VERSION ""

NS_ :

BS_:

BU_: WCM4 WCM3 WCM2 WCM VPM VLM VKM VICM VECM VDM VCU_RTOS_ETH VCU_ENTRY_ETH VCU_AGVM_ETH VCU UVM UPM TIM TEST_TOOL_1 TCP_ETH TCP TCM TCCM SRR_SRR_ETH SRR_SRR SRR_SLR_ETH SRR_SLR SRR_RR SRR_RF_ETH SRR_RF SRR_LR_CR SRR_LF_ETH SRR_LF SIB SDM SCL SBZA_R SBZA_L SBM SAM_RR SAM_RF SAM_LR SAM_LF SAM_BH SADS RadioLow_ETH RadioLow RSI_RTOS_ETH RSI RDCM PTM PLCM PFCM PDR_ETH PDR PCM PA ODS2 ODS NVM MTCM_R MTCM_L MSM_RR MSM_P MSM_LR MSM_D MSB2 MSB1 MRCM_R MRCM_L MFC LRR_RR_ETH LRR_LR_ETH LRR_CF_ETH LRR LRL_CF_ETH LIB_48V LIB1 IPC_INT IPC_GP IPC ICS_Info ICCM HVAC_FP_R HVAC_FP_F HUD_CAN HDLM FPI_RTOS_ETH FPI FOPM FCM_LC FCM EPSb EPS_1 EPSRAb EPSRAa EPS EOCM_HC_Superset EOCM_HCP2 EOCM ELM ECP_X1 ECP_S2 ECP_S ECP_MC ECP_H3 ECP_H2 ECP_H1 ECP_E ECM EBCM DMS DEFC DCM CSM_ETH CSM_AV CSM CGM_OTA_ETH CGM BSM_MH BSM_HEV BSM BCM ARS ARB APA AOS AMP ALC AHS AHL_AFL ADIMb ADIMa ACP2_MCU

BO_ 21 SrlDat199_Prtctd_PDU: 32 SRR_SRR
 SG_ SD199P_MAC : 7|32@0+ (1,0) [0|4.29497e+009] "" SRR_SLR
 SG_ SD199P_FCnt : 39|5@0+ (1,0) [0|31] "" SRR_SLR
 SG_ SRRSRRODPTOVYawRate : 47|11@0+ (0.002,0) [0|4.094] "(rad/s)^2" SRR_SLR
 SG_ SRRSRRODPTrObjYawRate : 52|11@0- (0.002,0) [-2.048|2.046] "rad/s" SRR_SLR
 SG_ SRRSRRODPTrObjOrntn : 57|10@0- (0.01,0) [-5.12|5.11] "rad" SRR_SLR
 SG_ SRRSRRODPTODTrHtchTrFrt : 79|8@0- (0.1,0) [-12.8|12.7] "m" SRR_SLR
 SG_ SRRSRRODPTOVLgth : 87|8@0+ (0.1,0) [0|25.5] "m^2" SRR_SLR
 SG_ SRRSRRODPTOVOrntn : 95|8@0+ (0.01,0) [0|2.55] "rad^2" SRR_SLR
 SG_ SRRSRRODPTOVWdth : 103|8@0+ (0.1,0) [0|25.5] "m^2" SRR_SLR
 SG_ SRRSRRODPTrObjLgth : 111|8@0+ (0.1,0) [0|25.5] "m" SRR_SLR
 SG_ SRRSRRODPTODVhFrtAxVhHtch : 112|7@0+ (0.1,0) [0|12.7] "m" SRR_SLR
 SG_ SRRSRRODPTODTrHtchTrAx : 119|7@0+ (0.1,0) [0|12.7] "m" SRR_SLR
 SG_ SRRSRRODPTOEExistPrblty : 121|7@0+ (0.01,0) [0|1.27] "" SRR_SLR
 SG_ SRRSRRODPTOPDtnPrblty : 130|7@0+ (0.01,0) [0|1.27] "" SRR_SLR
 SG_ SRRSRRODPTrObjQlty : 139|7@0+ (1,0) [0|127] "%" SRR_SLR
 SG_ SRRSRRODPTOVDTrHtchTrAx : 148|6@0+ (0.1,0) [0|6.3] "m^2" SRR_SLR
 SG_ SRRSRRODPTOVDVhFrtAxVhHtch : 152|6@0+ (0.1,0) [0|6.3] "m^2" SRR_SLR
 SG_ SRRSRRODPTOVDTrHtchTrFrt : 158|6@0+ (0.1,0) [0|6.3] "m^2" SRR_SLR
 SG_ SRRSRRODPTrObjWdth : 162|6@0+ (0.1,0) [0|6.3] "m" SRR_SLR
 SG_ SRRSRRODPTrObjStatInfo : 169|3@0+ (1,0) [0|4] "" SRR_SLR
 SG_ SRRSRRODPTrObjExtrnInfo : 172|3@0+ (1,0) [0|7] "" SRR_SLR
 SG_ SRRSRRODPTOPDtnPrblty_Inv : 176|1@0+ (1,0) [0|1] "" SRR_SLR
 SG_ SRRSRRODPTOEExistPrblty_Inv : 177|1@0+ (1,0) [0|1] "" SRR_SLR
 SG_ SRRSRRODPTODVhFrtAxVhHtch_Inv : 178|1@0+ (1,0) [0|1] "" SRR_SLR
 SG_ SRRSRRODPTODTrHtchTrFrt_Inv : 179|1@0+ (1,0) [0|1] "" SRR_SLR
 SG_ SRRSRRODPTODTrHtchTrAx_Inv : 180|1@0+ (1,0) [0|1] "" SRR_SLR
 SG_ SRRSRRODPTrAtchdInfo : 182|2@0+ (1,0) [0|3] "" SRR_SLR
 SG_ SRRSRRODPTrObjExtrnInfo_Inv : 184|1@0+ (1,0) [0|1] "" SRR_SLR
 SG_ SRRSRRODPTOVYawRate_Inv : 185|1@0+ (1,0) [0|1] "" SRR_SLR
 SG_ SRRSRRODPTOVWdth_Inv : 186|1@0+ (1,0) [0|1] "" SRR_SLR
 SG_ SRRSRRODPTOVOrntn_Inv : 187|1@0+ (1,0) [0|1] "" SRR_SLR
 SG_ SRRSRRODPTOVLgth_Inv : 188|1@0+ (1,0) [0|1] "" SRR_SLR
 SG_ SRRSRRODPTOVDVhFrtAxVhHtch_Inv : 189|1@0+ (1,0) [0|1] "" SRR_SLR
 SG_ SRRSRRODPTOVDTrHtchTrFrt_Inv : 190|1@0+ (1,0) [0|1] "" SRR_SLR
 SG_ SRRSRRODPTOVDTrHtchTrAx_Inv : 191|1@0+ (1,0) [0|1] "" SRR_SLR
 SG_ SrlDat199_Filler : 194|32@0+ (1,0) [0|4.29497e+009] "" SRR_SLR
 SG_ SRRSRRODPTrObjYawRate_Inv : 195|1@0+ (1,0) [0|1] "" SRR_SLR
 SG_ SRRSRRODPTrObjWdth_Inv : 196|1@0+ (1,0) [0|1] "" SRR_SLR
 SG_ SRRSRRODPTrObjQlty_Inv : 197|1@0+ (1,0) [0|1] "" SRR_SLR
 SG_ SRRSRRODPTrObjOrntn_Inv : 198|1@0+ (1,0) [0|1] "" SRR_SLR
 SG_ SRRSRRODPTrObjLgth_Inv : 199|1@0+ (1,0) [0|1] "" SRR_SLR
 SG_ SrlDat199_FillerExtnd : 226|25@0+ (1,0) [0|3.35544e+007] "" SRR_SLR
 SG_ SD199P_ARC : 249|2@0+ (1,0) [0|3] "" SRR_SLR

BO_ 543 SrlDat200_PCSM_PDU: 8 SRR_RR
 SG_ SrlDat200_PCSM : 0|64@1+ (1,0) [0|1.84467e+019] "" SRR_LR_CR

BO_ 20 SrlDat200_Prtctd_PDU: 32 SRR_RR
 SG_ SD200P_MAC : 7|32@0+ (1,0) [0|4.29497e+009] "" SRR_LR_CR
 SG_ SD200P_FCnt : 39|5@0+ (1,0) [0|31] "" SRR_LR_CR
 SG_ SRRRRODPTOVYawRate : 47|11@0+ (0.002,0) [0|4.094] "(rad/s)^2" SRR_LR_CR
 SG_ SRRRRODPTrObjYawRate : 52|11@0- (0.002,0) [-2.048|2.046] "rad/s" SRR_LR_CR
 SG_ SRRRRODPTrObjOrntn : 57|10@0- (0.01,0) [-5.12|5.11] "rad" SRR_LR_CR
 SG_ SRRRRODPTODTrHtchTrFrt : 79|8@0- (0.1,0) [-12.8|12.7] "m" SRR_LR_CR
 SG_ SRRRRODPTOVLgth : 87|8@0+ (0.1,0) [0|25.5] "m^2" SRR_LR_CR
 SG_ SRRRRODPTOVOrntn : 95|8@0+ (0.01,0) [0|2.55] "rad^2" SRR_LR_CR
 SG_ SRRRRODPTOVWdth : 103|8@0+ (0.1,0) [0|25.5] "m^2" SRR_LR_CR
 SG_ SRRRRODPTrObjLgth : 111|8@0+ (0.1,0) [0|25.5] "m" SRR_LR_CR
 SG_ SRRRRODPTODVhFrtAxVhHtch : 112|7@0+ (0.1,0) [0|12.7] "m" SRR_LR_CR
 SG_ SRRRRODPTODTrHtchTrAx : 119|7@0+ (0.1,0) [0|12.7] "m" SRR_LR_CR
 SG_ SRRRRODPTOEExistPrblty : 121|7@0+ (0.01,0) [0|1.27] "" SRR_LR_CR
 SG_ SRRRRODPTOPDtnPrblty : 130|7@0+ (0.01,0) [0|1.27] "" SRR_LR_CR
 SG_ SRRRRODPTrObjQlty : 139|7@0+ (1,0) [0|127] "%" SRR_LR_CR
 SG_ SRRRRODPTOVDTrHtchTrAx : 148|6@0+ (0.1,0) [0|6.3] "m^2" SRR_LR_CR
 SG_ SRRRRODPTOVDVhFrtAxVhHtch : 152|6@0+ (0.1,0) [0|6.3] "m^2" SRR_LR_CR
 SG_ SRRRRODPTOVDTrHtchTrFrt : 158|6@0+ (0.1,0) [0|6.3] "m^2" SRR_LR_CR
 SG_ SRRRRODPTrObjWdth : 162|6@0+ (0.1,0) [0|6.3] "m" SRR_LR_CR
 SG_ SRRRRODPTrObjStatInfo : 169|3@0+ (1,0) [0|4] "" SRR_LR_CR
 SG_ SRRRRODPTrObjExtrnInfo : 172|3@0+ (1,0) [0|7] "" SRR_LR_CR
 SG_ SRRRRODPTOPDtnPrblty_Inv : 176|1@0+ (1,0) [0|1] "" SRR_LR_CR
 SG_ SRRRRODPTOEExistPrblty_Inv : 177|1@0+ (1,0) [0|1] "" SRR_LR_CR
 SG_ SRRRRODPTODVhFrtAxVhHtch_Inv : 178|1@0+ (1,0) [0|1] "" SRR_LR_CR
 SG_ SRRRRODPTODTrHtchTrFrt_Inv : 179|1@0+ (1,0) [0|1] "" SRR_LR_CR
 SG_ SRRRRODPTODTrHtchTrAx_Inv : 180|1@0+ (1,0) [0|1] "" SRR_LR_CR
 SG_ SRRRRODPTrAtchdInfo : 182|2@0+ (1,0) [0|3] "" SRR_LR_CR
 SG_ SRRRRODPTrObjExtrnInfo_Inv : 184|1@0+ (1,0) [0|1] "" SRR_LR_CR
 SG_ SRRRRODPTOVYawRate_Inv : 185|1@0+ (1,0) [0|1] "" SRR_LR_CR
 SG_ SRRRRODPTOVWdth_Inv : 186|1@0+ (1,0) [0|1] "" SRR_LR_CR
 SG_ SRRRRODPTOVOrntn_Inv : 187|1@0+ (1,0) [0|1] "" SRR_LR_CR
 SG_ SRRRRODPTOVLgth_Inv : 188|1@0+ (1,0) [0|1] "" SRR_LR_CR
 SG_ SRRRRODPTOVDVhFrtAxVhHtch_Inv : 189|1@0+ (1,0) [0|1] "" SRR_LR_CR
 SG_ SRRRRODPTOVDTrHtchTrFrt_Inv : 190|1@0+ (1,0) [0|1] "" SRR_LR_CR
 SG_ SRRRRODPTOVDTrHtchTrAx_Inv : 191|1@0+ (1,0) [0|1] "" SRR_LR_CR
 SG_ SrlDat200_Filler : 194|32@0+ (1,0) [0|4.29497e+009] "" SRR_LR_CR
 SG_ SRRRRODPTrObjYawRate_Inv : 195|1@0+ (1,0) [0|1] "" SRR_LR_CR
 SG_ SRRRRODPTrObjWdth_Inv : 196|1@0+ (1,0) [0|1] "" SRR_LR_CR
 SG_ SRRRRODPTrObjQlty_Inv : 197|1@0+ (1,0) [0|1] "" SRR_LR_CR
 SG_ SRRRRODPTrObjOrntn_Inv : 198|1@0+ (1,0) [0|1] "" SRR_LR_CR
 SG_ SRRRRODPTrObjLgth_Inv : 199|1@0+ (1,0) [0|1] "" SRR_LR_CR
 SG_ SrlDat200_FillerExtnd : 226|25@0+ (1,0) [0|3.35544e+007] "" SRR_LR_CR
 SG_ SD200P_ARC : 249|2@0+ (1,0) [0|3] "" SRR_LR_CR

BO_ 906 SrlDat20_PCSM_PDU: 8 CGM
 SG_ SrlDat20_PCSM : 0|64@1+ (1,0) [0|1.84467e+019] "" FCM_LC

BO_ 226 SrlDat20_Prtctd_PDU: 20 CGM
 SG_ SD20P_MAC : 7|32@0+ (1,0) [0|4.29497e+009] "" FCM_LC
 SG_ SD20P_FCnt : 39|5@0+ (1,0) [0|31] "" FCM_LC
 SG_ DIATMNP_DrvrIntdAxlTqMnAuth : 47|15@0+ (2,-22534) [-22534|43000] "Nm" FCM_LC
 SG_ DIATMNP_DrvrIntdAxlTqMnAuth_Inv : 48|1@0+ (1,0) [0|1] "" FCM_LC
 SG_ DIATMXP_DrvrIntdAxlTqMxAuth : 63|15@0+ (2,-22534) [-22534|43000] "Nm" FCM_LC
 SG_ DIATMXP_DrvrIntdAxlTqMxAuth_Inv : 64|1@0+ (1,0) [0|1] "" FCM_LC
 SG_ DITP_DrvrIntndAxlTrqAuth : 79|15@0+ (2,-22534) [-22534|43000] "Nm" FCM_LC
 SG_ DITP_DrvrIntndAxlTrqAuth_Inv : 80|1@0+ (1,0) [0|1] "" FCM_LC
 SG_ DITP_DrvrIntndCrksftTrqAuth : 95|12@0+ (0.5,-848) [-848|1199.5] "Nm" FCM_LC
 SG_ VMI1P_AccelActlPstnAuth : 99|8@0+ (0.392157,0) [0|100] "%" FCM_LC,SRR_SLR,SRR_SRR
 SG_ VMI1P_VehTopSpdLimArbdValAuth : 105|8@0+ (2,0) [0|510] "km / h" FCM_LC
 SG_ VMI1P_AccelPedOvrrdActvAuth : 106|1@0+ (1,0) [0|1] "" FCM_LC
 SG_ VMI1P_AccelActlPstnAuth_Inv : 107|1@0+ (1,0) [0|1] "" FCM_LC
 SG_ SD20P_ARC : 112|2@0+ (1,0) [0|3] "" FCM_LC
 SG_ VMI1P_VehTopSpdLimModeActvAuth : 113|1@0+ (1,0) [0|1] "" FCM_LC
 SG_ VehSpdAvgNDrvn : 126|15@0+ (0.015625,0) [0|511.984] "Km/h" FCM_LC
 SG_ SD20P_Filler : 142|23@0+ (1,0) [0|8.38861e+006] "" FCM_LC
 SG_ VehSpdAvgNDrvn_Inv : 143|1@0+ (1,0) [0|1] "" FCM_LC

BO_ 1404 SrlDat22_PCSM_PDU: 8 CGM
 SG_ SrlDat22_PCSM : 0|64@1+ (1,0) [0|1.84467e+019] "" HDLM,UPM

BO_ 879 SrlDat22_Prtctd_PDU: 8 CGM
 SG_ SD22P_MAC : 7|27@0+ (1,0) [0|1.34218e+008] "" HDLM,UPM
 SG_ SD22P_FCnt : 28|5@0+ (1,0) [0|31] "" HDLM,UPM
 SG_ EGI3P_CnvtTpSpLimRspValAuth : 36|8@0+ (2,0) [0|510] "kph" HDLM,UPM
 SG_ EGI3P_CnvtTpSpLimRspTypAuth : 39|3@0+ (1,0) [0|6] "" HDLM,UPM
 SG_ PSP_PrkNeutSwStatAuth_Inv : 40|1@0+ (1,0) [0|1] "" HDLM,UPM
 SG_ PSP_PrkNeutSwStatAuth : 41|1@0+ (1,0) [0|1] "" HDLM,UPM
 SG_ PSP_EngRnngAuth : 42|1@0+ (1,0) [0|1] "" EOCM_HCP2,FCM_LC,HDLM,LRR,SRR_LF,SRR_LR_CR,SRR_RF,SRR_RR,SRR_SLR,SRR_SRR,UPM
 SG_ PSP_ClchBtmTrvlAchvdAuth_Inv : 43|1@0+ (1,0) [0|1] "" HDLM,UPM
 SG_ PSP_ClchBtmTrvlAchvdAuth : 44|1@0+ (1,0) [0|1] "" HDLM,UPM
 SG_ SD22P_ARC : 49|2@0+ (1,0) [0|3] "" HDLM,UPM
 SG_ PSP_VehTheftImbChlgRespStsAuth : 51|2@0+ (1,0) [0|2] "" HDLM,UPM
 SG_ PSP_RmtVehStrtEngRnngAuth : 52|1@0+ (1,0) [0|1] "" HDLM,UPM
 SG_ PSP_PwrtrnCrnkAbrtdAuth : 53|1@0+ (1,0) [0|1] "" HDLM,UPM
 SG_ PSP_PrplSysStlActvAuth : 54|1@0+ (1,0) [0|1] "" HDLM,UPM
 SG_ PSP_PrplSysActvAuth : 55|1@0+ (1,0) [0|1] "" FCM_LC,HDLM,LRR,SRR_LF,SRR_LR_CR,SRR_RF,SRR_RR,SRR_SLR,SRR_SRR,UPM
 SG_ SD22P_Filler : 62|7@0+ (1,0) [0|127] "" HDLM,UPM
 SG_ PrplBrkThrotOvrrdReqd : 63|1@0+ (1,0) [0|1] "" HDLM,UPM

BO_ 72 SrlDat30_Prtctd_PDU: 8 CGM
 SG_ SD30P_MAC : 7|27@0+ (1,0) [0|1.34218e+008] "" Vector__XXX
 SG_ SD30P_FCnt : 28|5@0+ (1,0) [0|31] "" Vector__XXX
 SG_ TGIP_TrnsEgdPrFlwStAuth : 33|3@0+ (1,0) [0|3] "" Vector__XXX
 SG_ TARSP_TransActlRngAuth_Inv : 34|1@0+ (1,0) [0|1] "" Vector__XXX
 SG_ TARSP_TransActlRngAuth_DuD : 35|1@0+ (1,0) [0|1] "" Vector__XXX
 SG_ TARSP_TransActlRngAuth : 39|4@0+ (1,0) [0|13] "" UPM
 SG_ TRDP_TrnsPkRgDgLtFltAuth : 40|1@0+ (1,0) [0|1] "" Vector__XXX
 SG_ TRDP_TrnsPkRgDgCtFltAuth : 41|1@0+ (1,0) [0|1] "" Vector__XXX
 SG_ TRDP_TrnsNtRgDgLtFltAuth : 42|1@0+ (1,0) [0|1] "" Vector__XXX
 SG_ TRDP_TrnsNtRgDgCtFltAuth : 43|1@0+ (1,0) [0|1] "" Vector__XXX
 SG_ TRDP_TrnsFwDrvRDLFltAuth : 44|1@0+ (1,0) [0|1] "" Vector__XXX
 SG_ TRDP_TrnsFwDrvRDCFltAuth : 45|1@0+ (1,0) [0|1] "" Vector__XXX
 SG_ TGIP_TrnsEgdPrFlwStAuth_Inv : 46|1@0+ (1,0) [0|1] "" Vector__XXX
 SG_ SD30P_Filler : 49|10@0+ (1,0) [0|1023] "" Vector__XXX
 SG_ SD30P_ARC : 51|2@0+ (1,0) [0|3] "" Vector__XXX
 SG_ TSP_TmpDrvrShfCtlActvAuth : 52|1@0+ (1,0) [0|1] "" Vector__XXX
 SG_ TSP_ElecRngSeltnInDrvActvAuth : 53|1@0+ (1,0) [0|1] "" Vector__XXX
 SG_ TRDP_TrnsRvRgDgLtFltAuth : 54|1@0+ (1,0) [0|1] "" Vector__XXX
 SG_ TRDP_TrnsRvRgDgCtFltAuth : 55|1@0+ (1,0) [0|1] "" Vector__XXX

BO_ 897 SrlDat46_PCSM_PDU: 8 CGM
 SG_ SrlDat46_PCSM : 0|64@1+ (1,0) [0|1.84467e+019] "" ACP2_MCU,FCM_LC

BO_ 57 SrlDat46_Prtctd_PDU: 20 CGM
 SG_ SD46P_MAC : 7|32@0+ (1,0) [0|4.29497e+009] "" ACP2_MCU,FCM_LC
 SG_ SD46P_FCnt : 39|5@0+ (1,0) [0|31] "" ACP2_MCU,FCM_LC
 SG_ LatAccelAuth : 47|10@0- (0.0625,0) [-32|31.9375] "m/s^2" ACP2_MCU,FCM_LC
 SG_ LongAccelAuth : 50|10@0- (0.0625,0) [-32|31.9375] "m/s^2" ACP2_MCU,FCM_LC
 SG_ LatAccelSnsrCorrStsAuth : 52|2@0+ (1,0) [0|3] "" ACP2_MCU,FCM_LC
 SG_ LatAccelAuth_Inv : 53|1@0+ (1,0) [0|1] "" ACP2_MCU,FCM_LC
 SG_ LongAccelAuth_Inv : 56|1@0+ (1,0) [0|1] "" ACP2_MCU,FCM_LC
 SG_ YRP_RollRateAuth : 68|13@0- (0.024,0) [-98.304|98.28] "Deg/Sec" ACP2_MCU,FCM_LC
 SG_ VehAccelCalAuth : 69|1@0+ (1,0) [0|1] "" ACP2_MCU,FCM_LC
 SG_ LongAccelSnsrCorrStsAuth : 71|2@0+ (1,0) [0|3] "" ACP2_MCU,FCM_LC
 SG_ YawRateAuth : 85|13@0- (0.024,0) [-98.304|98.28] "Deg/Sec" ACP2_MCU,FCM_LC,SRR_LR_CR,SRR_RR,SRR_SLR,SRR_SRR
 SG_ YRP_RollRateAuth_Inv : 86|1@0+ (1,0) [0|1] "" ACP2_MCU,FCM_LC
 SG_ YRP_RollRateAuth_DuD : 87|1@0+ (1,0) [0|1] "" ACP2_MCU,FCM_LC
 SG_ YawRateAuth_DuD : 88|1@0+ (1,0) [0|1] "" ACP2_MCU,FCM_LC
 SG_ SD46P_Filler : 98|32@0+ (1,0) [0|4.29497e+009] "" ACP2_MCU,FCM_LC
 SG_ SD46P_ARC : 100|2@0+ (1,0) [0|3] "" ACP2_MCU,FCM_LC
 SG_ YawRateCorrAuth : 102|2@0+ (1,0) [0|3] "" ACP2_MCU,FCM_LC
 SG_ YawRateAuth_Inv : 103|1@0+ (1,0) [0|1] "" ACP2_MCU,FCM_LC,SRR_LR_CR,SRR_RR,SRR_SLR,SRR_SRR
 SG_ SD46P_FillerExtnd : 130|26@0+ (1,0) [0|6.71089e+007] "" ACP2_MCU,FCM_LC
 SG_ VehAccelAuth_DuD : 152|1@0+ (1,0) [0|1] "" ACP2_MCU,FCM_LC

BO_ 1403 SysPwrMode_PCSM_PDU: 8 CGM
 SG_ SysPwrMode_PCSM : 0|64@1+ (1,0) [0|1.84467e+019] "" EOCM_HCP2,FCM_LC,HDLM,LRR,SRR_LF,SRR_LR_CR,SRR_RF,SRR_RR,SRR_SLR,SRR_SRR,UPM

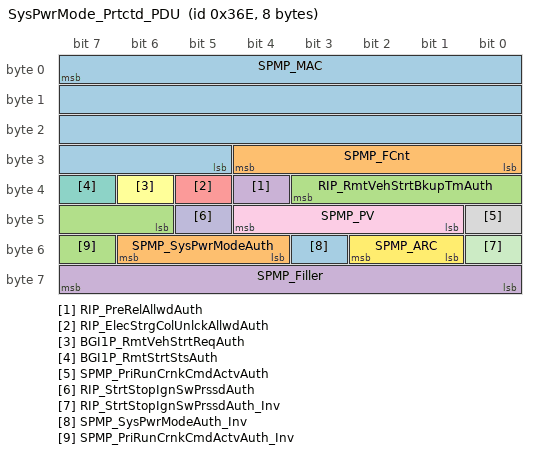
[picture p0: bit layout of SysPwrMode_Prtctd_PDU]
BO_ 878 SysPwrMode_Prtctd_PDU: 8 CGM
 SG_ SPMP_MAC : 7|27@0+ (1,0) [0|1.34218e+008] "" EOCM_HCP2,FCM_LC,HDLM,LRR,SRR_LF,SRR_LR_CR,SRR_RF,SRR_RR,SRR_SLR,SRR_SRR,UPM
 SG_ SPMP_FCnt : 28|5@0+ (1,0) [0|31] "" EOCM_HCP2,FCM_LC,HDLM,LRR,SRR_LF,SRR_LR_CR,SRR_RF,SRR_RR,SRR_SLR,SRR_SRR,UPM
 SG_ RIP_RmtVehStrtBkupTmAuth : 35|6@0+ (1,0) [0|63] "min" EOCM_HCP2,FCM_LC,HDLM,LRR,SRR_LF,SRR_LR_CR,SRR_RF,SRR_RR,SRR_SLR,SRR_SRR,UPM
 SG_ RIP_PreRelAllwdAuth : 36|1@0+ (1,0) [0|1] "" EOCM_HCP2,FCM_LC,HDLM,LRR,SRR_LF,SRR_LR_CR,SRR_RF,SRR_RR,SRR_SLR,SRR_SRR,UPM
 SG_ RIP_ElecStrgColUnlckAllwdAuth : 37|1@0+ (1,0) [0|1] "" EOCM_HCP2,FCM_LC,HDLM,LRR,SRR_LF,SRR_LR_CR,SRR_RF,SRR_RR,SRR_SLR,SRR_SRR,UPM
 SG_ BGI1P_RmtVehStrtReqAuth : 38|1@0+ (1,0) [0|1] "" EOCM_HCP2,FCM_LC,HDLM,LRR,SRR_LF,SRR_LR_CR,SRR_RF,SRR_RR,SRR_SLR,SRR_SRR,UPM
 SG_ BGI1P_RmtStrtStsAuth : 39|1@0+ (1,0) [0|1] "" EOCM_HCP2,FCM_LC,HDLM,LRR,SRR_LF,SRR_LR_CR,SRR_RF,SRR_RR,SRR_SLR,SRR_SRR,UPM
 SG_ SPMP_PriRunCrnkCmdActvAuth : 40|1@0+ (1,0) [0|1] "" EOCM_HCP2,FCM_LC,HDLM,LRR,SRR_LF,SRR_LR_CR,SRR_RF,SRR_RR,SRR_SLR,SRR_SRR,UPM
 SG_ SPMP_PV : 44|4@0+ (1,0) [0|15] "" EOCM_HCP2,FCM_LC,HDLM,LRR,SRR_LF,SRR_LR_CR,SRR_RF,SRR_RR,SRR_SLR,SRR_SRR,UPM
 SG_ RIP_StrtStopIgnSwPrssdAuth : 45|1@0+ (1,0) [0|1] "" EOCM_HCP2,FCM_LC,HDLM,LRR,SRR_LF,SRR_LR_CR,SRR_RF,SRR_RR,SRR_SLR,SRR_SRR,UPM
 SG_ RIP_StrtStopIgnSwPrssdAuth_Inv : 48|1@0+ (1,0) [0|1] "" EOCM_HCP2,FCM_LC,HDLM,LRR,SRR_LF,SRR_LR_CR,SRR_RF,SRR_RR,SRR_SLR,SRR_SRR,UPM
 SG_ SPMP_ARC : 50|2@0+ (1,0) [0|3] "" EOCM_HCP2,FCM_LC,HDLM,LRR,SRR_LF,SRR_LR_CR,SRR_RF,SRR_RR,SRR_SLR,SRR_SRR,UPM
 SG_ SPMP_SysPwrModeAuth_Inv : 51|1@0+ (1,0) [0|1] "" EOCM_HCP2,FCM_LC,HDLM,LRR,SRR_LF,SRR_LR_CR,SRR_RF,SRR_RR,SRR_SLR,SRR_SRR,UPM
 SG_ SPMP_SysPwrModeAuth : 54|3@0+ (1,0) [0|4] "" EOCM_HCP2,FCM_LC,HDLM,LRR,SRR_LF,SRR_LR_CR,SRR_RF,SRR_RR,SRR_SLR,SRR_SRR,UPM
 SG_ SPMP_PriRunCrnkCmdActvAuth_Inv : 55|1@0+ (1,0) [0|1] "" EOCM_HCP2,FCM_LC,HDLM,LRR,SRR_LF,SRR_LR_CR,SRR_RF,SRR_RR,SRR_SLR,SRR_SRR,UPM
 SG_ SPMP_Filler : 63|8@0+ (1,0) [0|255] "" EOCM_HCP2,FCM_LC,HDLM,LRR,SRR_LF,SRR_LR_CR,SRR_RF,SRR_RR,SRR_SLR,SRR_SRR,UPM

BO_ 122 Tp_SrlDat185_Data_PDU: 2680 SRR_LR_CR
 SG_ SRRLRCODPREOTk1CrvAuth : 7|16@0- (9.77e-07,0) [-0.0320143|0.0320134] "1/m" Vector__XXX
 SG_ SRRLRCODPREOTk1CrvDrvtAuth : 23|16@0- (3.73e-09,0) [-0.000122225|0.000122221] "1/m2" Vector__XXX
 SG_ SRRLRCODPREOTk2CrvAuth : 39|16@0- (9.77e-07,0) [-0.0320143|0.0320134] "1/m" Vector__XXX
 SG_ SRRLRCODPREOTk2CrvDrvtAuth : 55|16@0- (3.73e-09,0) [-0.000122225|0.000122221] "1/m2" Vector__XXX
 SG_ SRRLRCODPREOTk3CrvAuth : 71|16@0- (9.77e-07,0) [-0.0320143|0.0320134] "1/m" Vector__XXX
 SG_ SRRLRCODPREOTk3CrvDrvtAuth : 87|16@0- (3.73e-09,0) [-0.000122225|0.000122221] "1/m2" Vector__XXX
 SG_ SRRLRCODPVOTk10PoILgPsCAuth : 103|16@0+ (0.01,0) [0|655.35] "m^2" Vector__XXX
 SG_ SRRLRCODPVOTk1PoILgPsCAuth : 119|16@0+ (0.01,0) [0|655.35] "m^2" Vector__XXX
 SG_ SRRLRCODPVOTk2PoILgPsCAuth : 135|16@0+ (0.01,0) [0|655.35] "m^2" Vector__XXX
 SG_ SRRLRCODPVOTk3PoILgPsCAuth : 151|16@0+ (0.01,0) [0|655.35] "m^2" Vector__XXX
 SG_ SRRLRCODPVOTk4PoILgPsCAuth : 167|16@0+ (0.01,0) [0|655.35] "m^2" Vector__XXX
 SG_ SRRLRCODPVOTk5PoILgPsCAuth : 183|16@0+ (0.01,0) [0|655.35] "m^2" Vector__XXX
 SG_ SRRLRCODPVOTk6PoILgPsCAuth : 199|16@0+ (0.01,0) [0|655.35] "m^2" Vector__XXX
 SG_ SRRLRCODPVOTk7PoILgPsCAuth : 215|16@0+ (0.01,0) [0|655.35] "m^2" Vector__XXX
 SG_ SRRLRCODPVOTk8PoILgPsCAuth : 231|16@0+ (0.01,0) [0|655.35] "m^2" Vector__XXX
 SG_ SRRLRCODPVOTk9PoILgPsCAuth : 247|16@0+ (0.01,0) [0|655.35] "m^2" Vector__XXX
 SG_ SRRLRCODPVOTk10PoILPsCAuth : 263|14@0+ (0.01,0) [0|163.83] "m^2" Vector__XXX
 SG_ SRRLRCODPVOTk1PoILPsCAuth : 265|14@0+ (0.01,0) [0|163.83] "m^2" Vector__XXX
 SG_ SRRLRCODPVOTk2PoILPsCAuth : 283|14@0+ (0.01,0) [0|163.83] "m^2" Vector__XXX
 SG_ SRRLRCODPVOTk3PoILPsCAuth : 301|14@0+ (0.01,0) [0|163.83] "m^2" Vector__XXX
 SG_ SRRLRCODPVOTk4PoILPsCAuth : 319|14@0+ (0.01,0) [0|163.83] "m^2" Vector__XXX
 SG_ SRRLRCODPVOTk5PoILPsCAuth : 321|14@0+ (0.01,0) [0|163.83] "m^2" Vector__XXX
 SG_ SRRLRCODPVOTk6PoILPsCAuth : 339|14@0+ (0.01,0) [0|163.83] "m^2" Vector__XXX
 SG_ SRRLRCODPVOTk7PoILPsCAuth : 357|14@0+ (0.01,0) [0|163.83] "m^2" Vector__XXX
 SG_ SRRLRCODPVOTk8PoILPsCAuth : 375|14@0+ (0.01,0) [0|163.83] "m^2" Vector__XXX
 SG_ SRRLRCODPVOTk9PoILPsCAuth : 377|14@0+ (0.01,0) [0|163.83] "m^2" Vector__XXX
 SG_ SRRLRCODPAcqTmStmAuth : 395|11@0+ (1,0) [0|2047] "ms" Vector__XXX
 SG_ SRRLRCODPIOTk10PoILgPsAuth : 400|11@0- (0.125,0) [-128|127.875] "m" Vector__XXX
 SG_ SRRLRCODPIOTk1PoILgPsAuth : 421|11@0- (0.125,0) [-128|127.875] "m" Vector__XXX
 SG_ SRRLRCODPIOTk2PoILgPsAuth : 426|11@0- (0.125,0) [-128|127.875] "m" Vector__XXX
 SG_ SRRLRCODPIOTk3PoILgPsAuth : 447|11@0- (0.125,0) [-128|127.875] "m" Vector__XXX
 SG_ SRRLRCODPIOTk4PoILgPsAuth : 452|11@0- (0.125,0) [-128|127.875] "m" Vector__XXX
 SG_ SRRLRCODPIOTk5PoILgPsAuth : 457|11@0- (0.125,0) [-128|127.875] "m" Vector__XXX
 SG_ SRRLRCODPIOTk6PoILgPsAuth : 478|11@0- (0.125,0) [-128|127.875] "m" Vector__XXX
 SG_ SRRLRCODPIOTk7PoILgPsAuth : 483|11@0- (0.125,0) [-128|127.875] "m" Vector__XXX
 SG_ SRRLRCODPIOTk8PoILgPsAuth : 488|11@0- (0.125,0) [-128|127.875] "m" Vector__XXX
 SG_ SRRLRCODPIOTk9PoILgPsAuth : 509|11@0- (0.125,0) [-128|127.875] "m" Vector__XXX
 SG_ SRRLRCODPPOTk1PoILgPsAuth : 514|11@0- (0.125,0) [-128|127.875] "m" Vector__XXX
 SG_ SRRLRCODPPOTk2PoILgPsAuth : 535|11@0- (0.125,0) [-128|127.875] "m" Vector__XXX
 SG_ SRRLRCODPPOTk3PoILgPsAuth : 540|11@0- (0.125,0) [-128|127.875] "m" Vector__XXX
 SG_ SRRLRCODPPOTk4PoILgPsAuth : 545|11@0- (0.125,0) [-128|127.875] "m" Vector__XXX
 SG_ SRRLRCODPPOTk5PoILgPsAuth : 566|11@0- (0.125,0) [-128|127.875] "m" Vector__XXX
 SG_ SRRLRCODPREOTk1PsEndAuth : 571|11@0- (0.125,0) [-128|127.875] "m" Vector__XXX
 SG_ SRRLRCODPREOTk1PsStrtAuth : 576|11@0- (0.125,0) [-128|127.875] "m" Vector__XXX
 SG_ SRRLRCODPREOTk2PsEndAuth : 597|11@0- (0.125,0) [-128|127.875] "m" Vector__XXX
 SG_ SRRLRCODPREOTk2PsStrtAuth : 602|11@0- (0.125,0) [-128|127.875] "m" Vector__XXX
 SG_ SRRLRCODPREOTk3PsEndAuth : 623|11@0- (0.125,0) [-128|127.875] "m" Vector__XXX
 SG_ SRRLRCODPREOTk3PsStrtAuth : 628|11@0- (0.125,0) [-128|127.875] "m" Vector__XXX
 SG_ SRRLRCODPVOTk10PoI2LgPsAuth : 633|11@0- (0.125,0) [-128|127.875] "m" Vector__XXX
 SG_ SRRLRCODPVOTk10PoILgPsAuth : 654|11@0- (0.125,0) [-128|127.875] "m" Vector__XXX
 SG_ SRRLRCODPVOTk10PoILgVAuth : 659|11@0- (0.125,0) [-128|127.875] "m/s" Vector__XXX
 SG_ SRRLRCODPVOTk1PoI2LgPsAuth : 664|11@0- (0.125,0) [-128|127.875] "m" Vector__XXX
 SG_ SRRLRCODPVOTk1PoILgPsAuth : 685|11@0- (0.125,0) [-128|127.875] "m" Vector__XXX
 SG_ SRRLRCODPVOTk1PoILgVAuth : 690|11@0- (0.125,0) [-128|127.875] "m/s" Vector__XXX
 SG_ SRRLRCODPVOTk2PoI2LgPsAuth : 711|11@0- (0.125,0) [-128|127.875] "m" Vector__XXX
 SG_ SRRLRCODPVOTk2PoILgPsAuth : 716|11@0- (0.125,0) [-128|127.875] "m" Vector__XXX
 SG_ SRRLRCODPVOTk2PoILgVAuth : 721|11@0- (0.125,0) [-128|127.875] "m/s" Vector__XXX
 SG_ SRRLRCODPVOTk3PoI2LgPsAuth : 742|11@0- (0.125,0) [-128|127.875] "m" Vector__XXX
 SG_ SRRLRCODPVOTk3PoILgPsAuth : 747|11@0- (0.125,0) [-128|127.875] "m" Vector__XXX
 SG_ SRRLRCODPVOTk3PoILgVAuth : 752|11@0- (0.125,0) [-128|127.875] "m/s" Vector__XXX
 SG_ SRRLRCODPVOTk4PoI2LgPsAuth : 773|11@0- (0.125,0) [-128|127.875] "m" Vector__XXX
 SG_ SRRLRCODPVOTk4PoILgPsAuth : 778|11@0- (0.125,0) [-128|127.875] "m" Vector__XXX
 SG_ SRRLRCODPVOTk4PoILgVAuth : 799|11@0- (0.125,0) [-128|127.875] "m/s" Vector__XXX
 SG_ SRRLRCODPVOTk5PoI2LgPsAuth : 804|11@0- (0.125,0) [-128|127.875] "m" Vector__XXX
 SG_ SRRLRCODPVOTk5PoILgPsAuth : 809|11@0- (0.125,0) [-128|127.875] "m" Vector__XXX
 SG_ SRRLRCODPVOTk5PoILgVAuth : 830|11@0- (0.125,0) [-128|127.875] "m/s" Vector__XXX
 SG_ SRRLRCODPVOTk6PoI2LgPsAuth : 835|11@0- (0.125,0) [-128|127.875] "m" Vector__XXX
 SG_ SRRLRCODPVOTk6PoILgPsAuth : 840|11@0- (0.125,0) [-128|127.875] "m" Vector__XXX
 SG_ SRRLRCODPVOTk6PoILgVAuth : 861|11@0- (0.125,0) [-128|127.875] "m/s" Vector__XXX
 SG_ SRRLRCODPVOTk7PoI2LgPsAuth : 866|11@0- (0.125,0) [-128|127.875] "m" Vector__XXX
 SG_ SRRLRCODPVOTk7PoILgPsAuth : 887|11@0- (0.125,0) [-128|127.875] "m" Vector__XXX
 SG_ SRRLRCODPVOTk7PoILgVAuth : 892|11@0- (0.125,0) [-128|127.875] "m/s" Vector__XXX
 SG_ SRRLRCODPVOTk8PoI2LgPsAuth : 897|11@0- (0.125,0) [-128|127.875] "m" Vector__XXX
 SG_ SRRLRCODPVOTk8PoILgPsAuth : 918|11@0- (0.125,0) [-128|127.875] "m" Vector__XXX
 SG_ SRRLRCODPVOTk8PoILgVAuth : 923|11@0- (0.125,0) [-128|127.875] "m/s" Vector__XXX
 SG_ SRRLRCODPVOTk9PoI2LgPsAuth : 928|11@0- (0.125,0) [-128|127.875] "m" Vector__XXX
 SG_ SRRLRCODPVOTk9PoILgPsAuth : 949|11@0- (0.125,0) [-128|127.875] "m" Vector__XXX
 SG_ SRRLRCODPVOTk9PoILgVAuth : 954|11@0- (0.125,0) [-128|127.875] "m/s" Vector__XXX
 SG_ SRRLRCODPIOTk10PoILPsAuth : 975|10@0- (0.125,0) [-64|63.875] "m" Vector__XXX
 SG_ SRRLRCODPIOTk1PoILPsAuth : 981|10@0- (0.125,0) [-64|63.875] "m" Vector__XXX
 SG_ SRRLRCODPIOTk2PoILPsAuth : 987|10@0- (0.125,0) [-64|63.875] "m" Vector__XXX
 SG_ SRRLRCODPIOTk3PoILPsAuth : 993|10@0- (0.125,0) [-64|63.875] "m" Vector__XXX
 SG_ SRRLRCODPIOTk4PoILPsAuth : 1015|10@0- (0.125,0) [-64|63.875] "m" Vector__XXX
 SG_ SRRLRCODPIOTk5PoILPsAuth : 1021|10@0- (0.125,0) [-64|63.875] "m" Vector__XXX
 SG_ SRRLRCODPIOTk6PoILPsAuth : 1027|10@0- (0.125,0) [-64|63.875] "m" Vector__XXX
 SG_ SRRLRCODPIOTk7PoILPsAuth : 1033|10@0- (0.125,0) [-64|63.875] "m" Vector__XXX
 SG_ SRRLRCODPIOTk8PoILPsAuth : 1055|10@0- (0.125,0) [-64|63.875] "m" Vector__XXX
 SG_ SRRLRCODPIOTk9PoILPsAuth : 1061|10@0- (0.125,0) [-64|63.875] "m" Vector__XXX
 SG_ SRRLRCODPPOTk1PoILPsAuth : 1067|10@0- (0.125,0) [-64|63.875] "m" Vector__XXX
 SG_ SRRLRCODPPOTk1PoILgVAuth : 1073|10@0- (0.125,0) [-64|63.875] "m/s" Vector__XXX
 SG_ SRRLRCODPPOTk2PoILPsAuth : 1095|10@0- (0.125,0) [-64|63.875] "m" Vector__XXX
 SG_ SRRLRCODPPOTk2PoILgVAuth : 1101|10@0- (0.125,0) [-64|63.875] "m/s" Vector__XXX
 SG_ SRRLRCODPPOTk3PoILPsAuth : 1107|10@0- (0.125,0) [-64|63.875] "m" Vector__XXX
 SG_ SRRLRCODPPOTk3PoILgVAuth : 1113|10@0- (0.125,0) [-64|63.875] "m/s" Vector__XXX
 SG_ SRRLRCODPPOTk4PoILPsAuth : 1135|10@0- (0.125,0) [-64|63.875] "m" Vector__XXX
 SG_ SRRLRCODPPOTk4PoILgVAuth : 1141|10@0- (0.125,0) [-64|63.875] "m/s" Vector__XXX
 SG_ SRRLRCODPPOTk5PoILPsAuth : 1147|10@0- (0.125,0) [-64|63.875] "m" Vector__XXX
 SG_ SRRLRCODPPOTk5PoILgVAuth : 1153|10@0- (0.125,0) [-64|63.875] "m/s" Vector__XXX
 SG_ SRRLRCODPREOTk1HdgAuth : 1175|10@0- (0.000977,0) [-0.500224|0.499247] "rad" Vector__XXX
 SG_ SRRLRCODPREOTk2HdgAuth : 1181|10@0- (0.000977,0) [-0.500224|0.499247] "rad" Vector__XXX
 SG_ SRRLRCODPREOTk3HdgAuth : 1187|10@0- (0.000977,0) [-0.500224|0.499247] "rad" Vector__XXX
 SG_ SRRLRCODPVOTk10PoI2LPsAuth : 1193|10@0- (0.125,0) [-64|63.875] "m" Vector__XXX
 SG_ SRRLRCODPVOTk10PoILPsAuth : 1215|10@0- (0.125,0) [-64|63.875] "m" Vector__XXX
 SG_ SRRLRCODPVOTk10PoILVCAuth : 1221|10@0+ (0.125,0) [0|127.875] "(m/s)^2" Vector__XXX
 SG_ SRRLRCODPVOTk10PoILgVCAuth : 1227|10@0+ (0.125,0) [0|127.875] "(m/s)^2" Vector__XXX
 SG_ SRRLRCODPVOTk1PoI2LPsAuth : 1233|10@0- (0.125,0) [-64|63.875] "m" Vector__XXX
 SG_ SRRLRCODPVOTk1PoILPsAuth : 1255|10@0- (0.125,0) [-64|63.875] "m" Vector__XXX
 SG_ SRRLRCODPVOTk1PoILVCAuth : 1261|10@0+ (0.125,0) [0|127.875] "(m/s)^2" Vector__XXX
 SG_ SRRLRCODPVOTk1PoILgVCAuth : 1267|10@0+ (0.125,0) [0|127.875] "(m/s)^2" Vector__XXX
 SG_ SRRLRCODPVOTk2PoI2LPsAuth : 1273|10@0- (0.125,0) [-64|63.875] "m" Vector__XXX
 SG_ SRRLRCODPVOTk2PoILPsAuth : 1295|10@0- (0.125,0) [-64|63.875] "m" Vector__XXX
 SG_ SRRLRCODPVOTk2PoILVCAuth : 1301|10@0+ (0.125,0) [0|127.875] "(m/s)^2" Vector__XXX
 SG_ SRRLRCODPVOTk2PoILgVCAuth : 1307|10@0+ (0.125,0) [0|127.875] "(m/s)^2" Vector__XXX
 SG_ SRRLRCODPVOTk3PoI2LPsAuth : 1313|10@0- (0.125,0) [-64|63.875] "m" Vector__XXX
 SG_ SRRLRCODPVOTk3PoILPsAuth : 1335|10@0- (0.125,0) [-64|63.875] "m" Vector__XXX
 SG_ SRRLRCODPVOTk3PoILVCAuth : 1341|10@0+ (0.125,0) [0|127.875] "(m/s)^2" Vector__XXX
 SG_ SRRLRCODPVOTk3PoILgVCAuth : 1347|10@0+ (0.125,0) [0|127.875] "(m/s)^2" Vector__XXX
 SG_ SRRLRCODPVOTk4PoI2LPsAuth : 1353|10@0- (0.125,0) [-64|63.875] "m" Vector__XXX
 SG_ SRRLRCODPVOTk4PoILPsAuth : 1375|10@0- (0.125,0) [-64|63.875] "m" Vector__XXX
 SG_ SRRLRCODPVOTk4PoILVCAuth : 1381|10@0+ (0.125,0) [0|127.875] "(m/s)^2" Vector__XXX
 SG_ SRRLRCODPVOTk4PoILgVCAuth : 1387|10@0+ (0.125,0) [0|127.875] "(m/s)^2" Vector__XXX
 SG_ SRRLRCODPVOTk5PoI2LPsAuth : 1393|10@0- (0.125,0) [-64|63.875] "m" Vector__XXX
 SG_ SRRLRCODPVOTk5PoILPsAuth : 1415|10@0- (0.125,0) [-64|63.875] "m" Vector__XXX
 SG_ SRRLRCODPVOTk5PoILVCAuth : 1421|10@0+ (0.125,0) [0|127.875] "(m/s)^2" Vector__XXX
 SG_ SRRLRCODPVOTk5PoILgVCAuth : 1427|10@0+ (0.125,0) [0|127.875] "(m/s)^2" Vector__XXX
 SG_ SRRLRCODPVOTk6PoI2LPsAuth : 1433|10@0- (0.125,0) [-64|63.875] "m" Vector__XXX
 SG_ SRRLRCODPVOTk6PoILPsAuth : 1455|10@0- (0.125,0) [-64|63.875] "m" Vector__XXX
 SG_ SRRLRCODPVOTk6PoILVCAuth : 1461|10@0+ (0.125,0) [0|127.875] "(m/s)^2" Vector__XXX
 SG_ SRRLRCODPVOTk6PoILgVCAuth : 1467|10@0+ (0.125,0) [0|127.875] "(m/s)^2" Vector__XXX
 SG_ SRRLRCODPVOTk7PoI2LPsAuth : 1473|10@0- (0.125,0) [-64|63.875] "m" Vector__XXX
 SG_ SRRLRCODPVOTk7PoILPsAuth : 1495|10@0- (0.125,0) [-64|63.875] "m" Vector__XXX
 SG_ SRRLRCODPVOTk7PoILVCAuth : 1501|10@0+ (0.125,0) [0|127.875] "(m/s)^2" Vector__XXX
 SG_ SRRLRCODPVOTk7PoILgVCAuth : 1507|10@0+ (0.125,0) [0|127.875] "(m/s)^2" Vector__XXX
 SG_ SRRLRCODPVOTk8PoI2LPsAuth : 1513|10@0- (0.125,0) [-64|63.875] "m" Vector__XXX
 SG_ SRRLRCODPVOTk8PoILPsAuth : 1535|10@0- (0.125,0) [-64|63.875] "m" Vector__XXX
 SG_ SRRLRCODPVOTk8PoILVCAuth : 1541|10@0+ (0.125,0) [0|127.875] "(m/s)^2" Vector__XXX
 SG_ SRRLRCODPVOTk8PoILgVCAuth : 1547|10@0+ (0.125,0) [0|127.875] "(m/s)^2" Vector__XXX
 SG_ SRRLRCODPVOTk9PoI2LPsAuth : 1553|10@0- (0.125,0) [-64|63.875] "m" Vector__XXX
 SG_ SRRLRCODPVOTk9PoILPsAuth : 1575|10@0- (0.125,0) [-64|63.875] "m" Vector__XXX
 SG_ SRRLRCODPVOTk9PoILVCAuth : 1581|10@0+ (0.125,0) [0|127.875] "(m/s)^2" Vector__XXX
 SG_ SRRLRCODPVOTk9PoILgVCAuth : 1587|10@0+ (0.125,0) [0|127.875] "(m/s)^2" Vector__XXX
 SG_ SRRLRCODPPOTk1PoILAAuth : 1593|9@0- (0.125,0) [-32|31.875] "m/s^2" Vector__XXX
 SG_ SRRLRCODPPOTk1PoILVAuth : 1600|9@0- (0.125,0) [-32|31.875] "m/s" Vector__XXX
 SG_ SRRLRCODPPOTk1PoILgAAuth : 1623|9@0- (0.125,0) [-32|31.875] "m/s^2" Vector__XXX
 SG_ SRRLRCODPPOTk2PoILAAuth : 1630|9@0- (0.125,0) [-32|31.875] "m/s^2" Vector__XXX
 SG_ SRRLRCODPPOTk2PoILVAuth : 1637|9@0- (0.125,0) [-32|31.875] "m/s" Vector__XXX
 SG_ SRRLRCODPPOTk2PoILgAAuth : 1644|9@0- (0.125,0) [-32|31.875] "m/s^2" Vector__XXX
 SG_ SRRLRCODPPOTk3PoILAAuth : 1651|9@0- (0.125,0) [-32|31.875] "m/s^2" Vector__XXX
 SG_ SRRLRCODPPOTk3PoILVAuth : 1658|9@0- (0.125,0) [-32|31.875] "m/s" Vector__XXX
 SG_ SRRLRCODPPOTk3PoILgAAuth : 1665|9@0- (0.125,0) [-32|31.875] "m/s^2" Vector__XXX
 SG_ SRRLRCODPPOTk4PoILAAuth : 1672|9@0- (0.125,0) [-32|31.875] "m/s^2" Vector__XXX
 SG_ SRRLRCODPPOTk4PoILVAuth : 1695|9@0- (0.125,0) [-32|31.875] "m/s" Vector__XXX
 SG_ SRRLRCODPPOTk4PoILgAAuth : 1702|9@0- (0.125,0) [-32|31.875] "m/s^2" Vector__XXX
 SG_ SRRLRCODPPOTk5PoILAAuth : 1709|9@0- (0.125,0) [-32|31.875] "m/s^2" Vector__XXX
 SG_ SRRLRCODPPOTk5PoILVAuth : 1716|9@0- (0.125,0) [-32|31.875] "m/s" Vector__XXX
 SG_ SRRLRCODPPOTk5PoILgAAuth : 1723|9@0- (0.125,0) [-32|31.875] "m/s^2" Vector__XXX
 SG_ SRRLRCODPREOTk1OfstAuth : 1730|9@0- (0.125,0) [-32|31.875] "m" Vector__XXX
 SG_ SRRLRCODPREOTk2OfstAuth : 1737|9@0- (0.125,0) [-32|31.875] "m" Vector__XXX
 SG_ SRRLRCODPREOTk3OfstAuth : 1744|9@0- (0.125,0) [-32|31.875] "m" Vector__XXX
 SG_ SRRLRCODPVOTk10PoILAAuth : 1767|9@0- (0.125,0) [-32|31.875] "m/s^2" Vector__XXX
 SG_ SRRLRCODPVOTk10PoILVAuth : 1774|9@0- (0.125,0) [-32|31.875] "m/s" Vector__XXX
 SG_ SRRLRCODPVOTk10PoILgAAuth : 1781|9@0- (0.125,0) [-32|31.875] "m/s^2" Vector__XXX
 SG_ SRRLRCODPVOTk1PoILAAuth : 1788|9@0- (0.125,0) [-32|31.875] "m/s^2" Vector__XXX
 SG_ SRRLRCODPVOTk1PoILVAuth : 1795|9@0- (0.125,0) [-32|31.875] "m/s" Vector__XXX
 SG_ SRRLRCODPVOTk1PoILgAAuth : 1802|9@0- (0.125,0) [-32|31.875] "m/s^2" Vector__XXX
 SG_ SRRLRCODPVOTk2PoILAAuth : 1809|9@0- (0.125,0) [-32|31.875] "m/s^2" Vector__XXX
 SG_ SRRLRCODPVOTk2PoILVAuth : 1816|9@0- (0.125,0) [-32|31.875] "m/s" Vector__XXX
 SG_ SRRLRCODPVOTk2PoILgAAuth : 1839|9@0- (0.125,0) [-32|31.875] "m/s^2" Vector__XXX
 SG_ SRRLRCODPVOTk3PoILAAuth : 1846|9@0- (0.125,0) [-32|31.875] "m/s^2" Vector__XXX
 SG_ SRRLRCODPVOTk3PoILVAuth : 1853|9@0- (0.125,0) [-32|31.875] "m/s" Vector__XXX
 SG_ SRRLRCODPVOTk3PoILgAAuth : 1860|9@0- (0.125,0) [-32|31.875] "m/s^2" Vector__XXX
 SG_ SRRLRCODPVOTk4PoILAAuth : 1867|9@0- (0.125,0) [-32|31.875] "m/s^2" Vector__XXX
 SG_ SRRLRCODPVOTk4PoILVAuth : 1874|9@0- (0.125,0) [-32|31.875] "m/s" Vector__XXX
 SG_ SRRLRCODPVOTk4PoILgAAuth : 1881|9@0- (0.125,0) [-32|31.875] "m/s^2" Vector__XXX
 SG_ SRRLRCODPVOTk5PoILAAuth : 1888|9@0- (0.125,0) [-32|31.875] "m/s^2" Vector__XXX
 SG_ SRRLRCODPVOTk5PoILVAuth : 1911|9@0- (0.125,0) [-32|31.875] "m/s" Vector__XXX
 SG_ SRRLRCODPVOTk5PoILgAAuth : 1918|9@0- (0.125,0) [-32|31.875] "m/s^2" Vector__XXX
 SG_ SRRLRCODPVOTk6PoILAAuth : 1925|9@0- (0.125,0) [-32|31.875] "m/s^2" Vector__XXX
 SG_ SRRLRCODPVOTk6PoILVAuth : 1932|9@0- (0.125,0) [-32|31.875] "m/s" Vector__XXX
 SG_ SRRLRCODPVOTk6PoILgAAuth : 1939|9@0- (0.125,0) [-32|31.875] "m/s^2" Vector__XXX
 SG_ SRRLRCODPVOTk7PoILAAuth : 1946|9@0- (0.125,0) [-32|31.875] "m/s^2" Vector__XXX
 SG_ SRRLRCODPVOTk7PoILVAuth : 1953|9@0- (0.125,0) [-32|31.875] "m/s" Vector__XXX
 SG_ SRRLRCODPVOTk7PoILgAAuth : 1960|9@0- (0.125,0) [-32|31.875] "m/s^2" Vector__XXX
 SG_ SRRLRCODPVOTk8PoILAAuth : 1983|9@0- (0.125,0) [-32|31.875] "m/s^2" Vector__XXX
 SG_ SRRLRCODPVOTk8PoILVAuth : 1990|9@0- (0.125,0) [-32|31.875] "m/s" Vector__XXX
 SG_ SRRLRCODPVOTk8PoILgAAuth : 1997|9@0- (0.125,0) [-32|31.875] "m/s^2" Vector__XXX
 SG_ SRRLRCODPVOTk9PoILAAuth : 2004|9@0- (0.125,0) [-32|31.875] "m/s^2" Vector__XXX
 SG_ SRRLRCODPVOTk9PoILVAuth : 2011|9@0- (0.125,0) [-32|31.875] "m/s" Vector__XXX
 SG_ SRRLRCODPVOTk9PoILgAAuth : 2018|9@0- (0.125,0) [-32|31.875] "m/s^2" Vector__XXX
 SG_ SRRLRCODPVOTk10PoILgthAuth : 2025|8@0+ (0.125,0) [0|31.875] "m" Vector__XXX
 SG_ SRRLRCODPVOTk1PoILgthAuth : 2033|8@0+ (0.125,0) [0|31.875] "m" Vector__XXX
 SG_ SRRLRCODPVOTk2PoILgthAuth : 2041|8@0+ (0.125,0) [0|31.875] "m" Vector__XXX
 SG_ SRRLRCODPVOTk3PoILgthAuth : 2049|8@0+ (0.125,0) [0|31.875] "m" Vector__XXX
 SG_ SRRLRCODPVOTk4PoILgthAuth : 2057|8@0+ (0.125,0) [0|31.875] "m" Vector__XXX
 SG_ SRRLRCODPVOTk5PoILgthAuth : 2065|8@0+ (0.125,0) [0|31.875] "m" Vector__XXX
 SG_ SRRLRCODPVOTk6PoILgthAuth : 2073|8@0+ (0.125,0) [0|31.875] "m" Vector__XXX
 SG_ SRRLRCODPVOTk7PoILgthAuth : 2081|8@0+ (0.125,0) [0|31.875] "m" Vector__XXX
 SG_ SRRLRCODPVOTk8PoILgthAuth : 2089|8@0+ (0.125,0) [0|31.875] "m" Vector__XXX
 SG_ SRRLRCODPVOTk9PoILgthAuth : 2097|8@0+ (0.125,0) [0|31.875] "m" Vector__XXX
 SG_ SRRLRCODPIOTk10IDAuth : 2105|7@0+ (1,0) [0|127] "" Vector__XXX
 SG_ SRRLRCODPIOTk1IDAuth : 2114|7@0+ (1,0) [0|127] "" Vector__XXX
 SG_ SRRLRCODPIOTk2IDAuth : 2123|7@0+ (1,0) [0|127] "" Vector__XXX
 SG_ SRRLRCODPIOTk3IDAuth : 2132|7@0+ (1,0) [0|127] "" Vector__XXX
 SG_ SRRLRCODPIOTk4IDAuth : 2141|7@0+ (1,0) [0|127] "" Vector__XXX
 SG_ SRRLRCODPIOTk5IDAuth : 2150|7@0+ (1,0) [0|127] "" Vector__XXX
 SG_ SRRLRCODPIOTk6IDAuth : 2159|7@0+ (1,0) [0|127] "" Vector__XXX
 SG_ SRRLRCODPIOTk7IDAuth : 2152|7@0+ (1,0) [0|127] "" Vector__XXX
 SG_ SRRLRCODPIOTk8IDAuth : 2161|7@0+ (1,0) [0|127] "" Vector__XXX
 SG_ SRRLRCODPIOTk9IDAuth : 2170|7@0+ (1,0) [0|127] "" Vector__XXX
 SG_ SRRLRCODPPOTk1IDAuth : 2179|7@0+ (1,0) [0|127] "" Vector__XXX
 SG_ SRRLRCODPPOTk2IDAuth : 2188|7@0+ (1,0) [0|127] "" Vector__XXX
 SG_ SRRLRCODPPOTk3IDAuth : 2197|7@0+ (1,0) [0|127] "" Vector__XXX
 SG_ SRRLRCODPPOTk4IDAuth : 2206|7@0+ (1,0) [0|127] "" Vector__XXX
 SG_ SRRLRCODPPOTk5IDAuth : 2215|7@0+ (1,0) [0|127] "" Vector__XXX
 SG_ SRRLRCODPVOTk10IDAuth : 2208|7@0+ (1,0) [0|127] "" Vector__XXX
 SG_ SRRLRCODPVOTk1IDAuth : 2217|7@0+ (1,0) [0|127] "" Vector__XXX
 SG_ SRRLRCODPVOTk2IDAuth : 2226|7@0+ (1,0) [0|127] "" Vector__XXX
 SG_ SRRLRCODPVOTk3IDAuth : 2235|7@0+ (1,0) [0|127] "" Vector__XXX
 SG_ SRRLRCODPVOTk4IDAuth : 2244|7@0+ (1,0) [0|127] "" Vector__XXX
 SG_ SRRLRCODPVOTk5IDAuth : 2253|7@0+ (1,0) [0|127] "" Vector__XXX
 SG_ SRRLRCODPVOTk6IDAuth : 2262|7@0+ (1,0) [0|127] "" Vector__XXX
 SG_ SRRLRCODPVOTk7IDAuth : 2271|7@0+ (1,0) [0|127] "" Vector__XXX
 SG_ SRRLRCODPVOTk8IDAuth : 2264|7@0+ (1,0) [0|127] "" Vector__XXX
 SG_ SRRLRCODPVOTk9IDAuth : 2273|7@0+ (1,0) [0|127] "" Vector__XXX
 SG_ SRRLRCODPPOTk1InPthPotAuth : 2282|6@0+ (2,0) [0|126] "%" Vector__XXX
 SG_ SRRLRCODPPOTk2InPthPotAuth : 2292|6@0+ (2,0) [0|126] "%" Vector__XXX
 SG_ SRRLRCODPPOTk3InPthPotAuth : 2302|6@0+ (2,0) [0|126] "%" Vector__XXX
 SG_ SRRLRCODPPOTk4InPthPotAuth : 2296|6@0+ (2,0) [0|126] "%" Vector__XXX
 SG_ SRRLRCODPPOTk5InPthPotAuth : 2306|6@0+ (2,0) [0|126] "%" Vector__XXX
 SG_ SRRLRCODPVOTk10CICOPotAuth : 2316|6@0+ (2,0) [0|126] "%" Vector__XXX
 SG_ SRRLRCODPVOTk1CICOPotAuth : 2326|6@0+ (2,0) [0|126] "%" Vector__XXX
 SG_ SRRLRCODPVOTk2CICOPotAuth : 2320|6@0+ (2,0) [0|126] "%" Vector__XXX
 SG_ SRRLRCODPVOTk3CICOPotAuth : 2330|6@0+ (2,0) [0|126] "%" Vector__XXX
 SG_ SRRLRCODPVOTk4CICOPotAuth : 2340|6@0+ (2,0) [0|126] "%" Vector__XXX
 SG_ SRRLRCODPVOTk5CICOPotAuth : 2350|6@0+ (2,0) [0|126] "%" Vector__XXX
 SG_ SRRLRCODPVOTk6CICOPotAuth : 2344|6@0+ (2,0) [0|126] "%" Vector__XXX
 SG_ SRRLRCODPVOTk7CICOPotAuth : 2354|6@0+ (2,0) [0|126] "%" Vector__XXX
 SG_ SRRLRCODPVOTk8CICOPotAuth : 2364|6@0+ (2,0) [0|126] "%" Vector__XXX
 SG_ SRRLRCODPVOTk9CICOPotAuth : 2374|6@0+ (2,0) [0|126] "%" Vector__XXX
 SG_ SRRLRCODPIOTk10TypAuth : 2368|3@0+ (1,0) [0|5] "" Vector__XXX
 SG_ SRRLRCODPIOTk1TypAuth : 2381|3@0+ (1,0) [0|5] "" Vector__XXX
 SG_ SRRLRCODPIOTk2TypAuth : 2378|3@0+ (1,0) [0|5] "" Vector__XXX
 SG_ SRRLRCODPIOTk3TypAuth : 2391|3@0+ (1,0) [0|5] "" Vector__XXX
 SG_ SRRLRCODPIOTk4TypAuth : 2388|3@0+ (1,0) [0|5] "" Vector__XXX
 SG_ SRRLRCODPIOTk5TypAuth : 2385|3@0+ (1,0) [0|5] "" Vector__XXX
 SG_ SRRLRCODPIOTk6TypAuth : 2398|3@0+ (1,0) [0|5] "" Vector__XXX
 SG_ SRRLRCODPIOTk7TypAuth : 2395|3@0+ (1,0) [0|5] "" Vector__XXX
 SG_ SRRLRCODPIOTk8TypAuth : 2392|3@0+ (1,0) [0|5] "" Vector__XXX
 SG_ SRRLRCODPIOTk9TypAuth : 2405|3@0+ (1,0) [0|5] "" Vector__XXX
 SG_ SRRLRCODPPOTk1DynPrpAuth : 2402|3@0+ (1,0) [0|4] "" Vector__XXX
 SG_ SRRLRCODPPOTk2DynPrpAuth : 2415|3@0+ (1,0) [0|4] "" Vector__XXX
 SG_ SRRLRCODPPOTk3DynPrpAuth : 2412|3@0+ (1,0) [0|4] "" Vector__XXX
 SG_ SRRLRCODPPOTk4DynPrpAuth : 2409|3@0+ (1,0) [0|4] "" Vector__XXX
 SG_ SRRLRCODPPOTk5DynPrpAuth : 2422|3@0+ (1,0) [0|4] "" Vector__XXX
 SG_ SRRLRCODPREOTk1TypAuth : 2419|3@0+ (1,0) [0|5] "" Vector__XXX
 SG_ SRRLRCODPREOTk2TypAuth : 2416|3@0+ (1,0) [0|5] "" Vector__XXX
 SG_ SRRLRCODPREOTk3TypAuth : 2429|3@0+ (1,0) [0|5] "" Vector__XXX
 SG_ SRRLRCODPRdTypAuth : 2426|3@0+ (1,0) [0|5] "" Vector__XXX
 SG_ SRRLRCODPVOTk10DynPrpAuth : 2439|3@0+ (1,0) [0|4] "" Vector__XXX
 SG_ SRRLRCODPVOTk1DynPrpAuth : 2436|3@0+ (1,0) [0|4] "" Vector__XXX
 SG_ SRRLRCODPVOTk2DynPrpAuth : 2433|3@0+ (1,0) [0|4] "" Vector__XXX
 SG_ SRRLRCODPVOTk3DynPrpAuth : 2446|3@0+ (1,0) [0|4] "" Vector__XXX
 SG_ SRRLRCODPVOTk4DynPrpAuth : 2443|3@0+ (1,0) [0|4] "" Vector__XXX
 SG_ SRRLRCODPVOTk5DynPrpAuth : 2440|3@0+ (1,0) [0|4] "" Vector__XXX
 SG_ SRRLRCODPVOTk6DynPrpAuth : 2453|3@0+ (1,0) [0|4] "" Vector__XXX
 SG_ SRRLRCODPVOTk7DynPrpAuth : 2450|3@0+ (1,0) [0|4] "" Vector__XXX
 SG_ SRRLRCODPVOTk8DynPrpAuth : 2463|3@0+ (1,0) [0|4] "" Vector__XXX
 SG_ SRRLRCODPVOTk9DynPrpAuth : 2460|3@0+ (1,0) [0|4] "" Vector__XXX
 SG_ SRRLRCODPConstrArDtnCnfdAuth : 2457|2@0+ (1,0) [0|3] "" Vector__XXX
 SG_ SRRLRCODPConstrArDtnStsAuth : 2471|2@0+ (1,0) [0|2] "" Vector__XXX
 SG_ SRRLRCODPIOTk10CnfdStsAuth : 2469|2@0+ (1,0) [0|3] "" Vector__XXX
 SG_ SRRLRCODPIOTk10ElvtnAuth : 2467|2@0+ (1,0) [0|3] "" Vector__XXX
 SG_ SRRLRCODPIOTk10MStsAuth : 2465|2@0+ (1,0) [0|3] "" Vector__XXX
 SG_ SRRLRCODPIOTk10TypCnfdAuth : 2479|2@0+ (1,0) [0|3] "" Vector__XXX
 SG_ SRRLRCODPIOTk1CnfdStsAuth : 2477|2@0+ (1,0) [0|3] "" Vector__XXX
 SG_ SRRLRCODPIOTk1ElvtnAuth : 2475|2@0+ (1,0) [0|3] "" Vector__XXX
 SG_ SRRLRCODPIOTk1MStsAuth : 2473|2@0+ (1,0) [0|3] "" Vector__XXX
 SG_ SRRLRCODPIOTk1TypCnfdAuth : 2487|2@0+ (1,0) [0|3] "" Vector__XXX
 SG_ SRRLRCODPIOTk2CnfdStsAuth : 2485|2@0+ (1,0) [0|3] "" Vector__XXX
 SG_ SRRLRCODPIOTk2ElvtnAuth : 2483|2@0+ (1,0) [0|3] "" Vector__XXX
 SG_ SRRLRCODPIOTk2MStsAuth : 2481|2@0+ (1,0) [0|3] "" Vector__XXX
 SG_ SRRLRCODPIOTk2TypCnfdAuth : 2495|2@0+ (1,0) [0|3] "" Vector__XXX
 SG_ SRRLRCODPIOTk3CnfdStsAuth : 2493|2@0+ (1,0) [0|3] "" Vector__XXX
 SG_ SRRLRCODPIOTk3ElvtnAuth : 2491|2@0+ (1,0) [0|3] "" Vector__XXX
 SG_ SRRLRCODPIOTk3MStsAuth : 2489|2@0+ (1,0) [0|3] "" Vector__XXX
 SG_ SRRLRCODPIOTk3TypCnfdAuth : 2503|2@0+ (1,0) [0|3] "" Vector__XXX
 SG_ SRRLRCODPIOTk4CnfdStsAuth : 2501|2@0+ (1,0) [0|3] "" Vector__XXX
 SG_ SRRLRCODPIOTk4ElvtnAuth : 2499|2@0+ (1,0) [0|3] "" Vector__XXX
 SG_ SRRLRCODPIOTk4MStsAuth : 2497|2@0+ (1,0) [0|3] "" Vector__XXX
 SG_ SRRLRCODPIOTk4TypCnfdAuth : 2511|2@0+ (1,0) [0|3] "" Vector__XXX
 SG_ SRRLRCODPIOTk5CnfdStsAuth : 2509|2@0+ (1,0) [0|3] "" Vector__XXX
 SG_ SRRLRCODPIOTk5ElvtnAuth : 2507|2@0+ (1,0) [0|3] "" Vector__XXX
 SG_ SRRLRCODPIOTk5MStsAuth : 2505|2@0+ (1,0) [0|3] "" Vector__XXX
 SG_ SRRLRCODPIOTk5TypCnfdAuth : 2519|2@0+ (1,0) [0|3] "" Vector__XXX
 SG_ SRRLRCODPIOTk6CnfdStsAuth : 2517|2@0+ (1,0) [0|3] "" Vector__XXX
 SG_ SRRLRCODPIOTk6ElvtnAuth : 2515|2@0+ (1,0) [0|3] "" Vector__XXX
 SG_ SRRLRCODPIOTk6MStsAuth : 2513|2@0+ (1,0) [0|3] "" Vector__XXX
 SG_ SRRLRCODPIOTk6TypCnfdAuth : 2527|2@0+ (1,0) [0|3] "" Vector__XXX
 SG_ SRRLRCODPIOTk7CnfdStsAuth : 2525|2@0+ (1,0) [0|3] "" Vector__XXX
 SG_ SRRLRCODPIOTk7ElvtnAuth : 2523|2@0+ (1,0) [0|3] "" Vector__XXX
 SG_ SRRLRCODPIOTk7MStsAuth : 2521|2@0+ (1,0) [0|3] "" Vector__XXX
 SG_ SRRLRCODPIOTk7TypCnfdAuth : 2535|2@0+ (1,0) [0|3] "" Vector__XXX
 SG_ SRRLRCODPIOTk8CnfdStsAuth : 2533|2@0+ (1,0) [0|3] "" Vector__XXX
 SG_ SRRLRCODPIOTk8ElvtnAuth : 2531|2@0+ (1,0) [0|3] "" Vector__XXX
 SG_ SRRLRCODPIOTk8MStsAuth : 2529|2@0+ (1,0) [0|3] "" Vector__XXX
 SG_ SRRLRCODPIOTk8TypCnfdAuth : 2543|2@0+ (1,0) [0|3] "" Vector__XXX
 SG_ SRRLRCODPIOTk9CnfdStsAuth : 2541|2@0+ (1,0) [0|3] "" Vector__XXX
 SG_ SRRLRCODPIOTk9ElvtnAuth : 2539|2@0+ (1,0) [0|3] "" Vector__XXX
 SG_ SRRLRCODPIOTk9MStsAuth : 2537|2@0+ (1,0) [0|3] "" Vector__XXX
 SG_ SRRLRCODPIOTk9TypCnfdAuth : 2551|2@0+ (1,0) [0|3] "" Vector__XXX
 SG_ SRRLRCODPMdCmdStsAuth : 2549|2@0+ (1,0) [0|2] "" Vector__XXX
 SG_ SRRLRCODPPOTk1CnfdStsAuth : 2547|2@0+ (1,0) [0|3] "" Vector__XXX
 SG_ SRRLRCODPPOTk1MStsAuth : 2545|2@0+ (1,0) [0|3] "" Vector__XXX
 SG_ SRRLRCODPPOTk1TypAuth : 2559|2@0+ (1,0) [0|2] "" Vector__XXX
 SG_ SRRLRCODPPOTk1TypCnfdAuth : 2557|2@0+ (1,0) [0|3] "" Vector__XXX
 SG_ SRRLRCODPPOTk2CnfdStsAuth : 2555|2@0+ (1,0) [0|3] "" Vector__XXX
 SG_ SRRLRCODPPOTk2MStsAuth : 2553|2@0+ (1,0) [0|3] "" Vector__XXX
 SG_ SRRLRCODPPOTk2TypAuth : 2567|2@0+ (1,0) [0|2] "" Vector__XXX
 SG_ SRRLRCODPPOTk2TypCnfdAuth : 2565|2@0+ (1,0) [0|3] "" Vector__XXX
 SG_ SRRLRCODPPOTk3CnfdStsAuth : 2563|2@0+ (1,0) [0|3] "" Vector__XXX
 SG_ SRRLRCODPPOTk3MStsAuth : 2561|2@0+ (1,0) [0|3] "" Vector__XXX
 SG_ SRRLRCODPPOTk3TypAuth : 2575|2@0+ (1,0) [0|2] "" Vector__XXX
 SG_ SRRLRCODPPOTk3TypCnfdAuth : 2573|2@0+ (1,0) [0|3] "" Vector__XXX
 SG_ SRRLRCODPPOTk4CnfdStsAuth : 2571|2@0+ (1,0) [0|3] "" Vector__XXX
 SG_ SRRLRCODPPOTk4MStsAuth : 2569|2@0+ (1,0) [0|3] "" Vector__XXX
 SG_ SRRLRCODPPOTk4TypAuth : 2583|2@0+ (1,0) [0|2] "" Vector__XXX
 SG_ SRRLRCODPPOTk4TypCnfdAuth : 2581|2@0+ (1,0) [0|3] "" Vector__XXX
 SG_ SRRLRCODPPOTk5CnfdStsAuth : 2579|2@0+ (1,0) [0|3] "" Vector__XXX
 SG_ SRRLRCODPPOTk5MStsAuth : 2577|2@0+ (1,0) [0|3] "" Vector__XXX
 SG_ SRRLRCODPPOTk5TypAuth : 2591|2@0+ (1,0) [0|2] "" Vector__XXX
 SG_ SRRLRCODPPOTk5TypCnfdAuth : 2589|2@0+ (1,0) [0|3] "" Vector__XXX
 SG_ SRRLRCODPREOTk1CnfdStsAuth : 2587|2@0+ (1,0) [0|3] "" Vector__XXX
 SG_ SRRLRCODPREOTk1TypCnfdAuth : 2585|2@0+ (1,0) [0|3] "" Vector__XXX
 SG_ SRRLRCODPREOTk2CnfdStsAuth : 2599|2@0+ (1,0) [0|3] "" Vector__XXX
 SG_ SRRLRCODPREOTk2TypCnfdAuth : 2597|2@0+ (1,0) [0|3] "" Vector__XXX
 SG_ SRRLRCODPREOTk3CnfdStsAuth : 2595|2@0+ (1,0) [0|3] "" Vector__XXX
 SG_ SRRLRCODPREOTk3TypCnfdAuth : 2593|2@0+ (1,0) [0|3] "" Vector__XXX
 SG_ SRRLRCODPRdTypCnfdAuth : 2607|2@0+ (1,0) [0|3] "" Vector__XXX
 SG_ SRRLRCODPSwpBndwdthStsAuth : 2605|2@0+ (1,0) [0|3] "" Vector__XXX
 SG_ SRRLRCODPVOTk10CnfdStsAuth : 2603|2@0+ (1,0) [0|3] "" Vector__XXX
 SG_ SRRLRCODPVOTk10MStsAuth : 2601|2@0+ (1,0) [0|3] "" Vector__XXX
 SG_ SRRLRCODPVOTk10TypCnfdAuth : 2615|2@0+ (1,0) [0|3] "" Vector__XXX
 SG_ SRRLRCODPVOTk1CnfdStsAuth : 2613|2@0+ (1,0) [0|3] "" Vector__XXX
 SG_ SRRLRCODPVOTk1MStsAuth : 2611|2@0+ (1,0) [0|3] "" Vector__XXX
 SG_ SRRLRCODPVOTk1TypCnfdAuth : 2609|2@0+ (1,0) [0|3] "" Vector__XXX
 SG_ SRRLRCODPVOTk2CnfdStsAuth : 2623|2@0+ (1,0) [0|3] "" Vector__XXX
 SG_ SRRLRCODPVOTk2MStsAuth : 2621|2@0+ (1,0) [0|3] "" Vector__XXX
 SG_ SRRLRCODPVOTk2TypCnfdAuth : 2619|2@0+ (1,0) [0|3] "" Vector__XXX
 SG_ SRRLRCODPVOTk3CnfdStsAuth : 2617|2@0+ (1,0) [0|3] "" Vector__XXX
 SG_ SRRLRCODPVOTk3MStsAuth : 2631|2@0+ (1,0) [0|3] "" Vector__XXX
 SG_ SRRLRCODPVOTk3TypCnfdAuth : 2629|2@0+ (1,0) [0|3] "" Vector__XXX
 SG_ SRRLRCODPVOTk4CnfdStsAuth : 2627|2@0+ (1,0) [0|3] "" Vector__XXX
 SG_ SRRLRCODPVOTk4MStsAuth : 2625|2@0+ (1,0) [0|3] "" Vector__XXX
 SG_ SRRLRCODPVOTk4TypCnfdAuth : 2639|2@0+ (1,0) [0|3] "" Vector__XXX
 SG_ SRRLRCODPVOTk5CnfdStsAuth : 2637|2@0+ (1,0) [0|3] "" Vector__XXX
 SG_ SRRLRCODPVOTk5MStsAuth : 2635|2@0+ (1,0) [0|3] "" Vector__XXX
 SG_ SRRLRCODPVOTk5TypCnfdAuth : 2633|2@0+ (1,0) [0|3] "" Vector__XXX
 SG_ SRRLRCODPVOTk6CnfdStsAuth : 2647|2@0+ (1,0) [0|3] "" Vector__XXX
 SG_ SRRLRCODPVOTk6MStsAuth : 2645|2@0+ (1,0) [0|3] "" Vector__XXX
 SG_ SRRLRCODPVOTk6TypCnfdAuth : 2643|2@0+ (1,0) [0|3] "" Vector__XXX
 SG_ SRRLRCODPVOTk7CnfdStsAuth : 2641|2@0+ (1,0) [0|3] "" Vector__XXX
 SG_ SRRLRCODPVOTk7MStsAuth : 2655|2@0+ (1,0) [0|3] "" Vector__XXX
 SG_ SRRLRCODPVOTk7TypCnfdAuth : 2653|2@0+ (1,0) [0|3] "" Vector__XXX
 SG_ SRRLRCODPVOTk8CnfdStsAuth : 2651|2@0+ (1,0) [0|3] "" Vector__XXX
 SG_ SRRLRCODPVOTk8MStsAuth : 2649|2@0+ (1,0) [0|3] "" Vector__XXX
 SG_ SRRLRCODPVOTk8TypCnfdAuth : 2663|2@0+ (1,0) [0|3] "" Vector__XXX
 SG_ SRRLRCODPVOTk9CnfdStsAuth : 2661|2@0+ (1,0) [0|3] "" Vector__XXX
 SG_ SRRLRCODPVOTk9MStsAuth : 2659|2@0+ (1,0) [0|3] "" Vector__XXX
 SG_ SRRLRCODPVOTk9TypCnfdAuth : 2657|2@0+ (1,0) [0|3] "" Vector__XXX
 SG_ SRRLRCODPAcqTmStmAuth_Inv : 2671|1@0+ (1,0) [0|1] "" Vector__XXX
 SG_ SRRLRCODPServRqrdAuth : 2670|1@0+ (1,0) [0|1] "" Vector__XXX
 SG_ SRRLRCODPSnsrBlckdAuth : 2669|1@0+ (1,0) [0|1] "" Vector__XXX
 SG_ SRRLRCODPSnsrUnvAuth : 2668|1@0+ (1,0) [0|1] "" Vector__XXX
 SG_ SRRLRCODPVOTk10DynPrpStsAuth : 2667|1@0+ (1,0) [0|1] "" Vector__XXX
 SG_ SRRLRCODPVOTk1DynPrpStsAuth : 2666|1@0+ (1,0) [0|1] "" Vector__XXX
 SG_ SRRLRCODPVOTk2DynPrpStsAuth : 2665|1@0+ (1,0) [0|1] "" Vector__XXX
 SG_ SRRLRCODPVOTk3DynPrpStsAuth : 2664|1@0+ (1,0) [0|1] "" Vector__XXX
 SG_ SRRLRCODPVOTk4DynPrpStsAuth : 2679|1@0+ (1,0) [0|1] "" Vector__XXX
 SG_ SRRLRCODPVOTk5DynPrpStsAuth : 2678|1@0+ (1,0) [0|1] "" Vector__XXX
 SG_ SRRLRCODPVOTk6DynPrpStsAuth : 2677|1@0+ (1,0) [0|1] "" Vector__XXX
 SG_ SRRLRCODPVOTk7DynPrpStsAuth : 2676|1@0+ (1,0) [0|1] "" Vector__XXX
 SG_ SRRLRCODPVOTk8DynPrpStsAuth : 2675|1@0+ (1,0) [0|1] "" Vector__XXX
 SG_ SRRLRCODPVOTk9DynPrpStsAuth : 2674|1@0+ (1,0) [0|1] "" Vector__XXX
 SG_ SD185BG1P_ARC : 2673|2@0+ (1,0) [0|3] "" Vector__XXX

BO_ 123 Tp_SrlDat185_FlwCtrl_PDU: 64 CGM

BA_DEF_ SG_  "SignalType" STRING ;
BA_DEF_ SG_  "SignalLongName" STRING ;
BA_DEF_ BO_  "GenMsgCycleTime" INT 0 10000;
BA_DEF_ BO_  "GenMsgSendType" ENUM "cyclicX","spontanX","cyclicIfActiveX","spontanWithDelay","cyclicAndSpontanX","cyclicAndSpontanWithDelay","spontanWithRepetition","cyclicIfActiveAndSpontanWD";
BA_DEF_ BO_  "VFrameFormat" ENUM  "StandardCAN","ExtendedCAN","reserved","reserved","reserved","reserved","reserved","reserved","reserved","reserved","reserved","reserved","reserved","reserved","StandardCAN_FD","ExtendedCAN_FD";
BA_DEF_DEF_  "SignalType" "";
BA_DEF_DEF_  "SignalLongName" "";
BA_DEF_DEF_  "GenMsgCycleTime" 0;
BA_DEF_DEF_  "GenMsgSendType" "cyclicX";
BA_DEF_DEF_  "VFrameFormat" "StandardCAN";
BA_ "VFrameFormat" BO_ 21 14;
BA_ "VFrameFormat" BO_ 543 14;
BA_ "VFrameFormat" BO_ 20 14;
BA_ "VFrameFormat" BO_ 906 14;
BA_ "GenMsgCycleTime" BO_ 226 25;
BA_ "VFrameFormat" BO_ 226 14;
BA_ "GenMsgCycleTime" BO_ 1404 1000;
BA_ "VFrameFormat" BO_ 1404 14;
BA_ "GenMsgCycleTime" BO_ 879 250;
BA_ "VFrameFormat" BO_ 879 14;
BA_ "GenMsgCycleTime" BO_ 72 12.5;
BA_ "VFrameFormat" BO_ 72 14;
BA_ "VFrameFormat" BO_ 897 14;
BA_ "GenMsgCycleTime" BO_ 57 10;
BA_ "VFrameFormat" BO_ 57 14;
BA_ "GenMsgCycleTime" BO_ 1403 1000;
BA_ "VFrameFormat" BO_ 1403 14;
BA_ "GenMsgCycleTime" BO_ 878 250;
BA_ "VFrameFormat" BO_ 878 14;
BA_ "VFrameFormat" BO_ 122 14;
BA_ "VFrameFormat" BO_ 123 14;
BA_ "SignalLongName" SG_ 21 SD199P_MAC "Serial Data 199 Protected : MAC";
BA_ "SignalLongName" SG_ 21 SD199P_FCnt "Serial Data 199 Protected : Freshness Counter";
BA_ "SignalLongName" SG_ 21 SRRSRRODPTOVYawRate "Serial Data 199 Protected : Short Range Radar Side Right Rear Object Detection and Processing Trailer Object Variance Yaw Rate";
BA_ "SignalLongName" SG_ 21 SRRSRRODPTrObjYawRate "Serial Data 199 Protected : Short Range Radar Side Right Rear Object Detection and Processing Trailer Object Yaw Rate";
BA_ "SignalLongName" SG_ 21 SRRSRRODPTrObjOrntn "Serial Data 199 Protected : Short Range Radar Side Right Rear Object Detection and Processing Trailer Object Orientation";
BA_ "SignalLongName" SG_ 21 SRRSRRODPTODTrHtchTrFrt "Serial Data 199 Protected : Short Range Radar Side Right Rear Object Detection and Processing Trailer Object Distance Trailer Hitch To Trailer Front";
BA_ "SignalLongName" SG_ 21 SRRSRRODPTOVLgth "Serial Data 199 Protected : Short Range Radar Side Right Rear Object Detection and Processing Trailer Object Variance Length";
BA_ "SignalLongName" SG_ 21 SRRSRRODPTOVOrntn "Serial Data 199 Protected : Short Range Radar Side Right Rear Object Detection and Processing Trailer Object Variance Orientation";
BA_ "SignalLongName" SG_ 21 SRRSRRODPTOVWdth "Serial Data 199 Protected : Short Range Radar Side Right Rear Object Detection and Processing Trailer Object Variance Width";
BA_ "SignalLongName" SG_ 21 SRRSRRODPTrObjLgth "Serial Data 199 Protected : Short Range Radar Side Right Rear Object Detection and Processing Trailer Object Length";
BA_ "SignalLongName" SG_ 21 SRRSRRODPTODVhFrtAxVhHtch "Serial Data 199 Protected : Short Range Radar Side Right Rear Object Detection and Processing Trailer Object Distance Vehicle Front Axle To Vehicle Hitch";
BA_ "SignalLongName" SG_ 21 SRRSRRODPTODTrHtchTrAx "Serial Data 199 Protected : Short Range Radar Side Right Rear Object Detection and Processing Trailer Object Distance Trailer Hitch To Trailer Axle";
BA_ "SignalLongName" SG_ 21 SRRSRRODPTOEExistPrblty "Serial Data 199 Protected : Short Range Radar Side Right Rear Object Detection and Processing Trailer Object Edge Existence Probability";
BA_ "SignalLongName" SG_ 21 SRRSRRODPTOPDtnPrblty "Serial Data 199 Protected : Short Range Radar Side Right Rear Object Detection and Processing Trailer Object Presence Detection Probability";
BA_ "SignalLongName" SG_ 21 SRRSRRODPTrObjQlty "Serial Data 199 Protected : Short Range Radar Side Right Rear Object Detection and Processing Trailer Object Quality";
BA_ "SignalLongName" SG_ 21 SRRSRRODPTOVDTrHtchTrAx "Serial Data 199 Protected : Short Range Radar Side Right Rear Object Detection and Processing Trailer Object Variance Distance Trailer Hitch To Trailer Axle";
BA_ "SignalLongName" SG_ 21 SRRSRRODPTOVDVhFrtAxVhHtch "Serial Data 199 Protected : Short Range Radar Side Right Rear Object Detection and Processing Trailer Object Variance Distance Vehicle Front Axle To Vehicle Hitch";
BA_ "SignalLongName" SG_ 21 SRRSRRODPTOVDTrHtchTrFrt "Serial Data 199 Protected : Short Range Radar Side Right Rear Object Detection and Processing Trailer Object Variance Distance Trailer Hitch To Trailer Front";
BA_ "SignalLongName" SG_ 21 SRRSRRODPTrObjWdth "Serial Data 199 Protected : Short Range Radar Side Right Rear Object Detection and Processing Trailer Object Width";
BA_ "SignalType" SG_ 21 SRRSRRODPTrObjStatInfo "ENM";
BA_ "SignalLongName" SG_ 21 SRRSRRODPTrObjStatInfo "Serial Data 199 Protected : Short Range Radar Side Right Rear Object Detection and Processing Trailer Object State Information";
BA_ "SignalLongName" SG_ 21 SRRSRRODPTrObjExtrnInfo "Serial Data 199 Protected : Short Range Radar Side Right Rear Object Detection and Processing Trailer Object External Information";
BA_ "SignalType" SG_ 21 SRRSRRODPTOPDtnPrblty_Inv "ENM";
BA_ "SignalLongName" SG_ 21 SRRSRRODPTOPDtnPrblty_Inv "Serial Data 199 Protected : Short Range Radar Side Right Rear Object Detection and Processing Trailer Object Presence Detection Probability Invalid";
BA_ "SignalType" SG_ 21 SRRSRRODPTOEExistPrblty_Inv "ENM";
BA_ "SignalLongName" SG_ 21 SRRSRRODPTOEExistPrblty_Inv "Serial Data 199 Protected : Short Range Radar Side Right Rear Object Detection and Processing Trailer Object Edge Existence Probability Invalid";
BA_ "SignalType" SG_ 21 SRRSRRODPTODVhFrtAxVhHtch_Inv "ENM";
BA_ "SignalLongName" SG_ 21 SRRSRRODPTODVhFrtAxVhHtch_Inv "Serial Data 199 Protected : Short Range Radar Side Right Rear Object Detection and Processing Trailer Object Distance Vehicle Front Axle To Vehicle Hitch Invalid";
BA_ "SignalType" SG_ 21 SRRSRRODPTODTrHtchTrFrt_Inv "ENM";
BA_ "SignalLongName" SG_ 21 SRRSRRODPTODTrHtchTrFrt_Inv "Serial Data 199 Protected : Short Range Radar Side Right Rear Object Detection and Processing Trailer Object Distance Trailer Hitch To Trailer Front Invalid";
BA_ "SignalType" SG_ 21 SRRSRRODPTODTrHtchTrAx_Inv "ENM";
BA_ "SignalLongName" SG_ 21 SRRSRRODPTODTrHtchTrAx_Inv "Serial Data 199 Protected : Short Range Radar Side Right Rear Object Detection and Processing Trailer Object Distance Trailer Hitch To Trailer Axle Invalid";
BA_ "SignalType" SG_ 21 SRRSRRODPTrAtchdInfo "ENM";
BA_ "SignalLongName" SG_ 21 SRRSRRODPTrAtchdInfo "Serial Data 199 Protected : Short Range Radar Side Right Rear Object Detection and Processing Trailer Attached Information";
BA_ "SignalType" SG_ 21 SRRSRRODPTrObjExtrnInfo_Inv "ENM";
BA_ "SignalLongName" SG_ 21 SRRSRRODPTrObjExtrnInfo_Inv "Serial Data 199 Protected : Short Range Radar Side Right Rear Object Detection and Processing Trailer Object External Information Invalid";
BA_ "SignalType" SG_ 21 SRRSRRODPTOVYawRate_Inv "ENM";
BA_ "SignalLongName" SG_ 21 SRRSRRODPTOVYawRate_Inv "Serial Data 199 Protected : Short Range Radar Side Right Rear Object Detection and Processing Trailer Object Variance Yaw Rate Invalid";
BA_ "SignalType" SG_ 21 SRRSRRODPTOVWdth_Inv "ENM";
BA_ "SignalLongName" SG_ 21 SRRSRRODPTOVWdth_Inv "Serial Data 199 Protected : Short Range Radar Side Right Rear Object Detection and Processing Trailer Object Variance Width Invalid";
BA_ "SignalType" SG_ 21 SRRSRRODPTOVOrntn_Inv "ENM";
BA_ "SignalLongName" SG_ 21 SRRSRRODPTOVOrntn_Inv "Serial Data 199 Protected : Short Range Radar Side Right Rear Object Detection and Processing Trailer Object Variance Orientation Invalid";
BA_ "SignalType" SG_ 21 SRRSRRODPTOVLgth_Inv "ENM";
BA_ "SignalLongName" SG_ 21 SRRSRRODPTOVLgth_Inv "Serial Data 199 Protected : Short Range Radar Side Right Rear Object Detection and Processing Trailer Object Variance Length Invalid";
BA_ "SignalType" SG_ 21 SRRSRRODPTOVDVhFrtAxVhHtch_Inv "ENM";
BA_ "SignalLongName" SG_ 21 SRRSRRODPTOVDVhFrtAxVhHtch_Inv "Serial Data 199 Protected : Short Range Radar Side Right Rear Object Detection and Processing Trailer Object Variance Distance Vehicle Front Axle To Vehicle Hitch Invalid";
BA_ "SignalType" SG_ 21 SRRSRRODPTOVDTrHtchTrFrt_Inv "ENM";
BA_ "SignalLongName" SG_ 21 SRRSRRODPTOVDTrHtchTrFrt_Inv "Serial Data 199 Protected : Short Range Radar Side Right Rear Object Detection and Processing Trailer Object Variance Distance Trailer Hitch To Trailer Front Invalid";
BA_ "SignalType" SG_ 21 SRRSRRODPTOVDTrHtchTrAx_Inv "ENM";
BA_ "SignalLongName" SG_ 21 SRRSRRODPTOVDTrHtchTrAx_Inv "Serial Data 199 Protected : Short Range Radar Side Right Rear Object Detection and Processing Trailer Object Variance Distance Trailer Hitch To Trailer Axle Invalid";
BA_ "SignalLongName" SG_ 21 SrlDat199_Filler "Serial Data 199 Protected : Filler";
BA_ "SignalType" SG_ 21 SRRSRRODPTrObjYawRate_Inv "ENM";
BA_ "SignalLongName" SG_ 21 SRRSRRODPTrObjYawRate_Inv "Serial Data 199 Protected : Short Range Radar Side Right Rear Object Detection and Processing Trailer Object Yaw Rate Invalid";
BA_ "SignalType" SG_ 21 SRRSRRODPTrObjWdth_Inv "ENM";
BA_ "SignalLongName" SG_ 21 SRRSRRODPTrObjWdth_Inv "Serial Data 199 Protected : Short Range Radar Side Right Rear Object Detection and Processing Trailer Object Width Invalid";
BA_ "SignalType" SG_ 21 SRRSRRODPTrObjQlty_Inv "ENM";
BA_ "SignalLongName" SG_ 21 SRRSRRODPTrObjQlty_Inv "Serial Data 199 Protected : Short Range Radar Side Right Rear Object Detection and Processing Trailer Object Quality Invalid";
BA_ "SignalType" SG_ 21 SRRSRRODPTrObjOrntn_Inv "ENM";
BA_ "SignalLongName" SG_ 21 SRRSRRODPTrObjOrntn_Inv "Serial Data 199 Protected : Short Range Radar Side Right Rear Object Detection and Processing Trailer Object Orientation Invalid";
BA_ "SignalType" SG_ 21 SRRSRRODPTrObjLgth_Inv "ENM";
BA_ "SignalLongName" SG_ 21 SRRSRRODPTrObjLgth_Inv "Serial Data 199 Protected : Short Range Radar Side Right Rear Object Detection and Processing Trailer Object Length Invalid";
BA_ "SignalLongName" SG_ 21 SrlDat199_FillerExtnd "Serial Data 199 Protected : Filler Extended";
BA_ "SignalLongName" SG_ 21 SD199P_ARC "Serial Data 199 Protected : Alive Rolling Count";
BA_ "SignalLongName" SG_ 543 SrlDat200_PCSM "Serial Data 200 Protected Counter Sync Message";
BA_ "SignalLongName" SG_ 20 SD200P_MAC "Serial Data 200 Protected : MAC";
BA_ "SignalLongName" SG_ 20 SD200P_FCnt "Serial Data 200 Protected : Freshness Counter";
BA_ "SignalLongName" SG_ 20 SRRRRODPTOVYawRate "Serial Data 200 Protected : Short Range Radar Right Rear Object Detection and Processing Trailer Object Variance Yaw Rate";
BA_ "SignalLongName" SG_ 20 SRRRRODPTrObjYawRate "Serial Data 200 Protected : Short Range Radar Right Rear Object Detection and Processing Trailer Object Yaw Rate";
BA_ "SignalLongName" SG_ 20 SRRRRODPTrObjOrntn "Serial Data 200 Protected : Short Range Radar Right Rear Object Detection and Processing Trailer Object Orientation";
BA_ "SignalLongName" SG_ 20 SRRRRODPTODTrHtchTrFrt "Serial Data 200 Protected : Short Range Radar Right Rear Object Detection and Processing Trailer Object Distance Trailer Hitch To Trailer Front";
BA_ "SignalLongName" SG_ 20 SRRRRODPTOVLgth "Serial Data 200 Protected : Short Range Radar Right Rear Object Detection and Processing Trailer Object Variance Length";
BA_ "SignalLongName" SG_ 20 SRRRRODPTOVOrntn "Serial Data 200 Protected : Short Range Radar Right Rear Object Detection and Processing Trailer Object Variance Orientation";
BA_ "SignalLongName" SG_ 20 SRRRRODPTOVWdth "Serial Data 200 Protected : Short Range Radar Right Rear Object Detection and Processing Trailer Object Variance Width";
BA_ "SignalLongName" SG_ 20 SRRRRODPTrObjLgth "Serial Data 200 Protected : Short Range Radar Right Rear Object Detection and Processing Trailer Object Length";
BA_ "SignalLongName" SG_ 20 SRRRRODPTODVhFrtAxVhHtch "Serial Data 200 Protected : Short Range Radar Right Rear Object Detection and Processing Trailer Object Distance Vehicle Front Axle To Vehicle Hitch";
BA_ "SignalLongName" SG_ 20 SRRRRODPTODTrHtchTrAx "Serial Data 200 Protected : Short Range Radar Right Rear Object Detection and Processing Trailer Object Distance Trailer Hitch To Trailer Axle";
BA_ "SignalLongName" SG_ 20 SRRRRODPTOEExistPrblty "Serial Data 200 Protected : Short Range Radar Right Rear Object Detection and Processing Trailer Object Edge Existence Probability";
BA_ "SignalLongName" SG_ 20 SRRRRODPTOPDtnPrblty "Serial Data 200 Protected : Short Range Radar Right Rear Object Detection and Processing Trailer Object Presence Detection Probability";
BA_ "SignalLongName" SG_ 20 SRRRRODPTrObjQlty "Serial Data 200 Protected : Short Range Radar Right Rear Object Detection and Processing Trailer Object Quality";
BA_ "SignalLongName" SG_ 20 SRRRRODPTOVDTrHtchTrAx "Serial Data 200 Protected : Short Range Radar Right Rear Object Detection and Processing Trailer Object Variance Distance Trailer Hitch To Trailer Axle";
BA_ "SignalLongName" SG_ 20 SRRRRODPTOVDVhFrtAxVhHtch "Serial Data 200 Protected : Short Range Radar Right Rear Object Detection and Processing Trailer Object Variance Distance Vehicle Front Axle To Vehicle Hitch";
BA_ "SignalLongName" SG_ 20 SRRRRODPTOVDTrHtchTrFrt "Serial Data 200 Protected : Short Range Radar Right Rear Object Detection and Processing Trailer Object Variance Distance Trailer Hitch To Trailer Front";
BA_ "SignalLongName" SG_ 20 SRRRRODPTrObjWdth "Serial Data 200 Protected : Short Range Radar Right Rear Object Detection and Processing Trailer Object Width";
BA_ "SignalType" SG_ 20 SRRRRODPTrObjStatInfo "ENM";
BA_ "SignalLongName" SG_ 20 SRRRRODPTrObjStatInfo "Serial Data 200 Protected : Short Range Radar Right Rear Object Detection and Processing Trailer Object State Information";
BA_ "SignalLongName" SG_ 20 SRRRRODPTrObjExtrnInfo "Serial Data 200 Protected : Short Range Radar Right Rear Object Detection and Processing Trailer Object External Information";
BA_ "SignalType" SG_ 20 SRRRRODPTOPDtnPrblty_Inv "ENM";
BA_ "SignalLongName" SG_ 20 SRRRRODPTOPDtnPrblty_Inv "Serial Data 200 Protected : Short Range Radar Right Rear Object Detection and Processing Trailer Object Presence Detection Probability Invalid";
BA_ "SignalType" SG_ 20 SRRRRODPTOEExistPrblty_Inv "ENM";
BA_ "SignalLongName" SG_ 20 SRRRRODPTOEExistPrblty_Inv "Serial Data 200 Protected : Short Range Radar Right Rear Object Detection and Processing Trailer Object Edge Existence Probability Invalid";
BA_ "SignalType" SG_ 20 SRRRRODPTODVhFrtAxVhHtch_Inv "ENM";
BA_ "SignalLongName" SG_ 20 SRRRRODPTODVhFrtAxVhHtch_Inv "Serial Data 200 Protected : Short Range Radar Right Rear Object Detection and Processing Trailer Object Distance Vehicle Front Axle To Vehicle Hitch Invalid";
BA_ "SignalType" SG_ 20 SRRRRODPTODTrHtchTrFrt_Inv "ENM";
BA_ "SignalLongName" SG_ 20 SRRRRODPTODTrHtchTrFrt_Inv "Serial Data 200 Protected : Short Range Radar Right Rear Object Detection and Processing Trailer Object Distance Trailer Hitch To Trailer Front Invalid";
BA_ "SignalType" SG_ 20 SRRRRODPTODTrHtchTrAx_Inv "ENM";
BA_ "SignalLongName" SG_ 20 SRRRRODPTODTrHtchTrAx_Inv "Serial Data 200 Protected : Short Range Radar Right Rear Object Detection and Processing Trailer Object Distance Trailer Hitch To Trailer Axle Invalid";
BA_ "SignalType" SG_ 20 SRRRRODPTrAtchdInfo "ENM";
BA_ "SignalLongName" SG_ 20 SRRRRODPTrAtchdInfo "Serial Data 200 Protected : Short Range Radar Right Rear Object Detection and Processing Trailer Attached Information";
BA_ "SignalType" SG_ 20 SRRRRODPTrObjExtrnInfo_Inv "ENM";
BA_ "SignalLongName" SG_ 20 SRRRRODPTrObjExtrnInfo_Inv "Serial Data 200 Protected : Short Range Radar Right Rear Object Detection and Processing Trailer Object External Information Invalid";
BA_ "SignalType" SG_ 20 SRRRRODPTOVYawRate_Inv "ENM";
BA_ "SignalLongName" SG_ 20 SRRRRODPTOVYawRate_Inv "Serial Data 200 Protected : Short Range Radar Right Rear Object Detection and Processing Trailer Object Variance Yaw Rate Invalid";
BA_ "SignalType" SG_ 20 SRRRRODPTOVWdth_Inv "ENM";
BA_ "SignalLongName" SG_ 20 SRRRRODPTOVWdth_Inv "Serial Data 200 Protected : Short Range Radar Right Rear Object Detection and Processing Trailer Object Variance Width Invalid";
BA_ "SignalType" SG_ 20 SRRRRODPTOVOrntn_Inv "ENM";
BA_ "SignalLongName" SG_ 20 SRRRRODPTOVOrntn_Inv "Serial Data 200 Protected : Short Range Radar Right Rear Object Detection and Processing Trailer Object Variance Orientation Invalid";
BA_ "SignalType" SG_ 20 SRRRRODPTOVLgth_Inv "ENM";
BA_ "SignalLongName" SG_ 20 SRRRRODPTOVLgth_Inv "Serial Data 200 Protected : Short Range Radar Right Rear Object Detection and Processing Trailer Object Variance Length Invalid";
BA_ "SignalType" SG_ 20 SRRRRODPTOVDVhFrtAxVhHtch_Inv "ENM";
BA_ "SignalLongName" SG_ 20 SRRRRODPTOVDVhFrtAxVhHtch_Inv "Serial Data 200 Protected : Short Range Radar Right Rear Object Detection and Processing Trailer Object Variance Distance Vehicle Front Axle To Vehicle Hitch Invalid";
BA_ "SignalType" SG_ 20 SRRRRODPTOVDTrHtchTrFrt_Inv "ENM";
BA_ "SignalLongName" SG_ 20 SRRRRODPTOVDTrHtchTrFrt_Inv "Serial Data 200 Protected : Short Range Radar Right Rear Object Detection and Processing Trailer Object Variance Distance Trailer Hitch To Trailer Front Invalid";
BA_ "SignalType" SG_ 20 SRRRRODPTOVDTrHtchTrAx_Inv "ENM";
BA_ "SignalLongName" SG_ 20 SRRRRODPTOVDTrHtchTrAx_Inv "Serial Data 200 Protected : Short Range Radar Right Rear Object Detection and Processing Trailer Object Variance Distance Trailer Hitch To Trailer Axle Invalid";
BA_ "SignalLongName" SG_ 20 SrlDat200_Filler "Serial Data 200 Protected : Filler";
BA_ "SignalType" SG_ 20 SRRRRODPTrObjYawRate_Inv "ENM";
BA_ "SignalLongName" SG_ 20 SRRRRODPTrObjYawRate_Inv "Serial Data 200 Protected : Short Range Radar Right Rear Object Detection and Processing Trailer Object Yaw Rate Invalid";
BA_ "SignalType" SG_ 20 SRRRRODPTrObjWdth_Inv "ENM";
BA_ "SignalLongName" SG_ 20 SRRRRODPTrObjWdth_Inv "Serial Data 200 Protected : Short Range Radar Right Rear Object Detection and Processing Trailer Object Width Invalid";
BA_ "SignalType" SG_ 20 SRRRRODPTrObjQlty_Inv "ENM";
BA_ "SignalLongName" SG_ 20 SRRRRODPTrObjQlty_Inv "Serial Data 200 Protected : Short Range Radar Right Rear Object Detection and Processing Trailer Object Quality Invalid";
BA_ "SignalType" SG_ 20 SRRRRODPTrObjOrntn_Inv "ENM";
BA_ "SignalLongName" SG_ 20 SRRRRODPTrObjOrntn_Inv "Serial Data 200 Protected : Short Range Radar Right Rear Object Detection and Processing Trailer Object Orientation Invalid";
BA_ "SignalType" SG_ 20 SRRRRODPTrObjLgth_Inv "ENM";
BA_ "SignalLongName" SG_ 20 SRRRRODPTrObjLgth_Inv "Serial Data 200 Protected : Short Range Radar Right Rear Object Detection and Processing Trailer Object Length Invalid";
BA_ "SignalLongName" SG_ 20 SrlDat200_FillerExtnd "Serial Data 200 Protected : Filler Extended";
BA_ "SignalLongName" SG_ 20 SD200P_ARC "Serial Data 200 Protected : Alive Rolling Count";
BA_ "SignalLongName" SG_ 906 SrlDat20_PCSM "Serial Data 20 Protected Counter Sync Message";
BA_ "SignalLongName" SG_ 226 SD20P_MAC "Serial Data 20 Protected : MAC";
BA_ "SignalLongName" SG_ 226 SD20P_FCnt "Serial Data 20 Protected : Freshness Counter";
BA_ "SignalLongName" SG_ 226 DIATMNP_DrvrIntdAxlTqMnAuth "Serial Data 20 Protected : Driver Intended Axle Torque Minimum Authenticated";
BA_ "SignalType" SG_ 226 DIATMNP_DrvrIntdAxlTqMnAuth_Inv "ENM";
BA_ "SignalLongName" SG_ 226 DIATMNP_DrvrIntdAxlTqMnAuth_Inv "Serial Data 20 Protected : Driver Intended Axle Torque Minimum Authenticated Invalid";
BA_ "SignalLongName" SG_ 226 DIATMXP_DrvrIntdAxlTqMxAuth "Serial Data 20 Protected : Driver Intended Axle Torque Maximum Authenticated";
BA_ "SignalType" SG_ 226 DIATMXP_DrvrIntdAxlTqMxAuth_Inv "ENM";
BA_ "SignalLongName" SG_ 226 DIATMXP_DrvrIntdAxlTqMxAuth_Inv "Serial Data 20 Protected : Driver Intended Axle Torque Maximum Authenticated Invalid";
BA_ "SignalLongName" SG_ 226 DITP_DrvrIntndAxlTrqAuth "Serial Data 20 Protected : Driver Intended Axle Torque Authenticated";
BA_ "SignalType" SG_ 226 DITP_DrvrIntndAxlTrqAuth_Inv "ENM";
BA_ "SignalLongName" SG_ 226 DITP_DrvrIntndAxlTrqAuth_Inv "Serial Data 20 Protected : Driver Intended Axle Torque Authenticated Invalid";
BA_ "SignalLongName" SG_ 226 DITP_DrvrIntndCrksftTrqAuth "Serial Data 20 Protected : Driver Intended Crankshaft Torque Authenticated";
BA_ "SignalLongName" SG_ 226 VMI1P_AccelActlPstnAuth "Serial Data 20 Protected : Accelerator Actual Position Authenticated";
BA_ "SignalLongName" SG_ 226 VMI1P_VehTopSpdLimArbdValAuth "Serial Data 20 Protected : Vehicle Top Speed Limit Arbitrated Value Authenticated";
BA_ "SignalType" SG_ 226 VMI1P_AccelPedOvrrdActvAuth "ENM";
BA_ "SignalLongName" SG_ 226 VMI1P_AccelPedOvrrdActvAuth "Serial Data 20 Protected : Accelerator Pedal Override Active Authenticated";
BA_ "SignalType" SG_ 226 VMI1P_AccelActlPstnAuth_Inv "ENM";
BA_ "SignalLongName" SG_ 226 VMI1P_AccelActlPstnAuth_Inv "Serial Data 20 Protected : Accelerator Actual Position Authenticated Invalid";
BA_ "SignalLongName" SG_ 226 SD20P_ARC "Serial Data 20 Protected : Alive Rolling Count";
BA_ "SignalType" SG_ 226 VMI1P_VehTopSpdLimModeActvAuth "ENM";
BA_ "SignalLongName" SG_ 226 VMI1P_VehTopSpdLimModeActvAuth "Serial Data 20 Protected : Vehicle Top Speed Limit Mode Active Authenticated";
BA_ "SignalLongName" SG_ 226 VehSpdAvgNDrvn "Serial Data 20 Protected : Vehicle Speed Average Non Driven";
BA_ "SignalLongName" SG_ 226 SD20P_Filler "Serial Data 20 Protected : Filler";
BA_ "SignalType" SG_ 226 VehSpdAvgNDrvn_Inv "ENM";
BA_ "SignalLongName" SG_ 226 VehSpdAvgNDrvn_Inv "Serial Data 20 Protected : Vehicle Speed Average Non Driven Invalid";
BA_ "SignalLongName" SG_ 1404 SrlDat22_PCSM "Serial Data 22 Protected Counter Sync Message";
BA_ "SignalLongName" SG_ 879 SD22P_MAC "Serial Data 22 Protected : MAC";
BA_ "SignalLongName" SG_ 879 SD22P_FCnt "Serial Data 22 Protected : Freshness Counter";
BA_ "SignalLongName" SG_ 879 EGI3P_CnvtTpSpLimRspValAuth "Serial Data 22 Protected : Convertible Top Speed Limit Response Value Authenticated";
BA_ "SignalType" SG_ 879 EGI3P_CnvtTpSpLimRspTypAuth "ENM";
BA_ "SignalLongName" SG_ 879 EGI3P_CnvtTpSpLimRspTypAuth "Serial Data 22 Protected : Convertible Top Speed Limit Response Type Authenticated";
BA_ "SignalType" SG_ 879 PSP_PrkNeutSwStatAuth_Inv "ENM";
BA_ "SignalLongName" SG_ 879 PSP_PrkNeutSwStatAuth_Inv "Serial Data 22 Protected : Park Neutral Switch State Authenticated Invalid";
BA_ "SignalType" SG_ 879 PSP_PrkNeutSwStatAuth "ENM";
BA_ "SignalLongName" SG_ 879 PSP_PrkNeutSwStatAuth "Serial Data 22 Protected : Park Neutral Switch State Authenticated";
BA_ "SignalType" SG_ 879 PSP_EngRnngAuth "ENM";
BA_ "SignalLongName" SG_ 879 PSP_EngRnngAuth "Serial Data 22 Protected : Engine Running Authenticated";
BA_ "SignalType" SG_ 879 PSP_ClchBtmTrvlAchvdAuth_Inv "ENM";
BA_ "SignalLongName" SG_ 879 PSP_ClchBtmTrvlAchvdAuth_Inv "Serial Data 22 Protected : Clutch Bottom of Travel Achieved Authenticated Invalid";
BA_ "SignalType" SG_ 879 PSP_ClchBtmTrvlAchvdAuth "ENM";
BA_ "SignalLongName" SG_ 879 PSP_ClchBtmTrvlAchvdAuth "Serial Data 22 Protected : Clutch Bottom of Travel Achieved Authenticated";
BA_ "SignalLongName" SG_ 879 SD22P_ARC "Serial Data 22 Protected : Alive Rolling Count";
BA_ "SignalType" SG_ 879 PSP_VehTheftImbChlgRespStsAuth "ENM";
BA_ "SignalLongName" SG_ 879 PSP_VehTheftImbChlgRespStsAuth "Serial Data 22 Protected : Vehicle Theft Immobilizer Challenge Response Status Authenticated";
BA_ "SignalType" SG_ 879 PSP_RmtVehStrtEngRnngAuth "ENM";
BA_ "SignalLongName" SG_ 879 PSP_RmtVehStrtEngRnngAuth "Serial Data 22 Protected : Remote Vehicle Start Engine Running Authenticated";
BA_ "SignalType" SG_ 879 PSP_PwrtrnCrnkAbrtdAuth "ENM";
BA_ "SignalLongName" SG_ 879 PSP_PwrtrnCrnkAbrtdAuth "Serial Data 22 Protected : Powertrain Crank Aborted Authenticated";
BA_ "SignalType" SG_ 879 PSP_PrplSysStlActvAuth "ENM";
BA_ "SignalLongName" SG_ 879 PSP_PrplSysStlActvAuth "Serial Data 22 Protected : Propulsion System Stall Active Authenticated";
BA_ "SignalType" SG_ 879 PSP_PrplSysActvAuth "ENM";
BA_ "SignalLongName" SG_ 879 PSP_PrplSysActvAuth "Serial Data 22 Protected : Propulsion System Active Authenticated";
BA_ "SignalLongName" SG_ 879 SD22P_Filler "Serial Data 22 Protected : Filler";
BA_ "SignalType" SG_ 879 PrplBrkThrotOvrrdReqd "ENM";
BA_ "SignalLongName" SG_ 879 PrplBrkThrotOvrrdReqd "Serial Data 22 Protected : Propulsion Brake Throttle Override Requested";
BA_ "SignalLongName" SG_ 72 SD30P_MAC "Serial Data 30 Protected : MAC";
BA_ "SignalLongName" SG_ 72 SD30P_FCnt "Serial Data 30 Protected : Freshness Counter";
BA_ "SignalType" SG_ 72 TGIP_TrnsEgdPrFlwStAuth "ENM";
BA_ "SignalLongName" SG_ 72 TGIP_TrnsEgdPrFlwStAuth "Serial Data 30 Protected : Transmission Engaged Powerflow State Authenticated";
BA_ "SignalType" SG_ 72 TARSP_TransActlRngAuth_Inv "ENM";
BA_ "SignalLongName" SG_ 72 TARSP_TransActlRngAuth_Inv "Serial Data 30 Protected : Transmission Actual Range Authenticated Invalid";
BA_ "SignalType" SG_ 72 TARSP_TransActlRngAuth_DuD "ENM";
BA_ "SignalLongName" SG_ 72 TARSP_TransActlRngAuth_DuD "Serial Data 30 Protected : Transmission Actual Range Authenticated Don't Use Data";
BA_ "SignalType" SG_ 72 TARSP_TransActlRngAuth "ENM";
BA_ "SignalLongName" SG_ 72 TARSP_TransActlRngAuth "Serial Data 30 Protected : Transmission Actual Range Authenticated";
BA_ "SignalType" SG_ 72 TRDP_TrnsPkRgDgLtFltAuth "ENM";
BA_ "SignalLongName" SG_ 72 TRDP_TrnsPkRgDgLtFltAuth "Serial Data 30 Protected : Transmission Park Range Diagnostic Limited Fault Authenticated";
BA_ "SignalType" SG_ 72 TRDP_TrnsPkRgDgCtFltAuth "ENM";
BA_ "SignalLongName" SG_ 72 TRDP_TrnsPkRgDgCtFltAuth "Serial Data 30 Protected : Transmission Park Range Diagnostic Critical Fault Authenticated";
BA_ "SignalType" SG_ 72 TRDP_TrnsNtRgDgLtFltAuth "ENM";
BA_ "SignalLongName" SG_ 72 TRDP_TrnsNtRgDgLtFltAuth "Serial Data 30 Protected : Transmission Neutral Range Diagnostic Limited Fault Authenticated";
BA_ "SignalType" SG_ 72 TRDP_TrnsNtRgDgCtFltAuth "ENM";
BA_ "SignalLongName" SG_ 72 TRDP_TrnsNtRgDgCtFltAuth "Serial Data 30 Protected : Transmission Neutral Range Diagnostic Critical Fault Authenticated";
BA_ "SignalType" SG_ 72 TRDP_TrnsFwDrvRDLFltAuth "ENM";
BA_ "SignalLongName" SG_ 72 TRDP_TrnsFwDrvRDLFltAuth "Serial Data 30 Protected : Transmission Forward Drive Range Diagnostic Limited Fault Authenticated";
BA_ "SignalType" SG_ 72 TRDP_TrnsFwDrvRDCFltAuth "ENM";
BA_ "SignalLongName" SG_ 72 TRDP_TrnsFwDrvRDCFltAuth "Serial Data 30 Protected : Transmission Forward Drive Range Diagnostic Critical Fault Authenticated";
BA_ "SignalType" SG_ 72 TGIP_TrnsEgdPrFlwStAuth_Inv "ENM";
BA_ "SignalLongName" SG_ 72 TGIP_TrnsEgdPrFlwStAuth_Inv "Serial Data 30 Protected : Transmission Engaged Powerflow State Authenticated Invalid";
BA_ "SignalLongName" SG_ 72 SD30P_Filler "Serial Data 30 Protected : Filler";
BA_ "SignalLongName" SG_ 72 SD30P_ARC "Serial Data 30 Protected : Alive Rolling Count";
BA_ "SignalType" SG_ 72 TSP_TmpDrvrShfCtlActvAuth "ENM";
BA_ "SignalLongName" SG_ 72 TSP_TmpDrvrShfCtlActvAuth "Serial Data 30 Protected : Temporary Driver Shift Control Active Authenticated";
BA_ "SignalType" SG_ 72 TSP_ElecRngSeltnInDrvActvAuth "ENM";
BA_ "SignalLongName" SG_ 72 TSP_ElecRngSeltnInDrvActvAuth "Serial Data 30 Protected : Electronic Range Selection in Drive Active Authenticated";
BA_ "SignalType" SG_ 72 TRDP_TrnsRvRgDgLtFltAuth "ENM";
BA_ "SignalLongName" SG_ 72 TRDP_TrnsRvRgDgLtFltAuth "Serial Data 30 Protected : Transmission Reverse Range Diagnostic Limited Fault Authenticated";
BA_ "SignalType" SG_ 72 TRDP_TrnsRvRgDgCtFltAuth "ENM";
BA_ "SignalLongName" SG_ 72 TRDP_TrnsRvRgDgCtFltAuth "Serial Data 30 Protected : Transmission Reverse Range Diagnostic Critical Fault Authenticated";
BA_ "SignalLongName" SG_ 897 SrlDat46_PCSM "Serial Data 46 Protected Counter Sync Message";
BA_ "SignalLongName" SG_ 57 SD46P_MAC "Serial Data 46 Protected : MAC";
BA_ "SignalLongName" SG_ 57 SD46P_FCnt "Serial Data 46 Protected : Freshness Counter";
BA_ "SignalLongName" SG_ 57 LatAccelAuth "Serial Data 46 Protected : Lateral Acceleration Authenticated";
BA_ "SignalLongName" SG_ 57 LongAccelAuth "Serial Data 46 Protected : Longitudinal Acceleration Authenticated";
BA_ "SignalType" SG_ 57 LatAccelSnsrCorrStsAuth "ENM";
BA_ "SignalLongName" SG_ 57 LatAccelSnsrCorrStsAuth "Serial Data 46 Protected : Lateral Acceleration Sensor Correlation Status Authenticated";
BA_ "SignalType" SG_ 57 LatAccelAuth_Inv "ENM";
BA_ "SignalLongName" SG_ 57 LatAccelAuth_Inv "Serial Data 46 Protected : Lateral Acceleration Authenticated Invalid";
BA_ "SignalType" SG_ 57 LongAccelAuth_Inv "ENM";
BA_ "SignalLongName" SG_ 57 LongAccelAuth_Inv "Serial Data 46 Protected : Longitudinal Acceleration Authenticated Invalid";
BA_ "SignalLongName" SG_ 57 YRP_RollRateAuth "Serial Data 46 Protected : Roll Rate Authenticated";
BA_ "SignalType" SG_ 57 VehAccelCalAuth "ENM";
BA_ "SignalLongName" SG_ 57 VehAccelCalAuth "Serial Data 46 Protected : Vehicle Acceleration Calibrated Authenticated";
BA_ "SignalType" SG_ 57 LongAccelSnsrCorrStsAuth "ENM";
BA_ "SignalLongName" SG_ 57 LongAccelSnsrCorrStsAuth "Serial Data 46 Protected : Longitudinal Acceleration Sensor Correlation Status Authenticated";
BA_ "SignalLongName" SG_ 57 YawRateAuth "Serial Data 46 Protected : Yaw Rate Authenticated";
BA_ "SignalType" SG_ 57 YRP_RollRateAuth_Inv "ENM";
BA_ "SignalLongName" SG_ 57 YRP_RollRateAuth_Inv "Serial Data 46 Protected : Roll Rate Authenticated Invalid";
BA_ "SignalType" SG_ 57 YRP_RollRateAuth_DuD "ENM";
BA_ "SignalLongName" SG_ 57 YRP_RollRateAuth_DuD "Serial Data 46 Protected : Roll Rate Authenticated Don't Use Data";
BA_ "SignalType" SG_ 57 YawRateAuth_DuD "ENM";
BA_ "SignalLongName" SG_ 57 YawRateAuth_DuD "Serial Data 46 Protected : Yaw Rate Authenticated Don't Use Data";
BA_ "SignalLongName" SG_ 57 SD46P_Filler "Serial Data 46 Protected : Filler";
BA_ "SignalLongName" SG_ 57 SD46P_ARC "Serial Data 46 Protected : Alive Rolling Count";
BA_ "SignalType" SG_ 57 YawRateCorrAuth "ENM";
BA_ "SignalLongName" SG_ 57 YawRateCorrAuth "Serial Data 46 Protected : Yaw Rate Correlation Authenticated";
BA_ "SignalType" SG_ 57 YawRateAuth_Inv "ENM";
BA_ "SignalLongName" SG_ 57 YawRateAuth_Inv "Serial Data 46 Protected : Yaw Rate Authenticated Invalid";
BA_ "SignalLongName" SG_ 57 SD46P_FillerExtnd "Serial Data 46 Protected : Filler Extended";
BA_ "SignalType" SG_ 57 VehAccelAuth_DuD "ENM";
BA_ "SignalLongName" SG_ 57 VehAccelAuth_DuD "Serial Data 46 Protected : Vehicle Acceleration Authenticated Don't Use Data";
BA_ "SignalLongName" SG_ 1403 SysPwrMode_PCSM "System Power Mode Protected Counter Sync Message";
BA_ "SignalLongName" SG_ 878 SPMP_MAC "System Power Mode Protected : MAC";
BA_ "SignalLongName" SG_ 878 SPMP_FCnt "System Power Mode Protected : Freshness Counter";
BA_ "SignalLongName" SG_ 878 RIP_RmtVehStrtBkupTmAuth "System Power Mode Protected : Remote Vehicle Start Backup Time Authenticated";
BA_ "SignalType" SG_ 878 RIP_PreRelAllwdAuth "ENM";
BA_ "SignalLongName" SG_ 878 RIP_PreRelAllwdAuth "System Power Mode Protected : Pre-Release Allowed Authenticated";
BA_ "SignalType" SG_ 878 RIP_ElecStrgColUnlckAllwdAuth "ENM";
BA_ "SignalLongName" SG_ 878 RIP_ElecStrgColUnlckAllwdAuth "System Power Mode Protected : Electric Steering Column Unlock Allowed Authenticated";
BA_ "SignalType" SG_ 878 BGI1P_RmtVehStrtReqAuth "ENM";
BA_ "SignalLongName" SG_ 878 BGI1P_RmtVehStrtReqAuth "System Power Mode Protected : Remote Vehicle Start Request Authenticated";
BA_ "SignalType" SG_ 878 BGI1P_RmtStrtStsAuth "ENM";
BA_ "SignalLongName" SG_ 878 BGI1P_RmtStrtStsAuth "System Power Mode Protected : Remote Vehicle Start Status Authenticated";
BA_ "SignalType" SG_ 878 SPMP_PriRunCrnkCmdActvAuth "ENM";
BA_ "SignalLongName" SG_ 878 SPMP_PriRunCrnkCmdActvAuth "System Power Mode Protected : Primary Run Crank Command Active Authenticated";
BA_ "SignalLongName" SG_ 878 SPMP_PV "System Power Mode Protected : Protection Value";
BA_ "SignalType" SG_ 878 RIP_StrtStopIgnSwPrssdAuth "ENM";
BA_ "SignalLongName" SG_ 878 RIP_StrtStopIgnSwPrssdAuth "System Power Mode Protected : Start/Stop Ignition Switch Pressed Authenticated";
BA_ "SignalType" SG_ 878 RIP_StrtStopIgnSwPrssdAuth_Inv "ENM";
BA_ "SignalLongName" SG_ 878 RIP_StrtStopIgnSwPrssdAuth_Inv "System Power Mode Protected : Start/Stop Ignition Switch Pressed Authenticated Invalid";
BA_ "SignalLongName" SG_ 878 SPMP_ARC "System Power Mode Protected : Alive Rolling Count";
BA_ "SignalType" SG_ 878 SPMP_SysPwrModeAuth_Inv "ENM";
BA_ "SignalLongName" SG_ 878 SPMP_SysPwrModeAuth_Inv "System Power Mode Protected : System Power Mode Authenticated Invalid";
BA_ "SignalType" SG_ 878 SPMP_SysPwrModeAuth "ENM";
BA_ "SignalLongName" SG_ 878 SPMP_SysPwrModeAuth "System Power Mode Protected : System Power Mode Authenticated";
BA_ "SignalType" SG_ 878 SPMP_PriRunCrnkCmdActvAuth_Inv "ENM";
BA_ "SignalLongName" SG_ 878 SPMP_PriRunCrnkCmdActvAuth_Inv "System Power Mode Protected : Primary Run Crank Command Active Authenticated Invalid";
BA_ "SignalLongName" SG_ 878 SPMP_Filler "System Power Mode Protected : Filler";
BA_ "SignalLongName" SG_ 122 SRRLRCODPREOTk1CrvAuth "Serial Data 185 : Short Range Radar Left Rear / Center Object Detection and Processing Road Edge Object Track 1 Curvature";
BA_ "SignalLongName" SG_ 122 SRRLRCODPREOTk1CrvDrvtAuth "Serial Data 185 : Short Range Radar Left Rear / Center Object Detection and Processing Road Edge Object Track 1 Curvature Derivative";
BA_ "SignalLongName" SG_ 122 SRRLRCODPREOTk2CrvAuth "Serial Data 185 : Short Range Radar Left Rear / Center Object Detection and Processing Road Edge Object Track 2 Curvature";
BA_ "SignalLongName" SG_ 122 SRRLRCODPREOTk2CrvDrvtAuth "Serial Data 185 : Short Range Radar Left Rear / Center Object Detection and Processing Road Edge Object Track 2 Curvature Derivative";
BA_ "SignalLongName" SG_ 122 SRRLRCODPREOTk3CrvAuth "Serial Data 185 : Short Range Radar Left Rear / Center Object Detection and Processing Road Edge Object Track 3 Curvature";
BA_ "SignalLongName" SG_ 122 SRRLRCODPREOTk3CrvDrvtAuth "Serial Data 185 : Short Range Radar Left Rear / Center Object Detection and Processing Road Edge Object Track 3 Curvature Derivative";
BA_ "SignalLongName" SG_ 122 SRRLRCODPVOTk10PoILgPsCAuth "Serial Data 185 : Short Range Radar Left Rear / Center Object Detection and Processing Vehicle Object Track 10 Point of Interest Longitudinal Position Covariance";
BA_ "SignalLongName" SG_ 122 SRRLRCODPVOTk1PoILgPsCAuth "Serial Data 185 : Short Range Radar Left Rear / Center Object Detection and Processing Vehicle Object Track 1 Point of Interest Longitudinal Position Covariance";
BA_ "SignalLongName" SG_ 122 SRRLRCODPVOTk2PoILgPsCAuth "Serial Data 185 : Short Range Radar Left Rear / Center Object Detection and Processing Vehicle Object Track 2 Point of Interest Longitudinal Position Covariance";
BA_ "SignalLongName" SG_ 122 SRRLRCODPVOTk3PoILgPsCAuth "Serial Data 185 : Short Range Radar Left Rear / Center Object Detection and Processing Vehicle Object Track 3 Point of Interest Longitudinal Position Covariance";
BA_ "SignalLongName" SG_ 122 SRRLRCODPVOTk4PoILgPsCAuth "Serial Data 185 : Short Range Radar Left Rear / Center Object Detection and Processing Vehicle Object Track 4 Point of Interest Longitudinal Position Covariance";
BA_ "SignalLongName" SG_ 122 SRRLRCODPVOTk5PoILgPsCAuth "Serial Data 185 : Short Range Radar Left Rear / Center Object Detection and Processing Vehicle Object Track 5 Point of Interest Longitudinal Position Covariance";
BA_ "SignalLongName" SG_ 122 SRRLRCODPVOTk6PoILgPsCAuth "Serial Data 185 : Short Range Radar Left Rear / Center Object Detection and Processing Vehicle Object Track 6 Point of Interest Longitudinal Position Covariance";
BA_ "SignalLongName" SG_ 122 SRRLRCODPVOTk7PoILgPsCAuth "Serial Data 185 : Short Range Radar Left Rear / Center Object Detection and Processing Vehicle Object Track 7 Point of Interest Longitudinal Position Covariance";
BA_ "SignalLongName" SG_ 122 SRRLRCODPVOTk8PoILgPsCAuth "Serial Data 185 : Short Range Radar Left Rear / Center Object Detection and Processing Vehicle Object Track 8 Point of Interest Longitudinal Position Covariance";
BA_ "SignalLongName" SG_ 122 SRRLRCODPVOTk9PoILgPsCAuth "Serial Data 185 : Short Range Radar Left Rear / Center Object Detection and Processing Vehicle Object Track 9 Point of Interest Longitudinal Position Covariance";
BA_ "SignalLongName" SG_ 122 SRRLRCODPVOTk10PoILPsCAuth "Serial Data 185 : Short Range Radar Left Rear / Center Object Detection and Processing Vehicle Object Track 10 Point of Interest Lateral Position Covariance";
BA_ "SignalLongName" SG_ 122 SRRLRCODPVOTk1PoILPsCAuth "Serial Data 185 : Short Range Radar Left Rear / Center Object Detection and Processing Vehicle Object Track 1 Point of Interest Lateral Position Covariance";
BA_ "SignalLongName" SG_ 122 SRRLRCODPVOTk2PoILPsCAuth "Serial Data 185 : Short Range Radar Left Rear / Center Object Detection and Processing Vehicle Object Track 2 Point of Interest Lateral Position Covariance";
BA_ "SignalLongName" SG_ 122 SRRLRCODPVOTk3PoILPsCAuth "Serial Data 185 : Short Range Radar Left Rear / Center Object Detection and Processing Vehicle Object Track 3 Point of Interest Lateral Position Covariance";
BA_ "SignalLongName" SG_ 122 SRRLRCODPVOTk4PoILPsCAuth "Serial Data 185 : Short Range Radar Left Rear / Center Object Detection and Processing Vehicle Object Track 4 Point of Interest Lateral Position Covariance";
BA_ "SignalLongName" SG_ 122 SRRLRCODPVOTk5PoILPsCAuth "Serial Data 185 : Short Range Radar Left Rear / Center Object Detection and Processing Vehicle Object Track 5 Point of Interest Lateral Position Covariance";
BA_ "SignalLongName" SG_ 122 SRRLRCODPVOTk6PoILPsCAuth "Serial Data 185 : Short Range Radar Left Rear / Center Object Detection and Processing Vehicle Object Track 6 Point of Interest Lateral Position Covariance";
BA_ "SignalLongName" SG_ 122 SRRLRCODPVOTk7PoILPsCAuth "Serial Data 185 : Short Range Radar Left Rear / Center Object Detection and Processing Vehicle Object Track 7 Point of Interest Lateral Position Covariance";
BA_ "SignalLongName" SG_ 122 SRRLRCODPVOTk8PoILPsCAuth "Serial Data 185 : Short Range Radar Left Rear / Center Object Detection and Processing Vehicle Object Track 8 Point of Interest Lateral Position Covariance";
BA_ "SignalLongName" SG_ 122 SRRLRCODPVOTk9PoILPsCAuth "Serial Data 185 : Short Range Radar Left Rear / Center Object Detection and Processing Vehicle Object Track 9 Point of Interest Lateral Position Covariance";
BA_ "SignalLongName" SG_ 122 SRRLRCODPAcqTmStmAuth "Serial Data 185 : Short Range Radar Left Rear / Center Object Detection and Processing Acquisition Time Stamp";
BA_ "SignalLongName" SG_ 122 SRRLRCODPIOTk10PoILgPsAuth "Serial Data 185 : Short Range Radar Left Rear / Center Object Detection and Processing Infrastructure Object Track 10 Point of Interest Longitudinal Position";
BA_ "SignalLongName" SG_ 122 SRRLRCODPIOTk1PoILgPsAuth "Serial Data 185 : Short Range Radar Left Rear / Center Object Detection and Processing Infrastructure Object Track 1 Point of Interest Longitudinal Position";
BA_ "SignalLongName" SG_ 122 SRRLRCODPIOTk2PoILgPsAuth "Serial Data 185 : Short Range Radar Left Rear / Center Object Detection and Processing Infrastructure Object Track 2 Point of Interest Longitudinal Position";
BA_ "SignalLongName" SG_ 122 SRRLRCODPIOTk3PoILgPsAuth "Serial Data 185 : Short Range Radar Left Rear / Center Object Detection and Processing Infrastructure Object Track 3 Point of Interest Longitudinal Position";
BA_ "SignalLongName" SG_ 122 SRRLRCODPIOTk4PoILgPsAuth "Serial Data 185 : Short Range Radar Left Rear / Center Object Detection and Processing Infrastructure Object Track 4 Point of Interest Longitudinal Position";
BA_ "SignalLongName" SG_ 122 SRRLRCODPIOTk5PoILgPsAuth "Serial Data 185 : Short Range Radar Left Rear / Center Object Detection and Processing Infrastructure Object Track 5 Point of Interest Longitudinal Position";
BA_ "SignalLongName" SG_ 122 SRRLRCODPIOTk6PoILgPsAuth "Serial Data 185 : Short Range Radar Left Rear / Center Object Detection and Processing Infrastructure Object Track 6 Point of Interest Longitudinal Position";
BA_ "SignalLongName" SG_ 122 SRRLRCODPIOTk7PoILgPsAuth "Serial Data 185 : Short Range Radar Left Rear / Center Object Detection and Processing Infrastructure Object Track 7 Point of Interest Longitudinal Position";
BA_ "SignalLongName" SG_ 122 SRRLRCODPIOTk8PoILgPsAuth "Serial Data 185 : Short Range Radar Left Rear / Center Object Detection and Processing Infrastructure Object Track 8 Point of Interest Longitudinal Position";
BA_ "SignalLongName" SG_ 122 SRRLRCODPIOTk9PoILgPsAuth "Serial Data 185 : Short Range Radar Left Rear / Center Object Detection and Processing Infrastructure Object Track 9 Point of Interest Longitudinal Position";
BA_ "SignalLongName" SG_ 122 SRRLRCODPPOTk1PoILgPsAuth "Serial Data 185 : Short Range Radar Left Rear / Center Object Detection and Processing Pedestrian Object Track 1 Point of Interest Longitudinal Position";
BA_ "SignalLongName" SG_ 122 SRRLRCODPPOTk2PoILgPsAuth "Serial Data 185 : Short Range Radar Left Rear / Center Object Detection and Processing Pedestrian Object Track 2 Point of Interest Longitudinal Position";
BA_ "SignalLongName" SG_ 122 SRRLRCODPPOTk3PoILgPsAuth "Serial Data 185 : Short Range Radar Left Rear / Center Object Detection and Processing Pedestrian Object Track 3 Point of Interest Longitudinal Position";
BA_ "SignalLongName" SG_ 122 SRRLRCODPPOTk4PoILgPsAuth "Serial Data 185 : Short Range Radar Left Rear / Center Object Detection and Processing Pedestrian Object Track 4 Point of Interest Longitudinal Position";
BA_ "SignalLongName" SG_ 122 SRRLRCODPPOTk5PoILgPsAuth "Serial Data 185 : Short Range Radar Left Rear / Center Object Detection and Processing Pedestrian Object Track 5 Point of Interest Longitudinal Position";
BA_ "SignalLongName" SG_ 122 SRRLRCODPREOTk1PsEndAuth "Serial Data 185 : Short Range Radar Left Rear / Center Object Detection and Processing Road Edge Object Track 1 Position End";
BA_ "SignalLongName" SG_ 122 SRRLRCODPREOTk1PsStrtAuth "Serial Data 185 : Short Range Radar Left Rear / Center Object Detection and Processing Road Edge Object Track 1 Position Start";
BA_ "SignalLongName" SG_ 122 SRRLRCODPREOTk2PsEndAuth "Serial Data 185 : Short Range Radar Left Rear / Center Object Detection and Processing Road Edge Object Track 2 Position End";
BA_ "SignalLongName" SG_ 122 SRRLRCODPREOTk2PsStrtAuth "Serial Data 185 : Short Range Radar Left Rear / Center Object Detection and Processing Road Edge Object Track 2 Position Start";
BA_ "SignalLongName" SG_ 122 SRRLRCODPREOTk3PsEndAuth "Serial Data 185 : Short Range Radar Left Rear / Center Object Detection and Processing Road Edge Object Track 3 Position End";
BA_ "SignalLongName" SG_ 122 SRRLRCODPREOTk3PsStrtAuth "Serial Data 185 : Short Range Radar Left Rear / Center Object Detection and Processing Road Edge Object Track 3 Position Start";
BA_ "SignalLongName" SG_ 122 SRRLRCODPVOTk10PoI2LgPsAuth "Serial Data 185 : Short Range Radar Left Rear / Center Object Detection and Processing Vehicle Object Track 10 Point of Interest 2nd Longitudinal Position";
BA_ "SignalLongName" SG_ 122 SRRLRCODPVOTk10PoILgPsAuth "Serial Data 185 : Short Range Radar Left Rear / Center Object Detection and Processing Vehicle Object Track 10 Point of Interest Longitudinal Position";
BA_ "SignalLongName" SG_ 122 SRRLRCODPVOTk10PoILgVAuth "Serial Data 185 : Short Range Radar Left Rear / Center Object Detection and Processing Vehicle Object Track 10 Point of Interest Longitudinal Velocity";
BA_ "SignalLongName" SG_ 122 SRRLRCODPVOTk1PoI2LgPsAuth "Serial Data 185 : Short Range Radar Left Rear / Center Object Detection and Processing Vehicle Object Track 1 Point of Interest 2nd Longitudinal Position";
BA_ "SignalLongName" SG_ 122 SRRLRCODPVOTk1PoILgPsAuth "Serial Data 185 : Short Range Radar Left Rear / Center Object Detection and Processing Vehicle Object Track 1 Point of Interest Longitudinal Position";
BA_ "SignalLongName" SG_ 122 SRRLRCODPVOTk1PoILgVAuth "Serial Data 185 : Short Range Radar Left Rear / Center Object Detection and Processing Vehicle Object Track 1 Point of Interest Longitudinal Velocity";
BA_ "SignalLongName" SG_ 122 SRRLRCODPVOTk2PoI2LgPsAuth "Serial Data 185 : Short Range Radar Left Rear / Center Object Detection and Processing Vehicle Object Track 2 Point of Interest 2nd Longitudinal Position";
BA_ "SignalLongName" SG_ 122 SRRLRCODPVOTk2PoILgPsAuth "Serial Data 185 : Short Range Radar Left Rear / Center Object Detection and Processing Vehicle Object Track 2 Point of Interest Longitudinal Position";
BA_ "SignalLongName" SG_ 122 SRRLRCODPVOTk2PoILgVAuth "Serial Data 185 : Short Range Radar Left Rear / Center Object Detection and Processing Vehicle Object Track 2 Point of Interest Longitudinal Velocity";
BA_ "SignalLongName" SG_ 122 SRRLRCODPVOTk3PoI2LgPsAuth "Serial Data 185 : Short Range Radar Left Rear / Center Object Detection and Processing Vehicle Object Track 3 Point of Interest 2nd Longitudinal Position";
BA_ "SignalLongName" SG_ 122 SRRLRCODPVOTk3PoILgPsAuth "Serial Data 185 : Short Range Radar Left Rear / Center Object Detection and Processing Vehicle Object Track 3 Point of Interest Longitudinal Position";
BA_ "SignalLongName" SG_ 122 SRRLRCODPVOTk3PoILgVAuth "Serial Data 185 : Short Range Radar Left Rear / Center Object Detection and Processing Vehicle Object Track 3 Point of Interest Longitudinal Velocity";
BA_ "SignalLongName" SG_ 122 SRRLRCODPVOTk4PoI2LgPsAuth "Serial Data 185 : Short Range Radar Left Rear / Center Object Detection and Processing Vehicle Object Track 4 Point of Interest 2nd Longitudinal Position";
BA_ "SignalLongName" SG_ 122 SRRLRCODPVOTk4PoILgPsAuth "Serial Data 185 : Short Range Radar Left Rear / Center Object Detection and Processing Vehicle Object Track 4 Point of Interest Longitudinal Position";
BA_ "SignalLongName" SG_ 122 SRRLRCODPVOTk4PoILgVAuth "Serial Data 185 : Short Range Radar Left Rear / Center Object Detection and Processing Vehicle Object Track 4 Point of Interest Longitudinal Velocity";
BA_ "SignalLongName" SG_ 122 SRRLRCODPVOTk5PoI2LgPsAuth "Serial Data 185 : Short Range Radar Left Rear / Center Object Detection and Processing Vehicle Object Track 5 Point of Interest 2nd Longitudinal Position";
BA_ "SignalLongName" SG_ 122 SRRLRCODPVOTk5PoILgPsAuth "Serial Data 185 : Short Range Radar Left Rear / Center Object Detection and Processing Vehicle Object Track 5 Point of Interest Longitudinal Position";
BA_ "SignalLongName" SG_ 122 SRRLRCODPVOTk5PoILgVAuth "Serial Data 185 : Short Range Radar Left Rear / Center Object Detection and Processing Vehicle Object Track 5 Point of Interest Longitudinal Velocity";
BA_ "SignalLongName" SG_ 122 SRRLRCODPVOTk6PoI2LgPsAuth "Serial Data 185 : Short Range Radar Left Rear / Center Object Detection and Processing Vehicle Object Track 6 Point of Interest 2nd Longitudinal Position";
BA_ "SignalLongName" SG_ 122 SRRLRCODPVOTk6PoILgPsAuth "Serial Data 185 : Short Range Radar Left Rear / Center Object Detection and Processing Vehicle Object Track 6 Point of Interest Longitudinal Position";
BA_ "SignalLongName" SG_ 122 SRRLRCODPVOTk6PoILgVAuth "Serial Data 185 : Short Range Radar Left Rear / Center Object Detection and Processing Vehicle Object Track 6 Point of Interest Longitudinal Velocity";
BA_ "SignalLongName" SG_ 122 SRRLRCODPVOTk7PoI2LgPsAuth "Serial Data 185 : Short Range Radar Left Rear / Center Object Detection and Processing Vehicle Object Track 7 Point of Interest 2nd Longitudinal Position";
BA_ "SignalLongName" SG_ 122 SRRLRCODPVOTk7PoILgPsAuth "Serial Data 185 : Short Range Radar Left Rear / Center Object Detection and Processing Vehicle Object Track 7 Point of Interest Longitudinal Position";
BA_ "SignalLongName" SG_ 122 SRRLRCODPVOTk7PoILgVAuth "Serial Data 185 : Short Range Radar Left Rear / Center Object Detection and Processing Vehicle Object Track 7 Point of Interest Longitudinal Velocity";
BA_ "SignalLongName" SG_ 122 SRRLRCODPVOTk8PoI2LgPsAuth "Serial Data 185 : Short Range Radar Left Rear / Center Object Detection and Processing Vehicle Object Track 8 Point of Interest 2nd Longitudinal Position";
BA_ "SignalLongName" SG_ 122 SRRLRCODPVOTk8PoILgPsAuth "Serial Data 185 : Short Range Radar Left Rear / Center Object Detection and Processing Vehicle Object Track 8 Point of Interest Longitudinal Position";
BA_ "SignalLongName" SG_ 122 SRRLRCODPVOTk8PoILgVAuth "Serial Data 185 : Short Range Radar Left Rear / Center Object Detection and Processing Vehicle Object Track 8 Point of Interest Longitudinal Velocity";
BA_ "SignalLongName" SG_ 122 SRRLRCODPVOTk9PoI2LgPsAuth "Serial Data 185 : Short Range Radar Left Rear / Center Object Detection and Processing Vehicle Object Track 9 Point of Interest 2nd Longitudinal Position";
BA_ "SignalLongName" SG_ 122 SRRLRCODPVOTk9PoILgPsAuth "Serial Data 185 : Short Range Radar Left Rear / Center Object Detection and Processing Vehicle Object Track 9 Point of Interest Longitudinal Position";
BA_ "SignalLongName" SG_ 122 SRRLRCODPVOTk9PoILgVAuth "Serial Data 185 : Short Range Radar Left Rear / Center Object Detection and Processing Vehicle Object Track 9 Point of Interest Longitudinal Velocity";
BA_ "SignalLongName" SG_ 122 SRRLRCODPIOTk10PoILPsAuth "Serial Data 185 : Short Range Radar Left Rear / Center Object Detection and Processing Infrastructure Object Track 10 Point of Interest Lateral Position";
BA_ "SignalLongName" SG_ 122 SRRLRCODPIOTk1PoILPsAuth "Serial Data 185 : Short Range Radar Left Rear / Center Object Detection and Processing Infrastructure Object Track 1 Point of Interest Lateral Position";
BA_ "SignalLongName" SG_ 122 SRRLRCODPIOTk2PoILPsAuth "Serial Data 185 : Short Range Radar Left Rear / Center Object Detection and Processing Infrastructure Object Track 2 Point of Interest Lateral Position";
BA_ "SignalLongName" SG_ 122 SRRLRCODPIOTk3PoILPsAuth "Serial Data 185 : Short Range Radar Left Rear / Center Object Detection and Processing Infrastructure Object Track 3 Point of Interest Lateral Position";
BA_ "SignalLongName" SG_ 122 SRRLRCODPIOTk4PoILPsAuth "Serial Data 185 : Short Range Radar Left Rear / Center Object Detection and Processing Infrastructure Object Track 4 Point of Interest Lateral Position";
BA_ "SignalLongName" SG_ 122 SRRLRCODPIOTk5PoILPsAuth "Serial Data 185 : Short Range Radar Left Rear / Center Object Detection and Processing Infrastructure Object Track 5 Point of Interest Lateral Position";
BA_ "SignalLongName" SG_ 122 SRRLRCODPIOTk6PoILPsAuth "Serial Data 185 : Short Range Radar Left Rear / Center Object Detection and Processing Infrastructure Object Track 6 Point of Interest Lateral Position";
BA_ "SignalLongName" SG_ 122 SRRLRCODPIOTk7PoILPsAuth "Serial Data 185 : Short Range Radar Left Rear / Center Object Detection and Processing Infrastructure Object Track 7 Point of Interest Lateral Position";
BA_ "SignalLongName" SG_ 122 SRRLRCODPIOTk8PoILPsAuth "Serial Data 185 : Short Range Radar Left Rear / Center Object Detection and Processing Infrastructure Object Track 8 Point of Interest Lateral Position";
BA_ "SignalLongName" SG_ 122 SRRLRCODPIOTk9PoILPsAuth "Serial Data 185 : Short Range Radar Left Rear / Center Object Detection and Processing Infrastructure Object Track 9 Point of Interest Lateral Position";
BA_ "SignalLongName" SG_ 122 SRRLRCODPPOTk1PoILPsAuth "Serial Data 185 : Short Range Radar Left Rear / Center Object Detection and Processing Pedestrian Object Track 1 Point of Interest Lateral Position";
BA_ "SignalLongName" SG_ 122 SRRLRCODPPOTk1PoILgVAuth "Serial Data 185 : Short Range Radar Left Rear / Center Object Detection and Processing Pedestrian Object Track 1 Point of Interest Longitudinal Velocity";
BA_ "SignalLongName" SG_ 122 SRRLRCODPPOTk2PoILPsAuth "Serial Data 185 : Short Range Radar Left Rear / Center Object Detection and Processing Pedestrian Object Track 2 Point of Interest Lateral Position";
BA_ "SignalLongName" SG_ 122 SRRLRCODPPOTk2PoILgVAuth "Serial Data 185 : Short Range Radar Left Rear / Center Object Detection and Processing Pedestrian Object Track 2 Point of Interest Longitudinal Velocity";
BA_ "SignalLongName" SG_ 122 SRRLRCODPPOTk3PoILPsAuth "Serial Data 185 : Short Range Radar Left Rear / Center Object Detection and Processing Pedestrian Object Track 3 Point of Interest Lateral Position";
BA_ "SignalLongName" SG_ 122 SRRLRCODPPOTk3PoILgVAuth "Serial Data 185 : Short Range Radar Left Rear / Center Object Detection and Processing Pedestrian Object Track 3 Point of Interest Longitudinal Velocity";
BA_ "SignalLongName" SG_ 122 SRRLRCODPPOTk4PoILPsAuth "Serial Data 185 : Short Range Radar Left Rear / Center Object Detection and Processing Pedestrian Object Track 4 Point of Interest Lateral Position";
BA_ "SignalLongName" SG_ 122 SRRLRCODPPOTk4PoILgVAuth "Serial Data 185 : Short Range Radar Left Rear / Center Object Detection and Processing Pedestrian Object Track 4 Point of Interest Longitudinal Velocity";
BA_ "SignalLongName" SG_ 122 SRRLRCODPPOTk5PoILPsAuth "Serial Data 185 : Short Range Radar Left Rear / Center Object Detection and Processing Pedestrian Object Track 5 Point of Interest Lateral Position";
BA_ "SignalLongName" SG_ 122 SRRLRCODPPOTk5PoILgVAuth "Serial Data 185 : Short Range Radar Left Rear / Center Object Detection and Processing Pedestrian Object Track 5 Point of Interest Longitudinal Velocity";
BA_ "SignalLongName" SG_ 122 SRRLRCODPREOTk1HdgAuth "Serial Data 185 : Short Range Radar Left Rear / Center Object Detection and Processing Road Edge Object Track 1 Heading";
BA_ "SignalLongName" SG_ 122 SRRLRCODPREOTk2HdgAuth "Serial Data 185 : Short Range Radar Left Rear / Center Object Detection and Processing Road Edge Object Track 2 Heading";
BA_ "SignalLongName" SG_ 122 SRRLRCODPREOTk3HdgAuth "Serial Data 185 : Short Range Radar Left Rear / Center Object Detection and Processing Road Edge Object Track 3 Heading";
BA_ "SignalLongName" SG_ 122 SRRLRCODPVOTk10PoI2LPsAuth "Serial Data 185 : Short Range Radar Left Rear / Center Object Detection and Processing Vehicle Object Track 10 Point of Interest 2nd Lateral Position";
BA_ "SignalLongName" SG_ 122 SRRLRCODPVOTk10PoILPsAuth "Serial Data 185 : Short Range Radar Left Rear / Center Object Detection and Processing Vehicle Object Track 10 Point of Interest Lateral Position";
BA_ "SignalLongName" SG_ 122 SRRLRCODPVOTk10PoILVCAuth "Serial Data 185 : Short Range Radar Left Rear / Center Object Detection and Processing Vehicle Object Track 10 Point of Interest Lateral Velocity Covariance";
BA_ "SignalLongName" SG_ 122 SRRLRCODPVOTk10PoILgVCAuth "Serial Data 185 : Short Range Radar Left Rear / Center Object Detection and Processing Vehicle Object Track 10 Point of Interest Longitudinal Velocity Covariance";
BA_ "SignalLongName" SG_ 122 SRRLRCODPVOTk1PoI2LPsAuth "Serial Data 185 : Short Range Radar Left Rear / Center Object Detection and Processing Vehicle Object Track 1 Point of Interest 2nd Lateral Position";
BA_ "SignalLongName" SG_ 122 SRRLRCODPVOTk1PoILPsAuth "Serial Data 185 : Short Range Radar Left Rear / Center Object Detection and Processing Vehicle Object Track 1 Point of Interest Lateral Position";
BA_ "SignalLongName" SG_ 122 SRRLRCODPVOTk1PoILVCAuth "Serial Data 185 : Short Range Radar Left Rear / Center Object Detection and Processing Vehicle Object Track 1 Point of Interest Lateral Velocity Covariance";
BA_ "SignalLongName" SG_ 122 SRRLRCODPVOTk1PoILgVCAuth "Serial Data 185 : Short Range Radar Left Rear / Center Object Detection and Processing Vehicle Object Track 1 Point of Interest Longitudinal Velocity Covariance";
BA_ "SignalLongName" SG_ 122 SRRLRCODPVOTk2PoI2LPsAuth "Serial Data 185 : Short Range Radar Left Rear / Center Object Detection and Processing Vehicle Object Track 2 Point of Interest 2nd Lateral Position";
BA_ "SignalLongName" SG_ 122 SRRLRCODPVOTk2PoILPsAuth "Serial Data 185 : Short Range Radar Left Rear / Center Object Detection and Processing Vehicle Object Track 2 Point of Interest Lateral Position";
BA_ "SignalLongName" SG_ 122 SRRLRCODPVOTk2PoILVCAuth "Serial Data 185 : Short Range Radar Left Rear / Center Object Detection and Processing Vehicle Object Track 2 Point of Interest Lateral Velocity Covariance";
BA_ "SignalLongName" SG_ 122 SRRLRCODPVOTk2PoILgVCAuth "Serial Data 185 : Short Range Radar Left Rear / Center Object Detection and Processing Vehicle Object Track 2 Point of Interest Longitudinal Velocity Covariance";
BA_ "SignalLongName" SG_ 122 SRRLRCODPVOTk3PoI2LPsAuth "Serial Data 185 : Short Range Radar Left Rear / Center Object Detection and Processing Vehicle Object Track 3 Point of Interest 2nd Lateral Position";
BA_ "SignalLongName" SG_ 122 SRRLRCODPVOTk3PoILPsAuth "Serial Data 185 : Short Range Radar Left Rear / Center Object Detection and Processing Vehicle Object Track 3 Point of Interest Lateral Position";
BA_ "SignalLongName" SG_ 122 SRRLRCODPVOTk3PoILVCAuth "Serial Data 185 : Short Range Radar Left Rear / Center Object Detection and Processing Vehicle Object Track 3 Point of Interest Lateral Velocity Covariance";
BA_ "SignalLongName" SG_ 122 SRRLRCODPVOTk3PoILgVCAuth "Serial Data 185 : Short Range Radar Left Rear / Center Object Detection and Processing Vehicle Object Track 3 Point of Interest Longitudinal Velocity Covariance";
BA_ "SignalLongName" SG_ 122 SRRLRCODPVOTk4PoI2LPsAuth "Serial Data 185 : Short Range Radar Left Rear / Center Object Detection and Processing Vehicle Object Track 4 Point of Interest 2nd Lateral Position";
BA_ "SignalLongName" SG_ 122 SRRLRCODPVOTk4PoILPsAuth "Serial Data 185 : Short Range Radar Left Rear / Center Object Detection and Processing Vehicle Object Track 4 Point of Interest Lateral Position";
BA_ "SignalLongName" SG_ 122 SRRLRCODPVOTk4PoILVCAuth "Serial Data 185 : Short Range Radar Left Rear / Center Object Detection and Processing Vehicle Object Track 4 Point of Interest Lateral Velocity Covariance";
BA_ "SignalLongName" SG_ 122 SRRLRCODPVOTk4PoILgVCAuth "Serial Data 185 : Short Range Radar Left Rear / Center Object Detection and Processing Vehicle Object Track 4 Point of Interest Longitudinal Velocity Covariance";
BA_ "SignalLongName" SG_ 122 SRRLRCODPVOTk5PoI2LPsAuth "Serial Data 185 : Short Range Radar Left Rear / Center Object Detection and Processing Vehicle Object Track 5 Point of Interest 2nd Lateral Position";
BA_ "SignalLongName" SG_ 122 SRRLRCODPVOTk5PoILPsAuth "Serial Data 185 : Short Range Radar Left Rear / Center Object Detection and Processing Vehicle Object Track 5 Point of Interest Lateral Position";
BA_ "SignalLongName" SG_ 122 SRRLRCODPVOTk5PoILVCAuth "Serial Data 185 : Short Range Radar Left Rear / Center Object Detection and Processing Vehicle Object Track 5 Point of Interest Lateral Velocity Covariance";
BA_ "SignalLongName" SG_ 122 SRRLRCODPVOTk5PoILgVCAuth "Serial Data 185 : Short Range Radar Left Rear / Center Object Detection and Processing Vehicle Object Track 5 Point of Interest Longitudinal Velocity Covariance";
BA_ "SignalLongName" SG_ 122 SRRLRCODPVOTk6PoI2LPsAuth "Serial Data 185 : Short Range Radar Left Rear / Center Object Detection and Processing Vehicle Object Track 6 Point of Interest 2nd Lateral Position";
BA_ "SignalLongName" SG_ 122 SRRLRCODPVOTk6PoILPsAuth "Serial Data 185 : Short Range Radar Left Rear / Center Object Detection and Processing Vehicle Object Track 6 Point of Interest Lateral Position";
BA_ "SignalLongName" SG_ 122 SRRLRCODPVOTk6PoILVCAuth "Serial Data 185 : Short Range Radar Left Rear / Center Object Detection and Processing Vehicle Object Track 6 Point of Interest Lateral Velocity Covariance";
BA_ "SignalLongName" SG_ 122 SRRLRCODPVOTk6PoILgVCAuth "Serial Data 185 : Short Range Radar Left Rear / Center Object Detection and Processing Vehicle Object Track 6 Point of Interest Longitudinal Velocity Covariance";
BA_ "SignalLongName" SG_ 122 SRRLRCODPVOTk7PoI2LPsAuth "Serial Data 185 : Short Range Radar Left Rear / Center Object Detection and Processing Vehicle Object Track 7 Point of Interest 2nd Lateral Position";
BA_ "SignalLongName" SG_ 122 SRRLRCODPVOTk7PoILPsAuth "Serial Data 185 : Short Range Radar Left Rear / Center Object Detection and Processing Vehicle Object Track 7 Point of Interest Lateral Position";
BA_ "SignalLongName" SG_ 122 SRRLRCODPVOTk7PoILVCAuth "Serial Data 185 : Short Range Radar Left Rear / Center Object Detection and Processing Vehicle Object Track 7 Point of Interest Lateral Velocity Covariance";
BA_ "SignalLongName" SG_ 122 SRRLRCODPVOTk7PoILgVCAuth "Serial Data 185 : Short Range Radar Left Rear / Center Object Detection and Processing Vehicle Object Track 7 Point of Interest Longitudinal Velocity Covariance";
BA_ "SignalLongName" SG_ 122 SRRLRCODPVOTk8PoI2LPsAuth "Serial Data 185 : Short Range Radar Left Rear / Center Object Detection and Processing Vehicle Object Track 8 Point of Interest 2nd Lateral Position";
BA_ "SignalLongName" SG_ 122 SRRLRCODPVOTk8PoILPsAuth "Serial Data 185 : Short Range Radar Left Rear / Center Object Detection and Processing Vehicle Object Track 8 Point of Interest Lateral Position";
BA_ "SignalLongName" SG_ 122 SRRLRCODPVOTk8PoILVCAuth "Serial Data 185 : Short Range Radar Left Rear / Center Object Detection and Processing Vehicle Object Track 8 Point of Interest Lateral Velocity Covariance";
BA_ "SignalLongName" SG_ 122 SRRLRCODPVOTk8PoILgVCAuth "Serial Data 185 : Short Range Radar Left Rear / Center Object Detection and Processing Vehicle Object Track 8 Point of Interest Longitudinal Velocity Covariance";
BA_ "SignalLongName" SG_ 122 SRRLRCODPVOTk9PoI2LPsAuth "Serial Data 185 : Short Range Radar Left Rear / Center Object Detection and Processing Vehicle Object Track 9 Point of Interest 2nd Lateral Position";
BA_ "SignalLongName" SG_ 122 SRRLRCODPVOTk9PoILPsAuth "Serial Data 185 : Short Range Radar Left Rear / Center Object Detection and Processing Vehicle Object Track 9 Point of Interest Lateral Position";
BA_ "SignalLongName" SG_ 122 SRRLRCODPVOTk9PoILVCAuth "Serial Data 185 : Short Range Radar Left Rear / Center Object Detection and Processing Vehicle Object Track 9 Point of Interest Lateral Velocity Covariance";
BA_ "SignalLongName" SG_ 122 SRRLRCODPVOTk9PoILgVCAuth "Serial Data 185 : Short Range Radar Left Rear / Center Object Detection and Processing Vehicle Object Track 9 Point of Interest Longitudinal Velocity Covariance";
BA_ "SignalLongName" SG_ 122 SRRLRCODPPOTk1PoILAAuth "Serial Data 185 : Short Range Radar Left Rear / Center Object Detection and Processing Pedestrian Object Track 1 Point of Interest Lateral Acceleration";
BA_ "SignalLongName" SG_ 122 SRRLRCODPPOTk1PoILVAuth "Serial Data 185 : Short Range Radar Left Rear / Center Object Detection and Processing Pedestrian Object Track 1 Point of Interest Lateral Velocity";
BA_ "SignalLongName" SG_ 122 SRRLRCODPPOTk1PoILgAAuth "Serial Data 185 : Short Range Radar Left Rear / Center Object Detection and Processing Pedestrian Object Track 1 Point of Interest Longitudinal Acceleration";
BA_ "SignalLongName" SG_ 122 SRRLRCODPPOTk2PoILAAuth "Serial Data 185 : Short Range Radar Left Rear / Center Object Detection and Processing Pedestrian Object Track 2 Point of Interest Lateral Acceleration";
BA_ "SignalLongName" SG_ 122 SRRLRCODPPOTk2PoILVAuth "Serial Data 185 : Short Range Radar Left Rear / Center Object Detection and Processing Pedestrian Object Track 2 Point of Interest Lateral Velocity";
BA_ "SignalLongName" SG_ 122 SRRLRCODPPOTk2PoILgAAuth "Serial Data 185 : Short Range Radar Left Rear / Center Object Detection and Processing Pedestrian Object Track 2 Point of Interest Longitudinal Acceleration";
BA_ "SignalLongName" SG_ 122 SRRLRCODPPOTk3PoILAAuth "Serial Data 185 : Short Range Radar Left Rear / Center Object Detection and Processing Pedestrian Object Track 3 Point of Interest Lateral Acceleration";
BA_ "SignalLongName" SG_ 122 SRRLRCODPPOTk3PoILVAuth "Serial Data 185 : Short Range Radar Left Rear / Center Object Detection and Processing Pedestrian Object Track 3 Point of Interest Lateral Velocity";
BA_ "SignalLongName" SG_ 122 SRRLRCODPPOTk3PoILgAAuth "Serial Data 185 : Short Range Radar Left Rear / Center Object Detection and Processing Pedestrian Object Track 3 Point of Interest Longitudinal Acceleration";
BA_ "SignalLongName" SG_ 122 SRRLRCODPPOTk4PoILAAuth "Serial Data 185 : Short Range Radar Left Rear / Center Object Detection and Processing Pedestrian Object Track 4 Point of Interest Lateral Acceleration";
BA_ "SignalLongName" SG_ 122 SRRLRCODPPOTk4PoILVAuth "Serial Data 185 : Short Range Radar Left Rear / Center Object Detection and Processing Pedestrian Object Track 4 Point of Interest Lateral Velocity";
BA_ "SignalLongName" SG_ 122 SRRLRCODPPOTk4PoILgAAuth "Serial Data 185 : Short Range Radar Left Rear / Center Object Detection and Processing Pedestrian Object Track 4 Point of Interest Longitudinal Acceleration";
BA_ "SignalLongName" SG_ 122 SRRLRCODPPOTk5PoILAAuth "Serial Data 185 : Short Range Radar Left Rear / Center Object Detection and Processing Pedestrian Object Track 5 Point of Interest Lateral Acceleration";
BA_ "SignalLongName" SG_ 122 SRRLRCODPPOTk5PoILVAuth "Serial Data 185 : Short Range Radar Left Rear / Center Object Detection and Processing Pedestrian Object Track 5 Point of Interest Lateral Velocity";
BA_ "SignalLongName" SG_ 122 SRRLRCODPPOTk5PoILgAAuth "Serial Data 185 : Short Range Radar Left Rear / Center Object Detection and Processing Pedestrian Object Track 5 Point of Interest Longitudinal Acceleration";
BA_ "SignalLongName" SG_ 122 SRRLRCODPREOTk1OfstAuth "Serial Data 185 : Short Range Radar Left Rear / Center Object Detection and Processing Road Edge Object Track 1 Offset";
BA_ "SignalLongName" SG_ 122 SRRLRCODPREOTk2OfstAuth "Serial Data 185 : Short Range Radar Left Rear / Center Object Detection and Processing Road Edge Object Track 2 Offset";
BA_ "SignalLongName" SG_ 122 SRRLRCODPREOTk3OfstAuth "Serial Data 185 : Short Range Radar Left Rear / Center Object Detection and Processing Road Edge Object Track 3 Offset";
BA_ "SignalLongName" SG_ 122 SRRLRCODPVOTk10PoILAAuth "Serial Data 185 : Short Range Radar Left Rear / Center Object Detection and Processing Vehicle Object Track 10 Point of Interest Lateral Acceleration";
BA_ "SignalLongName" SG_ 122 SRRLRCODPVOTk10PoILVAuth "Serial Data 185 : Short Range Radar Left Rear / Center Object Detection and Processing Vehicle Object Track 10 Point of Interest Lateral Velocity";
BA_ "SignalLongName" SG_ 122 SRRLRCODPVOTk10PoILgAAuth "Serial Data 185 : Short Range Radar Left Rear / Center Object Detection and Processing Vehicle Object Track 10 Point of Interest Longitudinal Acceleration";
BA_ "SignalLongName" SG_ 122 SRRLRCODPVOTk1PoILAAuth "Serial Data 185 : Short Range Radar Left Rear / Center Object Detection and Processing Vehicle Object Track 1 Point of Interest Lateral Acceleration";
BA_ "SignalLongName" SG_ 122 SRRLRCODPVOTk1PoILVAuth "Serial Data 185 : Short Range Radar Left Rear / Center Object Detection and Processing Vehicle Object Track 1 Point of Interest Lateral Velocity";
BA_ "SignalLongName" SG_ 122 SRRLRCODPVOTk1PoILgAAuth "Serial Data 185 : Short Range Radar Left Rear / Center Object Detection and Processing Vehicle Object Track 1 Point of Interest Longitudinal Acceleration";
BA_ "SignalLongName" SG_ 122 SRRLRCODPVOTk2PoILAAuth "Serial Data 185 : Short Range Radar Left Rear / Center Object Detection and Processing Vehicle Object Track 2 Point of Interest Lateral Acceleration";
BA_ "SignalLongName" SG_ 122 SRRLRCODPVOTk2PoILVAuth "Serial Data 185 : Short Range Radar Left Rear / Center Object Detection and Processing Vehicle Object Track 2 Point of Interest Lateral Velocity";
BA_ "SignalLongName" SG_ 122 SRRLRCODPVOTk2PoILgAAuth "Serial Data 185 : Short Range Radar Left Rear / Center Object Detection and Processing Vehicle Object Track 2 Point of Interest Longitudinal Acceleration";
BA_ "SignalLongName" SG_ 122 SRRLRCODPVOTk3PoILAAuth "Serial Data 185 : Short Range Radar Left Rear / Center Object Detection and Processing Vehicle Object Track 3 Point of Interest Lateral Acceleration";
BA_ "SignalLongName" SG_ 122 SRRLRCODPVOTk3PoILVAuth "Serial Data 185 : Short Range Radar Left Rear / Center Object Detection and Processing Vehicle Object Track 3 Point of Interest Lateral Velocity";
BA_ "SignalLongName" SG_ 122 SRRLRCODPVOTk3PoILgAAuth "Serial Data 185 : Short Range Radar Left Rear / Center Object Detection and Processing Vehicle Object Track 3 Point of Interest Longitudinal Acceleration";
BA_ "SignalLongName" SG_ 122 SRRLRCODPVOTk4PoILAAuth "Serial Data 185 : Short Range Radar Left Rear / Center Object Detection and Processing Vehicle Object Track 4 Point of Interest Lateral Acceleration";
BA_ "SignalLongName" SG_ 122 SRRLRCODPVOTk4PoILVAuth "Serial Data 185 : Short Range Radar Left Rear / Center Object Detection and Processing Vehicle Object Track 4 Point of Interest Lateral Velocity";
BA_ "SignalLongName" SG_ 122 SRRLRCODPVOTk4PoILgAAuth "Serial Data 185 : Short Range Radar Left Rear / Center Object Detection and Processing Vehicle Object Track 4 Point of Interest Longitudinal Acceleration";
BA_ "SignalLongName" SG_ 122 SRRLRCODPVOTk5PoILAAuth "Serial Data 185 : Short Range Radar Left Rear / Center Object Detection and Processing Vehicle Object Track 5 Point of Interest Lateral Acceleration";
BA_ "SignalLongName" SG_ 122 SRRLRCODPVOTk5PoILVAuth "Serial Data 185 : Short Range Radar Left Rear / Center Object Detection and Processing Vehicle Object Track 5 Point of Interest Lateral Velocity";
BA_ "SignalLongName" SG_ 122 SRRLRCODPVOTk5PoILgAAuth "Serial Data 185 : Short Range Radar Left Rear / Center Object Detection and Processing Vehicle Object Track 5 Point of Interest Longitudinal Acceleration";
BA_ "SignalLongName" SG_ 122 SRRLRCODPVOTk6PoILAAuth "Serial Data 185 : Short Range Radar Left Rear / Center Object Detection and Processing Vehicle Object Track 6 Point of Interest Lateral Acceleration";
BA_ "SignalLongName" SG_ 122 SRRLRCODPVOTk6PoILVAuth "Serial Data 185 : Short Range Radar Left Rear / Center Object Detection and Processing Vehicle Object Track 6 Point of Interest Lateral Velocity";
BA_ "SignalLongName" SG_ 122 SRRLRCODPVOTk6PoILgAAuth "Serial Data 185 : Short Range Radar Left Rear / Center Object Detection and Processing Vehicle Object Track 6 Point of Interest Longitudinal Acceleration";
BA_ "SignalLongName" SG_ 122 SRRLRCODPVOTk7PoILAAuth "Serial Data 185 : Short Range Radar Left Rear / Center Object Detection and Processing Vehicle Object Track 7 Point of Interest Lateral Acceleration";
BA_ "SignalLongName" SG_ 122 SRRLRCODPVOTk7PoILVAuth "Serial Data 185 : Short Range Radar Left Rear / Center Object Detection and Processing Vehicle Object Track 7 Point of Interest Lateral Velocity";
BA_ "SignalLongName" SG_ 122 SRRLRCODPVOTk7PoILgAAuth "Serial Data 185 : Short Range Radar Left Rear / Center Object Detection and Processing Vehicle Object Track 7 Point of Interest Longitudinal Acceleration";
BA_ "SignalLongName" SG_ 122 SRRLRCODPVOTk8PoILAAuth "Serial Data 185 : Short Range Radar Left Rear / Center Object Detection and Processing Vehicle Object Track 8 Point of Interest Lateral Acceleration";
BA_ "SignalLongName" SG_ 122 SRRLRCODPVOTk8PoILVAuth "Serial Data 185 : Short Range Radar Left Rear / Center Object Detection and Processing Vehicle Object Track 8 Point of Interest Lateral Velocity";
BA_ "SignalLongName" SG_ 122 SRRLRCODPVOTk8PoILgAAuth "Serial Data 185 : Short Range Radar Left Rear / Center Object Detection and Processing Vehicle Object Track 8 Point of Interest Longitudinal Acceleration";
BA_ "SignalLongName" SG_ 122 SRRLRCODPVOTk9PoILAAuth "Serial Data 185 : Short Range Radar Left Rear / Center Object Detection and Processing Vehicle Object Track 9 Point of Interest Lateral Acceleration";
BA_ "SignalLongName" SG_ 122 SRRLRCODPVOTk9PoILVAuth "Serial Data 185 : Short Range Radar Left Rear / Center Object Detection and Processing Vehicle Object Track 9 Point of Interest Lateral Velocity";
BA_ "SignalLongName" SG_ 122 SRRLRCODPVOTk9PoILgAAuth "Serial Data 185 : Short Range Radar Left Rear / Center Object Detection and Processing Vehicle Object Track 9 Point of Interest Longitudinal Acceleration";
BA_ "SignalLongName" SG_ 122 SRRLRCODPVOTk10PoILgthAuth "Serial Data 185 : Short Range Radar Left Rear / Center Object Detection and Processing Vehicle Object Track 10 Point of Interest Length";
BA_ "SignalLongName" SG_ 122 SRRLRCODPVOTk1PoILgthAuth "Serial Data 185 : Short Range Radar Left Rear / Center Object Detection and Processing Vehicle Object Track 1 Point of Interest Length";
BA_ "SignalLongName" SG_ 122 SRRLRCODPVOTk2PoILgthAuth "Serial Data 185 : Short Range Radar Left Rear / Center Object Detection and Processing Vehicle Object Track 2 Point of Interest Length";
BA_ "SignalLongName" SG_ 122 SRRLRCODPVOTk3PoILgthAuth "Serial Data 185 : Short Range Radar Left Rear / Center Object Detection and Processing Vehicle Object Track 3 Point of Interest Length";
BA_ "SignalLongName" SG_ 122 SRRLRCODPVOTk4PoILgthAuth "Serial Data 185 : Short Range Radar Left Rear / Center Object Detection and Processing Vehicle Object Track 4 Point of Interest Length";
BA_ "SignalLongName" SG_ 122 SRRLRCODPVOTk5PoILgthAuth "Serial Data 185 : Short Range Radar Left Rear / Center Object Detection and Processing Vehicle Object Track 5 Point of Interest Length";
BA_ "SignalLongName" SG_ 122 SRRLRCODPVOTk6PoILgthAuth "Serial Data 185 : Short Range Radar Left Rear / Center Object Detection and Processing Vehicle Object Track 6 Point of Interest Length";
BA_ "SignalLongName" SG_ 122 SRRLRCODPVOTk7PoILgthAuth "Serial Data 185 : Short Range Radar Left Rear / Center Object Detection and Processing Vehicle Object Track 7 Point of Interest Length";
BA_ "SignalLongName" SG_ 122 SRRLRCODPVOTk8PoILgthAuth "Serial Data 185 : Short Range Radar Left Rear / Center Object Detection and Processing Vehicle Object Track 8 Point of Interest Length";
BA_ "SignalLongName" SG_ 122 SRRLRCODPVOTk9PoILgthAuth "Serial Data 185 : Short Range Radar Left Rear / Center Object Detection and Processing Vehicle Object Track 9 Point of Interest Length";
BA_ "SignalLongName" SG_ 122 SRRLRCODPIOTk10IDAuth "Serial Data 185 : Short Range Radar Left Rear / Center Object Detection and Processing Infrastructure Object Track 10 ID";
BA_ "SignalLongName" SG_ 122 SRRLRCODPIOTk1IDAuth "Serial Data 185 : Short Range Radar Left Rear / Center Object Detection and Processing Infrastructure Object Track 1 ID";
BA_ "SignalLongName" SG_ 122 SRRLRCODPIOTk2IDAuth "Serial Data 185 : Short Range Radar Left Rear / Center Object Detection and Processing Infrastructure Object Track 2 ID";
BA_ "SignalLongName" SG_ 122 SRRLRCODPIOTk3IDAuth "Serial Data 185 : Short Range Radar Left Rear / Center Object Detection and Processing Infrastructure Object Track 3 ID";
BA_ "SignalLongName" SG_ 122 SRRLRCODPIOTk4IDAuth "Serial Data 185 : Short Range Radar Left Rear / Center Object Detection and Processing Infrastructure Object Track 4 ID";
BA_ "SignalLongName" SG_ 122 SRRLRCODPIOTk5IDAuth "Serial Data 185 : Short Range Radar Left Rear / Center Object Detection and Processing Infrastructure Object Track 5 ID";
BA_ "SignalLongName" SG_ 122 SRRLRCODPIOTk6IDAuth "Serial Data 185 : Short Range Radar Left Rear / Center Object Detection and Processing Infrastructure Object Track 6 ID";
BA_ "SignalLongName" SG_ 122 SRRLRCODPIOTk7IDAuth "Serial Data 185 : Short Range Radar Left Rear / Center Object Detection and Processing Infrastructure Object Track 7 ID";
BA_ "SignalLongName" SG_ 122 SRRLRCODPIOTk8IDAuth "Serial Data 185 : Short Range Radar Left Rear / Center Object Detection and Processing Infrastructure Object Track 8 ID";
BA_ "SignalLongName" SG_ 122 SRRLRCODPIOTk9IDAuth "Serial Data 185 : Short Range Radar Left Rear / Center Object Detection and Processing Infrastructure Object Track 9 ID";
BA_ "SignalLongName" SG_ 122 SRRLRCODPPOTk1IDAuth "Serial Data 185 : Short Range Radar Left Rear / Center Object Detection and Processing Pedestrian Object Track 1 ID";
BA_ "SignalLongName" SG_ 122 SRRLRCODPPOTk2IDAuth "Serial Data 185 : Short Range Radar Left Rear / Center Object Detection and Processing Pedestrian Object Track 2 ID";
BA_ "SignalLongName" SG_ 122 SRRLRCODPPOTk3IDAuth "Serial Data 185 : Short Range Radar Left Rear / Center Object Detection and Processing Pedestrian Object Track 3 ID";
BA_ "SignalLongName" SG_ 122 SRRLRCODPPOTk4IDAuth "Serial Data 185 : Short Range Radar Left Rear / Center Object Detection and Processing Pedestrian Object Track 4 ID";
BA_ "SignalLongName" SG_ 122 SRRLRCODPPOTk5IDAuth "Serial Data 185 : Short Range Radar Left Rear / Center Object Detection and Processing Pedestrian Object Track 5 ID";
BA_ "SignalLongName" SG_ 122 SRRLRCODPVOTk10IDAuth "Serial Data 185 : Short Range Radar Left Rear / Center Object Detection and Processing Vehicle Object Track 10 ID";
BA_ "SignalLongName" SG_ 122 SRRLRCODPVOTk1IDAuth "Serial Data 185 : Short Range Radar Left Rear / Center Object Detection and Processing Vehicle Object Track 1 ID";
BA_ "SignalLongName" SG_ 122 SRRLRCODPVOTk2IDAuth "Serial Data 185 : Short Range Radar Left Rear / Center Object Detection and Processing Vehicle Object Track 2 ID";
BA_ "SignalLongName" SG_ 122 SRRLRCODPVOTk3IDAuth "Serial Data 185 : Short Range Radar Left Rear / Center Object Detection and Processing Vehicle Object Track 3 ID";
BA_ "SignalLongName" SG_ 122 SRRLRCODPVOTk4IDAuth "Serial Data 185 : Short Range Radar Left Rear / Center Object Detection and Processing Vehicle Object Track 4 ID";
BA_ "SignalLongName" SG_ 122 SRRLRCODPVOTk5IDAuth "Serial Data 185 : Short Range Radar Left Rear / Center Object Detection and Processing Vehicle Object Track 5 ID";
BA_ "SignalLongName" SG_ 122 SRRLRCODPVOTk6IDAuth "Serial Data 185 : Short Range Radar Left Rear / Center Object Detection and Processing Vehicle Object Track 6 ID";
BA_ "SignalLongName" SG_ 122 SRRLRCODPVOTk7IDAuth "Serial Data 185 : Short Range Radar Left Rear / Center Object Detection and Processing Vehicle Object Track 7 ID";
BA_ "SignalLongName" SG_ 122 SRRLRCODPVOTk8IDAuth "Serial Data 185 : Short Range Radar Left Rear / Center Object Detection and Processing Vehicle Object Track 8 ID";
BA_ "SignalLongName" SG_ 122 SRRLRCODPVOTk9IDAuth "Serial Data 185 : Short Range Radar Left Rear / Center Object Detection and Processing Vehicle Object Track 9 ID";
BA_ "SignalLongName" SG_ 122 SRRLRCODPPOTk1InPthPotAuth "Serial Data 185 : Short Range Radar Left Rear / Center Object Detection and Processing Pedestrian Object Track 1 In Path Potential";
BA_ "SignalLongName" SG_ 122 SRRLRCODPPOTk2InPthPotAuth "Serial Data 185 : Short Range Radar Left Rear / Center Object Detection and Processing Pedestrian Object Track 2 In Path Potential";
BA_ "SignalLongName" SG_ 122 SRRLRCODPPOTk3InPthPotAuth "Serial Data 185 : Short Range Radar Left Rear / Center Object Detection and Processing Pedestrian Object Track 3 In Path Potential";
BA_ "SignalLongName" SG_ 122 SRRLRCODPPOTk4InPthPotAuth "Serial Data 185 : Short Range Radar Left Rear / Center Object Detection and Processing Pedestrian Object Track 4 In Path Potential";
BA_ "SignalLongName" SG_ 122 SRRLRCODPPOTk5InPthPotAuth "Serial Data 185 : Short Range Radar Left Rear / Center Object Detection and Processing Pedestrian Object Track 5 In Path Potential";
BA_ "SignalLongName" SG_ 122 SRRLRCODPVOTk10CICOPotAuth "Serial Data 185 : Short Range Radar Left Rear / Center Object Detection and Processing Vehicle Object Track 10 Cut In Cut Out Potential";
BA_ "SignalLongName" SG_ 122 SRRLRCODPVOTk1CICOPotAuth "Serial Data 185 : Short Range Radar Left Rear / Center Object Detection and Processing Vehicle Object Track 1 Cut In Cut Out Potential";
BA_ "SignalLongName" SG_ 122 SRRLRCODPVOTk2CICOPotAuth "Serial Data 185 : Short Range Radar Left Rear / Center Object Detection and Processing Vehicle Object Track 2 Cut In Cut Out Potential";
BA_ "SignalLongName" SG_ 122 SRRLRCODPVOTk3CICOPotAuth "Serial Data 185 : Short Range Radar Left Rear / Center Object Detection and Processing Vehicle Object Track 3 Cut In Cut Out Potential";
BA_ "SignalLongName" SG_ 122 SRRLRCODPVOTk4CICOPotAuth "Serial Data 185 : Short Range Radar Left Rear / Center Object Detection and Processing Vehicle Object Track 4 Cut In Cut Out Potential";
BA_ "SignalLongName" SG_ 122 SRRLRCODPVOTk5CICOPotAuth "Serial Data 185 : Short Range Radar Left Rear / Center Object Detection and Processing Vehicle Object Track 5 Cut In Cut Out Potential";
BA_ "SignalLongName" SG_ 122 SRRLRCODPVOTk6CICOPotAuth "Serial Data 185 : Short Range Radar Left Rear / Center Object Detection and Processing Vehicle Object Track 6 Cut In Cut Out Potential";
BA_ "SignalLongName" SG_ 122 SRRLRCODPVOTk7CICOPotAuth "Serial Data 185 : Short Range Radar Left Rear / Center Object Detection and Processing Vehicle Object Track 7 Cut In Cut Out Potential";
BA_ "SignalLongName" SG_ 122 SRRLRCODPVOTk8CICOPotAuth "Serial Data 185 : Short Range Radar Left Rear / Center Object Detection and Processing Vehicle Object Track 8 Cut In Cut Out Potential";
BA_ "SignalLongName" SG_ 122 SRRLRCODPVOTk9CICOPotAuth "Serial Data 185 : Short Range Radar Left Rear / Center Object Detection and Processing Vehicle Object Track 9 Cut In Cut Out Potential";
BA_ "SignalType" SG_ 122 SRRLRCODPIOTk10TypAuth "ENM";
BA_ "SignalLongName" SG_ 122 SRRLRCODPIOTk10TypAuth "Serial Data 185 : Short Range Radar Left Rear / Center Object Detection and Processing Infrastructure Object Track 10 Type";
BA_ "SignalType" SG_ 122 SRRLRCODPIOTk1TypAuth "ENM";
BA_ "SignalLongName" SG_ 122 SRRLRCODPIOTk1TypAuth "Serial Data 185 : Short Range Radar Left Rear / Center Object Detection and Processing Infrastructure Object Track 1 Type";
BA_ "SignalType" SG_ 122 SRRLRCODPIOTk2TypAuth "ENM";
BA_ "SignalLongName" SG_ 122 SRRLRCODPIOTk2TypAuth "Serial Data 185 : Short Range Radar Left Rear / Center Object Detection and Processing Infrastructure Object Track 2 Type";
BA_ "SignalType" SG_ 122 SRRLRCODPIOTk3TypAuth "ENM";
BA_ "SignalLongName" SG_ 122 SRRLRCODPIOTk3TypAuth "Serial Data 185 : Short Range Radar Left Rear / Center Object Detection and Processing Infrastructure Object Track 3 Type";
BA_ "SignalType" SG_ 122 SRRLRCODPIOTk4TypAuth "ENM";
BA_ "SignalLongName" SG_ 122 SRRLRCODPIOTk4TypAuth "Serial Data 185 : Short Range Radar Left Rear / Center Object Detection and Processing Infrastructure Object Track 4 Type";
BA_ "SignalType" SG_ 122 SRRLRCODPIOTk5TypAuth "ENM";
BA_ "SignalLongName" SG_ 122 SRRLRCODPIOTk5TypAuth "Serial Data 185 : Short Range Radar Left Rear / Center Object Detection and Processing Infrastructure Object Track 5 Type";
BA_ "SignalType" SG_ 122 SRRLRCODPIOTk6TypAuth "ENM";
BA_ "SignalLongName" SG_ 122 SRRLRCODPIOTk6TypAuth "Serial Data 185 : Short Range Radar Left Rear / Center Object Detection and Processing Infrastructure Object Track 6 Type";
BA_ "SignalType" SG_ 122 SRRLRCODPIOTk7TypAuth "ENM";
BA_ "SignalLongName" SG_ 122 SRRLRCODPIOTk7TypAuth "Serial Data 185 : Short Range Radar Left Rear / Center Object Detection and Processing Infrastructure Object Track 7 Type";
BA_ "SignalType" SG_ 122 SRRLRCODPIOTk8TypAuth "ENM";
BA_ "SignalLongName" SG_ 122 SRRLRCODPIOTk8TypAuth "Serial Data 185 : Short Range Radar Left Rear / Center Object Detection and Processing Infrastructure Object Track 8 Type";
BA_ "SignalType" SG_ 122 SRRLRCODPIOTk9TypAuth "ENM";
BA_ "SignalLongName" SG_ 122 SRRLRCODPIOTk9TypAuth "Serial Data 185 : Short Range Radar Left Rear / Center Object Detection and Processing Infrastructure Object Track 9 Type";
BA_ "SignalType" SG_ 122 SRRLRCODPPOTk1DynPrpAuth "ENM";
BA_ "SignalLongName" SG_ 122 SRRLRCODPPOTk1DynPrpAuth "Serial Data 185 : Short Range Radar Left Rear / Center Object Detection and Processing Pedestrian Object Track 1 Dynamic Property";
BA_ "SignalType" SG_ 122 SRRLRCODPPOTk2DynPrpAuth "ENM";
BA_ "SignalLongName" SG_ 122 SRRLRCODPPOTk2DynPrpAuth "Serial Data 185 : Short Range Radar Left Rear / Center Object Detection and Processing Pedestrian Object Track 2 Dynamic Property";
BA_ "SignalType" SG_ 122 SRRLRCODPPOTk3DynPrpAuth "ENM";
BA_ "SignalLongName" SG_ 122 SRRLRCODPPOTk3DynPrpAuth "Serial Data 185 : Short Range Radar Left Rear / Center Object Detection and Processing Pedestrian Object Track 3 Dynamic Property";
BA_ "SignalType" SG_ 122 SRRLRCODPPOTk4DynPrpAuth "ENM";
BA_ "SignalLongName" SG_ 122 SRRLRCODPPOTk4DynPrpAuth "Serial Data 185 : Short Range Radar Left Rear / Center Object Detection and Processing Pedestrian Object Track 4 Dynamic Property";
BA_ "SignalType" SG_ 122 SRRLRCODPPOTk5DynPrpAuth "ENM";
BA_ "SignalLongName" SG_ 122 SRRLRCODPPOTk5DynPrpAuth "Serial Data 185 : Short Range Radar Left Rear / Center Object Detection and Processing Pedestrian Object Track 5 Dynamic Property";
BA_ "SignalType" SG_ 122 SRRLRCODPREOTk1TypAuth "ENM";
BA_ "SignalLongName" SG_ 122 SRRLRCODPREOTk1TypAuth "Serial Data 185 : Short Range Radar Left Rear / Center Object Detection and Processing Road Edge Object Track 1 Type";
BA_ "SignalType" SG_ 122 SRRLRCODPREOTk2TypAuth "ENM";
BA_ "SignalLongName" SG_ 122 SRRLRCODPREOTk2TypAuth "Serial Data 185 : Short Range Radar Left Rear / Center Object Detection and Processing Road Edge Object Track 2 Type";
BA_ "SignalType" SG_ 122 SRRLRCODPREOTk3TypAuth "ENM";
BA_ "SignalLongName" SG_ 122 SRRLRCODPREOTk3TypAuth "Serial Data 185 : Short Range Radar Left Rear / Center Object Detection and Processing Road Edge Object Track 3 Type";
BA_ "SignalType" SG_ 122 SRRLRCODPRdTypAuth "ENM";
BA_ "SignalLongName" SG_ 122 SRRLRCODPRdTypAuth "Serial Data 185 : Short Range Radar Left Rear / Center Object Detection and Processing Road Type";
BA_ "SignalType" SG_ 122 SRRLRCODPVOTk10DynPrpAuth "ENM";
BA_ "SignalLongName" SG_ 122 SRRLRCODPVOTk10DynPrpAuth "Serial Data 185 : Short Range Radar Left Rear / Center Object Detection and Processing Vehicle Object Track 10 Dynamic Property";
BA_ "SignalType" SG_ 122 SRRLRCODPVOTk1DynPrpAuth "ENM";
BA_ "SignalLongName" SG_ 122 SRRLRCODPVOTk1DynPrpAuth "Serial Data 185 : Short Range Radar Left Rear / Center Object Detection and Processing Vehicle Object Track 1 Dynamic Property";
BA_ "SignalType" SG_ 122 SRRLRCODPVOTk2DynPrpAuth "ENM";
BA_ "SignalLongName" SG_ 122 SRRLRCODPVOTk2DynPrpAuth "Serial Data 185 : Short Range Radar Left Rear / Center Object Detection and Processing Vehicle Object Track 2 Dynamic Property";
BA_ "SignalType" SG_ 122 SRRLRCODPVOTk3DynPrpAuth "ENM";
BA_ "SignalLongName" SG_ 122 SRRLRCODPVOTk3DynPrpAuth "Serial Data 185 : Short Range Radar Left Rear / Center Object Detection and Processing Vehicle Object Track 3 Dynamic Property";
BA_ "SignalType" SG_ 122 SRRLRCODPVOTk4DynPrpAuth "ENM";
BA_ "SignalLongName" SG_ 122 SRRLRCODPVOTk4DynPrpAuth "Serial Data 185 : Short Range Radar Left Rear / Center Object Detection and Processing Vehicle Object Track 4 Dynamic Property";
BA_ "SignalType" SG_ 122 SRRLRCODPVOTk5DynPrpAuth "ENM";
BA_ "SignalLongName" SG_ 122 SRRLRCODPVOTk5DynPrpAuth "Serial Data 185 : Short Range Radar Left Rear / Center Object Detection and Processing Vehicle Object Track 5 Dynamic Property";
BA_ "SignalType" SG_ 122 SRRLRCODPVOTk6DynPrpAuth "ENM";
BA_ "SignalLongName" SG_ 122 SRRLRCODPVOTk6DynPrpAuth "Serial Data 185 : Short Range Radar Left Rear / Center Object Detection and Processing Vehicle Object Track 6 Dynamic Property";
BA_ "SignalType" SG_ 122 SRRLRCODPVOTk7DynPrpAuth "ENM";
BA_ "SignalLongName" SG_ 122 SRRLRCODPVOTk7DynPrpAuth "Serial Data 185 : Short Range Radar Left Rear / Center Object Detection and Processing Vehicle Object Track 7 Dynamic Property";
BA_ "SignalType" SG_ 122 SRRLRCODPVOTk8DynPrpAuth "ENM";
BA_ "SignalLongName" SG_ 122 SRRLRCODPVOTk8DynPrpAuth "Serial Data 185 : Short Range Radar Left Rear / Center Object Detection and Processing Vehicle Object Track 8 Dynamic Property";
BA_ "SignalType" SG_ 122 SRRLRCODPVOTk9DynPrpAuth "ENM";
BA_ "SignalLongName" SG_ 122 SRRLRCODPVOTk9DynPrpAuth "Serial Data 185 : Short Range Radar Left Rear / Center Object Detection and Processing Vehicle Object Track 9 Dynamic Property";
BA_ "SignalType" SG_ 122 SRRLRCODPConstrArDtnCnfdAuth "ENM";
BA_ "SignalLongName" SG_ 122 SRRLRCODPConstrArDtnCnfdAuth "Serial Data 185 : Short Range Radar Left Rear / Center Object Detection and Processing Construction Area Detection Confidence";
BA_ "SignalType" SG_ 122 SRRLRCODPConstrArDtnStsAuth "ENM";
BA_ "SignalLongName" SG_ 122 SRRLRCODPConstrArDtnStsAuth "Serial Data 185 : Short Range Radar Left Rear / Center Object Detection and Processing Construction Area Detection Status";
BA_ "SignalType" SG_ 122 SRRLRCODPIOTk10CnfdStsAuth "ENM";
BA_ "SignalLongName" SG_ 122 SRRLRCODPIOTk10CnfdStsAuth "Serial Data 185 : Short Range Radar Left Rear / Center Object Detection and Processing Infrastructure Object Track 10 Confidence Status";
BA_ "SignalType" SG_ 122 SRRLRCODPIOTk10ElvtnAuth "ENM";
BA_ "SignalLongName" SG_ 122 SRRLRCODPIOTk10ElvtnAuth "Serial Data 185 : Short Range Radar Left Rear / Center Object Detection and Processing Infrastructure Object Track 10 Elevation";
BA_ "SignalType" SG_ 122 SRRLRCODPIOTk10MStsAuth "ENM";
BA_ "SignalLongName" SG_ 122 SRRLRCODPIOTk10MStsAuth "Serial Data 185 : Short Range Radar Left Rear / Center Object Detection and Processing Infrastructure Object Track 10 Measurement Status";
BA_ "SignalType" SG_ 122 SRRLRCODPIOTk10TypCnfdAuth "ENM";
BA_ "SignalLongName" SG_ 122 SRRLRCODPIOTk10TypCnfdAuth "Serial Data 185 : Short Range Radar Left Rear / Center Object Detection and Processing Infrastructure Object Track 10 Type Confidence";
BA_ "SignalType" SG_ 122 SRRLRCODPIOTk1CnfdStsAuth "ENM";
BA_ "SignalLongName" SG_ 122 SRRLRCODPIOTk1CnfdStsAuth "Serial Data 185 : Short Range Radar Left Rear / Center Object Detection and Processing Infrastructure Object Track 1 Confidence Status";
BA_ "SignalType" SG_ 122 SRRLRCODPIOTk1ElvtnAuth "ENM";
BA_ "SignalLongName" SG_ 122 SRRLRCODPIOTk1ElvtnAuth "Serial Data 185 : Short Range Radar Left Rear / Center Object Detection and Processing Infrastructure Object Track 1 Elevation";
BA_ "SignalType" SG_ 122 SRRLRCODPIOTk1MStsAuth "ENM";
BA_ "SignalLongName" SG_ 122 SRRLRCODPIOTk1MStsAuth "Serial Data 185 : Short Range Radar Left Rear / Center Object Detection and Processing Infrastructure Object Track 1 Measurement Status";
BA_ "SignalType" SG_ 122 SRRLRCODPIOTk1TypCnfdAuth "ENM";
BA_ "SignalLongName" SG_ 122 SRRLRCODPIOTk1TypCnfdAuth "Serial Data 185 : Short Range Radar Left Rear / Center Object Detection and Processing Infrastructure Object Track 1 Type Confidence";
BA_ "SignalType" SG_ 122 SRRLRCODPIOTk2CnfdStsAuth "ENM";
BA_ "SignalLongName" SG_ 122 SRRLRCODPIOTk2CnfdStsAuth "Serial Data 185 : Short Range Radar Left Rear / Center Object Detection and Processing Infrastructure Object Track 2 Confidence Status";
BA_ "SignalType" SG_ 122 SRRLRCODPIOTk2ElvtnAuth "ENM";
BA_ "SignalLongName" SG_ 122 SRRLRCODPIOTk2ElvtnAuth "Serial Data 185 : Short Range Radar Left Rear / Center Object Detection and Processing Infrastructure Object Track 2 Elevation";
BA_ "SignalType" SG_ 122 SRRLRCODPIOTk2MStsAuth "ENM";
BA_ "SignalLongName" SG_ 122 SRRLRCODPIOTk2MStsAuth "Serial Data 185 : Short Range Radar Left Rear / Center Object Detection and Processing Infrastructure Object Track 2 Measurement Status";
BA_ "SignalType" SG_ 122 SRRLRCODPIOTk2TypCnfdAuth "ENM";
BA_ "SignalLongName" SG_ 122 SRRLRCODPIOTk2TypCnfdAuth "Serial Data 185 : Short Range Radar Left Rear / Center Object Detection and Processing Infrastructure Object Track 2 Type Confidence";
BA_ "SignalType" SG_ 122 SRRLRCODPIOTk3CnfdStsAuth "ENM";
BA_ "SignalLongName" SG_ 122 SRRLRCODPIOTk3CnfdStsAuth "Serial Data 185 : Short Range Radar Left Rear / Center Object Detection and Processing Infrastructure Object Track 3 Confidence Status";
BA_ "SignalType" SG_ 122 SRRLRCODPIOTk3ElvtnAuth "ENM";
BA_ "SignalLongName" SG_ 122 SRRLRCODPIOTk3ElvtnAuth "Serial Data 185 : Short Range Radar Left Rear / Center Object Detection and Processing Infrastructure Object Track 3 Elevation";
BA_ "SignalType" SG_ 122 SRRLRCODPIOTk3MStsAuth "ENM";
BA_ "SignalLongName" SG_ 122 SRRLRCODPIOTk3MStsAuth "Serial Data 185 : Short Range Radar Left Rear / Center Object Detection and Processing Infrastructure Object Track 3 Measurement Status";
BA_ "SignalType" SG_ 122 SRRLRCODPIOTk3TypCnfdAuth "ENM";
BA_ "SignalLongName" SG_ 122 SRRLRCODPIOTk3TypCnfdAuth "Serial Data 185 : Short Range Radar Left Rear / Center Object Detection and Processing Infrastructure Object Track 3 Type Confidence";
BA_ "SignalType" SG_ 122 SRRLRCODPIOTk4CnfdStsAuth "ENM";
BA_ "SignalLongName" SG_ 122 SRRLRCODPIOTk4CnfdStsAuth "Serial Data 185 : Short Range Radar Left Rear / Center Object Detection and Processing Infrastructure Object Track 4 Confidence Status";
BA_ "SignalType" SG_ 122 SRRLRCODPIOTk4ElvtnAuth "ENM";
BA_ "SignalLongName" SG_ 122 SRRLRCODPIOTk4ElvtnAuth "Serial Data 185 : Short Range Radar Left Rear / Center Object Detection and Processing Infrastructure Object Track 4 Elevation";
BA_ "SignalType" SG_ 122 SRRLRCODPIOTk4MStsAuth "ENM";
BA_ "SignalLongName" SG_ 122 SRRLRCODPIOTk4MStsAuth "Serial Data 185 : Short Range Radar Left Rear / Center Object Detection and Processing Infrastructure Object Track 4 Measurement Status";
BA_ "SignalType" SG_ 122 SRRLRCODPIOTk4TypCnfdAuth "ENM";
BA_ "SignalLongName" SG_ 122 SRRLRCODPIOTk4TypCnfdAuth "Serial Data 185 : Short Range Radar Left Rear / Center Object Detection and Processing Infrastructure Object Track 4 Type Confidence";
BA_ "SignalType" SG_ 122 SRRLRCODPIOTk5CnfdStsAuth "ENM";
BA_ "SignalLongName" SG_ 122 SRRLRCODPIOTk5CnfdStsAuth "Serial Data 185 : Short Range Radar Left Rear / Center Object Detection and Processing Infrastructure Object Track 5 Confidence Status";
BA_ "SignalType" SG_ 122 SRRLRCODPIOTk5ElvtnAuth "ENM";
BA_ "SignalLongName" SG_ 122 SRRLRCODPIOTk5ElvtnAuth "Serial Data 185 : Short Range Radar Left Rear / Center Object Detection and Processing Infrastructure Object Track 5 Elevation";
BA_ "SignalType" SG_ 122 SRRLRCODPIOTk5MStsAuth "ENM";
BA_ "SignalLongName" SG_ 122 SRRLRCODPIOTk5MStsAuth "Serial Data 185 : Short Range Radar Left Rear / Center Object Detection and Processing Infrastructure Object Track 5 Measurement Status";
BA_ "SignalType" SG_ 122 SRRLRCODPIOTk5TypCnfdAuth "ENM";
BA_ "SignalLongName" SG_ 122 SRRLRCODPIOTk5TypCnfdAuth "Serial Data 185 : Short Range Radar Left Rear / Center Object Detection and Processing Infrastructure Object Track 5 Type Confidence";
BA_ "SignalType" SG_ 122 SRRLRCODPIOTk6CnfdStsAuth "ENM";
BA_ "SignalLongName" SG_ 122 SRRLRCODPIOTk6CnfdStsAuth "Serial Data 185 : Short Range Radar Left Rear / Center Object Detection and Processing Infrastructure Object Track 6 Confidence Status";
BA_ "SignalType" SG_ 122 SRRLRCODPIOTk6ElvtnAuth "ENM";
BA_ "SignalLongName" SG_ 122 SRRLRCODPIOTk6ElvtnAuth "Serial Data 185 : Short Range Radar Left Rear / Center Object Detection and Processing Infrastructure Object Track 6 Elevation";
BA_ "SignalType" SG_ 122 SRRLRCODPIOTk6MStsAuth "ENM";
BA_ "SignalLongName" SG_ 122 SRRLRCODPIOTk6MStsAuth "Serial Data 185 : Short Range Radar Left Rear / Center Object Detection and Processing Infrastructure Object Track 6 Measurement Status";
BA_ "SignalType" SG_ 122 SRRLRCODPIOTk6TypCnfdAuth "ENM";
BA_ "SignalLongName" SG_ 122 SRRLRCODPIOTk6TypCnfdAuth "Serial Data 185 : Short Range Radar Left Rear / Center Object Detection and Processing Infrastructure Object Track 6 Type Confidence";
BA_ "SignalType" SG_ 122 SRRLRCODPIOTk7CnfdStsAuth "ENM";
BA_ "SignalLongName" SG_ 122 SRRLRCODPIOTk7CnfdStsAuth "Serial Data 185 : Short Range Radar Left Rear / Center Object Detection and Processing Infrastructure Object Track 7 Confidence Status";
BA_ "SignalType" SG_ 122 SRRLRCODPIOTk7ElvtnAuth "ENM";
BA_ "SignalLongName" SG_ 122 SRRLRCODPIOTk7ElvtnAuth "Serial Data 185 : Short Range Radar Left Rear / Center Object Detection and Processing Infrastructure Object Track 7 Elevation";
BA_ "SignalType" SG_ 122 SRRLRCODPIOTk7MStsAuth "ENM";
BA_ "SignalLongName" SG_ 122 SRRLRCODPIOTk7MStsAuth "Serial Data 185 : Short Range Radar Left Rear / Center Object Detection and Processing Infrastructure Object Track 7 Measurement Status";
BA_ "SignalType" SG_ 122 SRRLRCODPIOTk7TypCnfdAuth "ENM";
BA_ "SignalLongName" SG_ 122 SRRLRCODPIOTk7TypCnfdAuth "Serial Data 185 : Short Range Radar Left Rear / Center Object Detection and Processing Infrastructure Object Track 7 Type Confidence";
BA_ "SignalType" SG_ 122 SRRLRCODPIOTk8CnfdStsAuth "ENM";
BA_ "SignalLongName" SG_ 122 SRRLRCODPIOTk8CnfdStsAuth "Serial Data 185 : Short Range Radar Left Rear / Center Object Detection and Processing Infrastructure Object Track 8 Confidence Status";
BA_ "SignalType" SG_ 122 SRRLRCODPIOTk8ElvtnAuth "ENM";
BA_ "SignalLongName" SG_ 122 SRRLRCODPIOTk8ElvtnAuth "Serial Data 185 : Short Range Radar Left Rear / Center Object Detection and Processing Infrastructure Object Track 8 Elevation";
BA_ "SignalType" SG_ 122 SRRLRCODPIOTk8MStsAuth "ENM";
BA_ "SignalLongName" SG_ 122 SRRLRCODPIOTk8MStsAuth "Serial Data 185 : Short Range Radar Left Rear / Center Object Detection and Processing Infrastructure Object Track 8 Measurement Status";
BA_ "SignalType" SG_ 122 SRRLRCODPIOTk8TypCnfdAuth "ENM";
BA_ "SignalLongName" SG_ 122 SRRLRCODPIOTk8TypCnfdAuth "Serial Data 185 : Short Range Radar Left Rear / Center Object Detection and Processing Infrastructure Object Track 8 Type Confidence";
BA_ "SignalType" SG_ 122 SRRLRCODPIOTk9CnfdStsAuth "ENM";
BA_ "SignalLongName" SG_ 122 SRRLRCODPIOTk9CnfdStsAuth "Serial Data 185 : Short Range Radar Left Rear / Center Object Detection and Processing Infrastructure Object Track 9 Confidence Status";
BA_ "SignalType" SG_ 122 SRRLRCODPIOTk9ElvtnAuth "ENM";
BA_ "SignalLongName" SG_ 122 SRRLRCODPIOTk9ElvtnAuth "Serial Data 185 : Short Range Radar Left Rear / Center Object Detection and Processing Infrastructure Object Track 9 Elevation";
BA_ "SignalType" SG_ 122 SRRLRCODPIOTk9MStsAuth "ENM";
BA_ "SignalLongName" SG_ 122 SRRLRCODPIOTk9MStsAuth "Serial Data 185 : Short Range Radar Left Rear / Center Object Detection and Processing Infrastructure Object Track 9 Measurement Status";
BA_ "SignalType" SG_ 122 SRRLRCODPIOTk9TypCnfdAuth "ENM";
BA_ "SignalLongName" SG_ 122 SRRLRCODPIOTk9TypCnfdAuth "Serial Data 185 : Short Range Radar Left Rear / Center Object Detection and Processing Infrastructure Object Track 9 Type Confidence";
BA_ "SignalType" SG_ 122 SRRLRCODPMdCmdStsAuth "ENM";
BA_ "SignalLongName" SG_ 122 SRRLRCODPMdCmdStsAuth "Serial Data 185 : Short Range Radar Left Rear / Center Object Detection and Processing Mode Command Status";
BA_ "SignalType" SG_ 122 SRRLRCODPPOTk1CnfdStsAuth "ENM";
BA_ "SignalLongName" SG_ 122 SRRLRCODPPOTk1CnfdStsAuth "Serial Data 185 : Short Range Radar Left Rear / Center Object Detection and Processing Pedestrian Object Track 1 Confidence Status";
BA_ "SignalType" SG_ 122 SRRLRCODPPOTk1MStsAuth "ENM";
BA_ "SignalLongName" SG_ 122 SRRLRCODPPOTk1MStsAuth "Serial Data 185 : Short Range Radar Left Rear / Center Object Detection and Processing Pedestrian Object Track 1 Measurement Status";
BA_ "SignalType" SG_ 122 SRRLRCODPPOTk1TypAuth "ENM";
BA_ "SignalLongName" SG_ 122 SRRLRCODPPOTk1TypAuth "Serial Data 185 : Short Range Radar Left Rear / Center Object Detection and Processing Pedestrian Object Track 1 Type";
BA_ "SignalType" SG_ 122 SRRLRCODPPOTk1TypCnfdAuth "ENM";
BA_ "SignalLongName" SG_ 122 SRRLRCODPPOTk1TypCnfdAuth "Serial Data 185 : Short Range Radar Left Rear / Center Object Detection and Processing Pedestrian Object Track 1 Type Confidence";
BA_ "SignalType" SG_ 122 SRRLRCODPPOTk2CnfdStsAuth "ENM";
BA_ "SignalLongName" SG_ 122 SRRLRCODPPOTk2CnfdStsAuth "Serial Data 185 : Short Range Radar Left Rear / Center Object Detection and Processing Pedestrian Object Track 2 Confidence Status";
BA_ "SignalType" SG_ 122 SRRLRCODPPOTk2MStsAuth "ENM";
BA_ "SignalLongName" SG_ 122 SRRLRCODPPOTk2MStsAuth "Serial Data 185 : Short Range Radar Left Rear / Center Object Detection and Processing Pedestrian Object Track 2 Measurement Status";
BA_ "SignalType" SG_ 122 SRRLRCODPPOTk2TypAuth "ENM";
BA_ "SignalLongName" SG_ 122 SRRLRCODPPOTk2TypAuth "Serial Data 185 : Short Range Radar Left Rear / Center Object Detection and Processing Pedestrian Object Track 2 Type";
BA_ "SignalType" SG_ 122 SRRLRCODPPOTk2TypCnfdAuth "ENM";
BA_ "SignalLongName" SG_ 122 SRRLRCODPPOTk2TypCnfdAuth "Serial Data 185 : Short Range Radar Left Rear / Center Object Detection and Processing Pedestrian Object Track 2 Type Confidence";
BA_ "SignalType" SG_ 122 SRRLRCODPPOTk3CnfdStsAuth "ENM";
BA_ "SignalLongName" SG_ 122 SRRLRCODPPOTk3CnfdStsAuth "Serial Data 185 : Short Range Radar Left Rear / Center Object Detection and Processing Pedestrian Object Track 3 Confidence Status";
BA_ "SignalType" SG_ 122 SRRLRCODPPOTk3MStsAuth "ENM";
BA_ "SignalLongName" SG_ 122 SRRLRCODPPOTk3MStsAuth "Serial Data 185 : Short Range Radar Left Rear / Center Object Detection and Processing Pedestrian Object Track 3 Measurement Status";
BA_ "SignalType" SG_ 122 SRRLRCODPPOTk3TypAuth "ENM";
BA_ "SignalLongName" SG_ 122 SRRLRCODPPOTk3TypAuth "Serial Data 185 : Short Range Radar Left Rear / Center Object Detection and Processing Pedestrian Object Track 3 Type";
BA_ "SignalType" SG_ 122 SRRLRCODPPOTk3TypCnfdAuth "ENM";
BA_ "SignalLongName" SG_ 122 SRRLRCODPPOTk3TypCnfdAuth "Serial Data 185 : Short Range Radar Left Rear / Center Object Detection and Processing Pedestrian Object Track 3 Type Confidence";
BA_ "SignalType" SG_ 122 SRRLRCODPPOTk4CnfdStsAuth "ENM";
BA_ "SignalLongName" SG_ 122 SRRLRCODPPOTk4CnfdStsAuth "Serial Data 185 : Short Range Radar Left Rear / Center Object Detection and Processing Pedestrian Object Track 4 Confidence Status";
BA_ "SignalType" SG_ 122 SRRLRCODPPOTk4MStsAuth "ENM";
BA_ "SignalLongName" SG_ 122 SRRLRCODPPOTk4MStsAuth "Serial Data 185 : Short Range Radar Left Rear / Center Object Detection and Processing Pedestrian Object Track 4 Measurement Status";
BA_ "SignalType" SG_ 122 SRRLRCODPPOTk4TypAuth "ENM";
BA_ "SignalLongName" SG_ 122 SRRLRCODPPOTk4TypAuth "Serial Data 185 : Short Range Radar Left Rear / Center Object Detection and Processing Pedestrian Object Track 4 Type";
BA_ "SignalType" SG_ 122 SRRLRCODPPOTk4TypCnfdAuth "ENM";
BA_ "SignalLongName" SG_ 122 SRRLRCODPPOTk4TypCnfdAuth "Serial Data 185 : Short Range Radar Left Rear / Center Object Detection and Processing Pedestrian Object Track 4 Type Confidence";
BA_ "SignalType" SG_ 122 SRRLRCODPPOTk5CnfdStsAuth "ENM";
BA_ "SignalLongName" SG_ 122 SRRLRCODPPOTk5CnfdStsAuth "Serial Data 185 : Short Range Radar Left Rear / Center Object Detection and Processing Pedestrian Object Track 5 Confidence Status";
BA_ "SignalType" SG_ 122 SRRLRCODPPOTk5MStsAuth "ENM";
BA_ "SignalLongName" SG_ 122 SRRLRCODPPOTk5MStsAuth "Serial Data 185 : Short Range Radar Left Rear / Center Object Detection and Processing Pedestrian Object Track 5 Measurement Status";
BA_ "SignalType" SG_ 122 SRRLRCODPPOTk5TypAuth "ENM";
BA_ "SignalLongName" SG_ 122 SRRLRCODPPOTk5TypAuth "Serial Data 185 : Short Range Radar Left Rear / Center Object Detection and Processing Pedestrian Object Track 5 Type";
BA_ "SignalType" SG_ 122 SRRLRCODPPOTk5TypCnfdAuth "ENM";
BA_ "SignalLongName" SG_ 122 SRRLRCODPPOTk5TypCnfdAuth "Serial Data 185 : Short Range Radar Left Rear / Center Object Detection and Processing Pedestrian Object Track 5 Type Confidence";
BA_ "SignalType" SG_ 122 SRRLRCODPREOTk1CnfdStsAuth "ENM";
BA_ "SignalLongName" SG_ 122 SRRLRCODPREOTk1CnfdStsAuth "Serial Data 185 : Short Range Radar Left Rear / Center Object Detection and Processing Road Edge Object Track 1 Confidence Status";
BA_ "SignalType" SG_ 122 SRRLRCODPREOTk1TypCnfdAuth "ENM";
BA_ "SignalLongName" SG_ 122 SRRLRCODPREOTk1TypCnfdAuth "Serial Data 185 : Short Range Radar Left Rear / Center Object Detection and Processing Road Edge Object Track 1 Type Confidence";
BA_ "SignalType" SG_ 122 SRRLRCODPREOTk2CnfdStsAuth "ENM";
BA_ "SignalLongName" SG_ 122 SRRLRCODPREOTk2CnfdStsAuth "Serial Data 185 : Short Range Radar Left Rear / Center Object Detection and Processing Road Edge Object Track 2 Confidence Status";
BA_ "SignalType" SG_ 122 SRRLRCODPREOTk2TypCnfdAuth "ENM";
BA_ "SignalLongName" SG_ 122 SRRLRCODPREOTk2TypCnfdAuth "Serial Data 185 : Short Range Radar Left Rear / Center Object Detection and Processing Road Edge Object Track 2 Type Confidence";
BA_ "SignalType" SG_ 122 SRRLRCODPREOTk3CnfdStsAuth "ENM";
BA_ "SignalLongName" SG_ 122 SRRLRCODPREOTk3CnfdStsAuth "Serial Data 185 : Short Range Radar Left Rear / Center Object Detection and Processing Road Edge Object Track 3 Confidence Status";
BA_ "SignalType" SG_ 122 SRRLRCODPREOTk3TypCnfdAuth "ENM";
BA_ "SignalLongName" SG_ 122 SRRLRCODPREOTk3TypCnfdAuth "Serial Data 185 : Short Range Radar Left Rear / Center Object Detection and Processing Road Edge Object Track 3 Type Confidence";
BA_ "SignalType" SG_ 122 SRRLRCODPRdTypCnfdAuth "ENM";
BA_ "SignalLongName" SG_ 122 SRRLRCODPRdTypCnfdAuth "Serial Data 185 : Short Range Radar Left Rear / Center Object Detection and Processing Road Type Confidence";
BA_ "SignalType" SG_ 122 SRRLRCODPSwpBndwdthStsAuth "ENM";
BA_ "SignalLongName" SG_ 122 SRRLRCODPSwpBndwdthStsAuth "Serial Data 185 : Short Range Radar Left Rear / Center Object Detection and Processing Sweep Bandwidth Status";
BA_ "SignalType" SG_ 122 SRRLRCODPVOTk10CnfdStsAuth "ENM";
BA_ "SignalLongName" SG_ 122 SRRLRCODPVOTk10CnfdStsAuth "Serial Data 185 : Short Range Radar Left Rear / Center Object Detection and Processing Vehicle Object Track 10 Confidence Status";
BA_ "SignalType" SG_ 122 SRRLRCODPVOTk10MStsAuth "ENM";
BA_ "SignalLongName" SG_ 122 SRRLRCODPVOTk10MStsAuth "Serial Data 185 : Short Range Radar Left Rear / Center Object Detection and Processing Vehicle Object Track 10 Measurement Status";
BA_ "SignalType" SG_ 122 SRRLRCODPVOTk10TypCnfdAuth "ENM";
BA_ "SignalLongName" SG_ 122 SRRLRCODPVOTk10TypCnfdAuth "Serial Data 185 : Short Range Radar Left Rear / Center Object Detection and Processing Vehicle Object Track 10 Type Confidence";
BA_ "SignalType" SG_ 122 SRRLRCODPVOTk1CnfdStsAuth "ENM";
BA_ "SignalLongName" SG_ 122 SRRLRCODPVOTk1CnfdStsAuth "Serial Data 185 : Short Range Radar Left Rear / Center Object Detection and Processing Vehicle Object Track 1 Confidence Status";
BA_ "SignalType" SG_ 122 SRRLRCODPVOTk1MStsAuth "ENM";
BA_ "SignalLongName" SG_ 122 SRRLRCODPVOTk1MStsAuth "Serial Data 185 : Short Range Radar Left Rear / Center Object Detection and Processing Vehicle Object Track 1 Measurement Status";
BA_ "SignalType" SG_ 122 SRRLRCODPVOTk1TypCnfdAuth "ENM";
BA_ "SignalLongName" SG_ 122 SRRLRCODPVOTk1TypCnfdAuth "Serial Data 185 : Short Range Radar Left Rear / Center Object Detection and Processing Vehicle Object Track 1 Type Confidence";
BA_ "SignalType" SG_ 122 SRRLRCODPVOTk2CnfdStsAuth "ENM";
BA_ "SignalLongName" SG_ 122 SRRLRCODPVOTk2CnfdStsAuth "Serial Data 185 : Short Range Radar Left Rear / Center Object Detection and Processing Vehicle Object Track 2 Confidence Status";
BA_ "SignalType" SG_ 122 SRRLRCODPVOTk2MStsAuth "ENM";
BA_ "SignalLongName" SG_ 122 SRRLRCODPVOTk2MStsAuth "Serial Data 185 : Short Range Radar Left Rear / Center Object Detection and Processing Vehicle Object Track 2 Measurement Status";
BA_ "SignalType" SG_ 122 SRRLRCODPVOTk2TypCnfdAuth "ENM";
BA_ "SignalLongName" SG_ 122 SRRLRCODPVOTk2TypCnfdAuth "Serial Data 185 : Short Range Radar Left Rear / Center Object Detection and Processing Vehicle Object Track 2 Type Confidence";
BA_ "SignalType" SG_ 122 SRRLRCODPVOTk3CnfdStsAuth "ENM";
BA_ "SignalLongName" SG_ 122 SRRLRCODPVOTk3CnfdStsAuth "Serial Data 185 : Short Range Radar Left Rear / Center Object Detection and Processing Vehicle Object Track 3 Confidence Status";
BA_ "SignalType" SG_ 122 SRRLRCODPVOTk3MStsAuth "ENM";
BA_ "SignalLongName" SG_ 122 SRRLRCODPVOTk3MStsAuth "Serial Data 185 : Short Range Radar Left Rear / Center Object Detection and Processing Vehicle Object Track 3 Measurement Status";
BA_ "SignalType" SG_ 122 SRRLRCODPVOTk3TypCnfdAuth "ENM";
BA_ "SignalLongName" SG_ 122 SRRLRCODPVOTk3TypCnfdAuth "Serial Data 185 : Short Range Radar Left Rear / Center Object Detection and Processing Vehicle Object Track 3 Type Confidence";
BA_ "SignalType" SG_ 122 SRRLRCODPVOTk4CnfdStsAuth "ENM";
BA_ "SignalLongName" SG_ 122 SRRLRCODPVOTk4CnfdStsAuth "Serial Data 185 : Short Range Radar Left Rear / Center Object Detection and Processing Vehicle Object Track 4 Confidence Status";
BA_ "SignalType" SG_ 122 SRRLRCODPVOTk4MStsAuth "ENM";
BA_ "SignalLongName" SG_ 122 SRRLRCODPVOTk4MStsAuth "Serial Data 185 : Short Range Radar Left Rear / Center Object Detection and Processing Vehicle Object Track 4 Measurement Status";
BA_ "SignalType" SG_ 122 SRRLRCODPVOTk4TypCnfdAuth "ENM";
BA_ "SignalLongName" SG_ 122 SRRLRCODPVOTk4TypCnfdAuth "Serial Data 185 : Short Range Radar Left Rear / Center Object Detection and Processing Vehicle Object Track 4 Type Confidence";
BA_ "SignalType" SG_ 122 SRRLRCODPVOTk5CnfdStsAuth "ENM";
BA_ "SignalLongName" SG_ 122 SRRLRCODPVOTk5CnfdStsAuth "Serial Data 185 : Short Range Radar Left Rear / Center Object Detection and Processing Vehicle Object Track 5 Confidence Status";
BA_ "SignalType" SG_ 122 SRRLRCODPVOTk5MStsAuth "ENM";
BA_ "SignalLongName" SG_ 122 SRRLRCODPVOTk5MStsAuth "Serial Data 185 : Short Range Radar Left Rear / Center Object Detection and Processing Vehicle Object Track 5 Measurement Status";
BA_ "SignalType" SG_ 122 SRRLRCODPVOTk5TypCnfdAuth "ENM";
BA_ "SignalLongName" SG_ 122 SRRLRCODPVOTk5TypCnfdAuth "Serial Data 185 : Short Range Radar Left Rear / Center Object Detection and Processing Vehicle Object Track 5 Type Confidence";
BA_ "SignalType" SG_ 122 SRRLRCODPVOTk6CnfdStsAuth "ENM";
BA_ "SignalLongName" SG_ 122 SRRLRCODPVOTk6CnfdStsAuth "Serial Data 185 : Short Range Radar Left Rear / Center Object Detection and Processing Vehicle Object Track 6 Confidence Status";
BA_ "SignalType" SG_ 122 SRRLRCODPVOTk6MStsAuth "ENM";
BA_ "SignalLongName" SG_ 122 SRRLRCODPVOTk6MStsAuth "Serial Data 185 : Short Range Radar Left Rear / Center Object Detection and Processing Vehicle Object Track 6 Measurement Status";
BA_ "SignalType" SG_ 122 SRRLRCODPVOTk6TypCnfdAuth "ENM";
BA_ "SignalLongName" SG_ 122 SRRLRCODPVOTk6TypCnfdAuth "Serial Data 185 : Short Range Radar Left Rear / Center Object Detection and Processing Vehicle Object Track 6 Type Confidence";
BA_ "SignalType" SG_ 122 SRRLRCODPVOTk7CnfdStsAuth "ENM";
BA_ "SignalLongName" SG_ 122 SRRLRCODPVOTk7CnfdStsAuth "Serial Data 185 : Short Range Radar Left Rear / Center Object Detection and Processing Vehicle Object Track 7 Confidence Status";
BA_ "SignalType" SG_ 122 SRRLRCODPVOTk7MStsAuth "ENM";
BA_ "SignalLongName" SG_ 122 SRRLRCODPVOTk7MStsAuth "Serial Data 185 : Short Range Radar Left Rear / Center Object Detection and Processing Vehicle Object Track 7 Measurement Status";
BA_ "SignalType" SG_ 122 SRRLRCODPVOTk7TypCnfdAuth "ENM";
BA_ "SignalLongName" SG_ 122 SRRLRCODPVOTk7TypCnfdAuth "Serial Data 185 : Short Range Radar Left Rear / Center Object Detection and Processing Vehicle Object Track 7 Type Confidence";
BA_ "SignalType" SG_ 122 SRRLRCODPVOTk8CnfdStsAuth "ENM";
BA_ "SignalLongName" SG_ 122 SRRLRCODPVOTk8CnfdStsAuth "Serial Data 185 : Short Range Radar Left Rear / Center Object Detection and Processing Vehicle Object Track 8 Confidence Status";
BA_ "SignalType" SG_ 122 SRRLRCODPVOTk8MStsAuth "ENM";
BA_ "SignalLongName" SG_ 122 SRRLRCODPVOTk8MStsAuth "Serial Data 185 : Short Range Radar Left Rear / Center Object Detection and Processing Vehicle Object Track 8 Measurement Status";
BA_ "SignalType" SG_ 122 SRRLRCODPVOTk8TypCnfdAuth "ENM";
BA_ "SignalLongName" SG_ 122 SRRLRCODPVOTk8TypCnfdAuth "Serial Data 185 : Short Range Radar Left Rear / Center Object Detection and Processing Vehicle Object Track 8 Type Confidence";
BA_ "SignalType" SG_ 122 SRRLRCODPVOTk9CnfdStsAuth "ENM";
BA_ "SignalLongName" SG_ 122 SRRLRCODPVOTk9CnfdStsAuth "Serial Data 185 : Short Range Radar Left Rear / Center Object Detection and Processing Vehicle Object Track 9 Confidence Status";
BA_ "SignalType" SG_ 122 SRRLRCODPVOTk9MStsAuth "ENM";
BA_ "SignalLongName" SG_ 122 SRRLRCODPVOTk9MStsAuth "Serial Data 185 : Short Range Radar Left Rear / Center Object Detection and Processing Vehicle Object Track 9 Measurement Status";
BA_ "SignalType" SG_ 122 SRRLRCODPVOTk9TypCnfdAuth "ENM";
BA_ "SignalLongName" SG_ 122 SRRLRCODPVOTk9TypCnfdAuth "Serial Data 185 : Short Range Radar Left Rear / Center Object Detection and Processing Vehicle Object Track 9 Type Confidence";
BA_ "SignalType" SG_ 122 SRRLRCODPAcqTmStmAuth_Inv "ENM";
BA_ "SignalLongName" SG_ 122 SRRLRCODPAcqTmStmAuth_Inv "Serial Data 185 : Short Range Radar Left Rear / Center Object Detection and Processing Acquisition Time Stamp Invalid";
BA_ "SignalType" SG_ 122 SRRLRCODPServRqrdAuth "ENM";
BA_ "SignalLongName" SG_ 122 SRRLRCODPServRqrdAuth "Serial Data 185 : Short Range Radar Left Rear / Center Object Detection and Processing Service Required";
BA_ "SignalType" SG_ 122 SRRLRCODPSnsrBlckdAuth "ENM";
BA_ "SignalLongName" SG_ 122 SRRLRCODPSnsrBlckdAuth "Serial Data 185 : Short Range Radar Left Rear / Center Object Detection and Processing Sensor Blocked";
BA_ "SignalType" SG_ 122 SRRLRCODPSnsrUnvAuth "ENM";
BA_ "SignalLongName" SG_ 122 SRRLRCODPSnsrUnvAuth "Serial Data 185 : Short Range Radar Left Rear / Center Object Detection and Processing Sensor Unavailable";
BA_ "SignalType" SG_ 122 SRRLRCODPVOTk10DynPrpStsAuth "ENM";
BA_ "SignalLongName" SG_ 122 SRRLRCODPVOTk10DynPrpStsAuth "Serial Data 185 : Short Range Radar Left Rear / Center Object Detection and Processing Vehicle Object Track 10 Dynamic Property Status";
BA_ "SignalType" SG_ 122 SRRLRCODPVOTk1DynPrpStsAuth "ENM";
BA_ "SignalLongName" SG_ 122 SRRLRCODPVOTk1DynPrpStsAuth "Serial Data 185 : Short Range Radar Left Rear / Center Object Detection and Processing Vehicle Object Track 1 Dynamic Property Status";
BA_ "SignalType" SG_ 122 SRRLRCODPVOTk2DynPrpStsAuth "ENM";
BA_ "SignalLongName" SG_ 122 SRRLRCODPVOTk2DynPrpStsAuth "Serial Data 185 : Short Range Radar Left Rear / Center Object Detection and Processing Vehicle Object Track 2 Dynamic Property Status";
BA_ "SignalType" SG_ 122 SRRLRCODPVOTk3DynPrpStsAuth "ENM";
BA_ "SignalLongName" SG_ 122 SRRLRCODPVOTk3DynPrpStsAuth "Serial Data 185 : Short Range Radar Left Rear / Center Object Detection and Processing Vehicle Object Track 3 Dynamic Property Status";
BA_ "SignalType" SG_ 122 SRRLRCODPVOTk4DynPrpStsAuth "ENM";
BA_ "SignalLongName" SG_ 122 SRRLRCODPVOTk4DynPrpStsAuth "Serial Data 185 : Short Range Radar Left Rear / Center Object Detection and Processing Vehicle Object Track 4 Dynamic Property Status";
BA_ "SignalType" SG_ 122 SRRLRCODPVOTk5DynPrpStsAuth "ENM";
BA_ "SignalLongName" SG_ 122 SRRLRCODPVOTk5DynPrpStsAuth "Serial Data 185 : Short Range Radar Left Rear / Center Object Detection and Processing Vehicle Object Track 5 Dynamic Property Status";
BA_ "SignalType" SG_ 122 SRRLRCODPVOTk6DynPrpStsAuth "ENM";
BA_ "SignalLongName" SG_ 122 SRRLRCODPVOTk6DynPrpStsAuth "Serial Data 185 : Short Range Radar Left Rear / Center Object Detection and Processing Vehicle Object Track 6 Dynamic Property Status";
BA_ "SignalType" SG_ 122 SRRLRCODPVOTk7DynPrpStsAuth "ENM";
BA_ "SignalLongName" SG_ 122 SRRLRCODPVOTk7DynPrpStsAuth "Serial Data 185 : Short Range Radar Left Rear / Center Object Detection and Processing Vehicle Object Track 7 Dynamic Property Status";
BA_ "SignalType" SG_ 122 SRRLRCODPVOTk8DynPrpStsAuth "ENM";
BA_ "SignalLongName" SG_ 122 SRRLRCODPVOTk8DynPrpStsAuth "Serial Data 185 : Short Range Radar Left Rear / Center Object Detection and Processing Vehicle Object Track 8 Dynamic Property Status";
BA_ "SignalType" SG_ 122 SRRLRCODPVOTk9DynPrpStsAuth "ENM";
BA_ "SignalLongName" SG_ 122 SRRLRCODPVOTk9DynPrpStsAuth "Serial Data 185 : Short Range Radar Left Rear / Center Object Detection and Processing Vehicle Object Track 9 Dynamic Property Status";
BA_ "SignalLongName" SG_ 122 SD185BG1P_ARC "Serial Data 185 : Alive Rolling Count";
VAL_ 21 SRRSRRODPTrObjStatInfo 0 "Off" 1 "Passive" 2 "Active" 3 "Restricted" 4 "Invalid" ;
VAL_ 21 SRRSRRODPTOPDtnPrblty_Inv 0 "FALSE" 1 "TRUE" ;
VAL_ 21 SRRSRRODPTOEExistPrblty_Inv 0 "FALSE" 1 "TRUE" ;
VAL_ 21 SRRSRRODPTODVhFrtAxVhHtch_Inv 0 "FALSE" 1 "TRUE" ;
VAL_ 21 SRRSRRODPTODTrHtchTrFrt_Inv 0 "FALSE" 1 "TRUE" ;
VAL_ 21 SRRSRRODPTODTrHtchTrAx_Inv 0 "FALSE" 1 "TRUE" ;
VAL_ 21 SRRSRRODPTrAtchdInfo 0 "Not Attached" 1 "Attached" 2 "Unknown" 3 "Invalid" ;
VAL_ 21 SRRSRRODPTrObjExtrnInfo_Inv 0 "FALSE" 1 "TRUE" ;
VAL_ 21 SRRSRRODPTOVYawRate_Inv 0 "FALSE" 1 "TRUE" ;
VAL_ 21 SRRSRRODPTOVWdth_Inv 0 "FALSE" 1 "TRUE" ;
VAL_ 21 SRRSRRODPTOVOrntn_Inv 0 "FALSE" 1 "TRUE" ;
VAL_ 21 SRRSRRODPTOVLgth_Inv 0 "FALSE" 1 "TRUE" ;
VAL_ 21 SRRSRRODPTOVDVhFrtAxVhHtch_Inv 0 "FALSE" 1 "TRUE" ;
VAL_ 21 SRRSRRODPTOVDTrHtchTrFrt_Inv 0 "FALSE" 1 "TRUE" ;
VAL_ 21 SRRSRRODPTOVDTrHtchTrAx_Inv 0 "FALSE" 1 "TRUE" ;
VAL_ 21 SRRSRRODPTrObjYawRate_Inv 0 "FALSE" 1 "TRUE" ;
VAL_ 21 SRRSRRODPTrObjWdth_Inv 0 "FALSE" 1 "TRUE" ;
VAL_ 21 SRRSRRODPTrObjQlty_Inv 0 "FALSE" 1 "TRUE" ;
VAL_ 21 SRRSRRODPTrObjOrntn_Inv 0 "FALSE" 1 "TRUE" ;
VAL_ 21 SRRSRRODPTrObjLgth_Inv 0 "FALSE" 1 "TRUE" ;
VAL_ 20 SRRRRODPTrObjStatInfo 0 "Off" 1 "Passive" 2 "Active" 3 "Restricted" 4 "Invalid" ;
VAL_ 20 SRRRRODPTOPDtnPrblty_Inv 0 "FALSE" 1 "TRUE" ;
VAL_ 20 SRRRRODPTOEExistPrblty_Inv 0 "FALSE" 1 "TRUE" ;
VAL_ 20 SRRRRODPTODVhFrtAxVhHtch_Inv 0 "FALSE" 1 "TRUE" ;
VAL_ 20 SRRRRODPTODTrHtchTrFrt_Inv 0 "FALSE" 1 "TRUE" ;
VAL_ 20 SRRRRODPTODTrHtchTrAx_Inv 0 "FALSE" 1 "TRUE" ;
VAL_ 20 SRRRRODPTrAtchdInfo 0 "Not Attached" 1 "Attached" 2 "Unknown" 3 "Invalid" ;
VAL_ 20 SRRRRODPTrObjExtrnInfo_Inv 0 "FALSE" 1 "TRUE" ;
VAL_ 20 SRRRRODPTOVYawRate_Inv 0 "FALSE" 1 "TRUE" ;
VAL_ 20 SRRRRODPTOVWdth_Inv 0 "FALSE" 1 "TRUE" ;
VAL_ 20 SRRRRODPTOVOrntn_Inv 0 "FALSE" 1 "TRUE" ;
VAL_ 20 SRRRRODPTOVLgth_Inv 0 "FALSE" 1 "TRUE" ;
VAL_ 20 SRRRRODPTOVDVhFrtAxVhHtch_Inv 0 "FALSE" 1 "TRUE" ;
VAL_ 20 SRRRRODPTOVDTrHtchTrFrt_Inv 0 "FALSE" 1 "TRUE" ;
VAL_ 20 SRRRRODPTOVDTrHtchTrAx_Inv 0 "FALSE" 1 "TRUE" ;
VAL_ 20 SRRRRODPTrObjYawRate_Inv 0 "FALSE" 1 "TRUE" ;
VAL_ 20 SRRRRODPTrObjWdth_Inv 0 "FALSE" 1 "TRUE" ;
VAL_ 20 SRRRRODPTrObjQlty_Inv 0 "FALSE" 1 "TRUE" ;
VAL_ 20 SRRRRODPTrObjOrntn_Inv 0 "FALSE" 1 "TRUE" ;
VAL_ 20 SRRRRODPTrObjLgth_Inv 0 "FALSE" 1 "TRUE" ;
VAL_ 226 DIATMNP_DrvrIntdAxlTqMnAuth_Inv 0 "FALSE" 1 "TRUE" ;
VAL_ 226 DIATMXP_DrvrIntdAxlTqMxAuth_Inv 0 "FALSE" 1 "TRUE" ;
VAL_ 226 DITP_DrvrIntndAxlTrqAuth_Inv 0 "FALSE" 1 "TRUE" ;
VAL_ 226 VMI1P_AccelPedOvrrdActvAuth 0 "FALSE" 1 "TRUE" ;
VAL_ 226 VMI1P_AccelActlPstnAuth_Inv 0 "FALSE" 1 "TRUE" ;
VAL_ 226 VMI1P_VehTopSpdLimModeActvAuth 0 "FALSE" 1 "TRUE" ;
VAL_ 226 VehSpdAvgNDrvn_Inv 0 "FALSE" 1 "TRUE" ;
VAL_ 879 EGI3P_CnvtTpSpLimRspTypAuth 0 "Inactive" 1 "Faulted" 2 "Safety_woBrake" 3 "Safety_wBrake" 4 "OBD" 5 "nonOBD" 6 "Legislated" ;
VAL_ 879 PSP_PrkNeutSwStatAuth_Inv 0 "FALSE" 1 "TRUE" ;
VAL_ 879 PSP_PrkNeutSwStatAuth 0 "Park/Neutral" 1 "Not Park/Neutral" ;
VAL_ 879 PSP_EngRnngAuth 0 "FALSE" 1 "TRUE" ;
VAL_ 879 PSP_ClchBtmTrvlAchvdAuth_Inv 0 "FALSE" 1 "TRUE" ;
VAL_ 879 PSP_ClchBtmTrvlAchvdAuth 0 "FALSE" 1 "TRUE" ;
VAL_ 879 PSP_VehTheftImbChlgRespStsAuth 0 "Undetermined" 1 "Pass" 2 "Fail" ;
VAL_ 879 PSP_RmtVehStrtEngRnngAuth 0 "FALSE" 1 "TRUE" ;
VAL_ 879 PSP_PwrtrnCrnkAbrtdAuth 0 "FALSE" 1 "TRUE" ;
VAL_ 879 PSP_PrplSysStlActvAuth 0 "FALSE" 1 "TRUE" ;
VAL_ 879 PSP_PrplSysActvAuth 0 "FALSE" 1 "TRUE" ;
VAL_ 879 PrplBrkThrotOvrrdReqd 0 "FALSE" 1 "TRUE" ;
VAL_ 72 TGIP_TrnsEgdPrFlwStAuth 0 "Unavailable" 1 "No Powerflow" 2 "Drive Engaged" 3 "Reverse Engaged" ;
VAL_ 72 TARSP_TransActlRngAuth_Inv 0 "FALSE" 1 "TRUE" ;
VAL_ 72 TARSP_TransActlRngAuth_DuD 0 "FALSE" 1 "TRUE" ;
VAL_ 72 TARSP_TransActlRngAuth 0 "Unknown Position" 1 "Park Position" 2 "Between Park and Reverse" 3 "Reverse Position" 4 "Between Reverse and Neutral" 5 "Neutral Position" 6 "Between Neutral and First Drive Position" 7 "First Drive Position" 8 "Between First and Second Drive Position" 9 "Second Drive Position" 10 "Between Second and Third Position" 11 "Third Drive Position" 12 "Between Third and Fourth Position" 13 "Fourth Drive Position" ;
VAL_ 72 TRDP_TrnsPkRgDgLtFltAuth 0 "FALSE" 1 "TRUE" ;
VAL_ 72 TRDP_TrnsPkRgDgCtFltAuth 0 "FALSE" 1 "TRUE" ;
VAL_ 72 TRDP_TrnsNtRgDgLtFltAuth 0 "FALSE" 1 "TRUE" ;
VAL_ 72 TRDP_TrnsNtRgDgCtFltAuth 0 "FALSE" 1 "TRUE" ;
VAL_ 72 TRDP_TrnsFwDrvRDLFltAuth 0 "FALSE" 1 "TRUE" ;
VAL_ 72 TRDP_TrnsFwDrvRDCFltAuth 0 "FALSE" 1 "TRUE" ;
VAL_ 72 TGIP_TrnsEgdPrFlwStAuth_Inv 0 "FALSE" 1 "TRUE" ;
VAL_ 72 TSP_TmpDrvrShfCtlActvAuth 0 "FALSE" 1 "TRUE" ;
VAL_ 72 TSP_ElecRngSeltnInDrvActvAuth 0 "FALSE" 1 "TRUE" ;
VAL_ 72 TRDP_TrnsRvRgDgLtFltAuth 0 "FALSE" 1 "TRUE" ;
VAL_ 72 TRDP_TrnsRvRgDgCtFltAuth 0 "FALSE" 1 "TRUE" ;
VAL_ 57 LatAccelSnsrCorrStsAuth 0 "Unknown" 1 "NA" 2 "Correlated" 3 "Uncorellated" ;
VAL_ 57 LatAccelAuth_Inv 0 "FALSE" 1 "TRUE" ;
VAL_ 57 LongAccelAuth_Inv 0 "FALSE" 1 "TRUE" ;
VAL_ 57 VehAccelCalAuth 0 "FALSE" 1 "TRUE" ;
VAL_ 57 LongAccelSnsrCorrStsAuth 0 "Unknown" 1 "NA" 2 "Correlated" 3 "Uncorellated" ;
VAL_ 57 YRP_RollRateAuth_Inv 0 "FALSE" 1 "TRUE" ;
VAL_ 57 YRP_RollRateAuth_DuD 0 "FALSE" 1 "TRUE" ;
VAL_ 57 YawRateAuth_DuD 0 "FALSE" 1 "TRUE" ;
VAL_ 57 YawRateCorrAuth 0 "Unknown" 1 "NA" 2 "Correlated" 3 "Uncorellated" ;
VAL_ 57 YawRateAuth_Inv 0 "FALSE" 1 "TRUE" ;
VAL_ 57 VehAccelAuth_DuD 0 "FALSE" 1 "TRUE" ;
VAL_ 878 RIP_PreRelAllwdAuth 0 "FALSE" 1 "TRUE" ;
VAL_ 878 RIP_ElecStrgColUnlckAllwdAuth 0 "FALSE" 1 "TRUE" ;
VAL_ 878 BGI1P_RmtVehStrtReqAuth 0 "FALSE" 1 "TRUE" ;
VAL_ 878 BGI1P_RmtStrtStsAuth 0 "Inactive" 1 "Active" ;
VAL_ 878 SPMP_PriRunCrnkCmdActvAuth 0 "FALSE" 1 "TRUE" ;
VAL_ 878 RIP_StrtStopIgnSwPrssdAuth 0 "FALSE" 1 "TRUE" ;
VAL_ 878 RIP_StrtStopIgnSwPrssdAuth_Inv 0 "FALSE" 1 "TRUE" ;
VAL_ 878 SPMP_SysPwrModeAuth_Inv 0 "FALSE" 1 "TRUE" ;
VAL_ 878 SPMP_SysPwrModeAuth 0 "Off" 1 "Accessory" 2 "Run" 3 "Start Request" 4 "Propulsion" ;
VAL_ 878 SPMP_PriRunCrnkCmdActvAuth_Inv 0 "FALSE" 1 "TRUE" ;
VAL_ 122 SRRLRCODPIOTk10TypAuth 0 "Unknown" 1 "Guard Rail" 2 "Tunnel" 3 "Traffic Sign" 4 "Bridge" 5 "Pole" ;
VAL_ 122 SRRLRCODPIOTk1TypAuth 0 "Unknown" 1 "Guard Rail" 2 "Tunnel" 3 "Traffic Sign" 4 "Bridge" 5 "Pole" ;
VAL_ 122 SRRLRCODPIOTk2TypAuth 0 "Unknown" 1 "Guard Rail" 2 "Tunnel" 3 "Traffic Sign" 4 "Bridge" 5 "Pole" ;
VAL_ 122 SRRLRCODPIOTk3TypAuth 0 "Unknown" 1 "Guard Rail" 2 "Tunnel" 3 "Traffic Sign" 4 "Bridge" 5 "Pole" ;
VAL_ 122 SRRLRCODPIOTk4TypAuth 0 "Unknown" 1 "Guard Rail" 2 "Tunnel" 3 "Traffic Sign" 4 "Bridge" 5 "Pole" ;
VAL_ 122 SRRLRCODPIOTk5TypAuth 0 "Unknown" 1 "Guard Rail" 2 "Tunnel" 3 "Traffic Sign" 4 "Bridge" 5 "Pole" ;
VAL_ 122 SRRLRCODPIOTk6TypAuth 0 "Unknown" 1 "Guard Rail" 2 "Tunnel" 3 "Traffic Sign" 4 "Bridge" 5 "Pole" ;
VAL_ 122 SRRLRCODPIOTk7TypAuth 0 "Unknown" 1 "Guard Rail" 2 "Tunnel" 3 "Traffic Sign" 4 "Bridge" 5 "Pole" ;
VAL_ 122 SRRLRCODPIOTk8TypAuth 0 "Unknown" 1 "Guard Rail" 2 "Tunnel" 3 "Traffic Sign" 4 "Bridge" 5 "Pole" ;
VAL_ 122 SRRLRCODPIOTk9TypAuth 0 "Unknown" 1 "Guard Rail" 2 "Tunnel" 3 "Traffic Sign" 4 "Bridge" 5 "Pole" ;
VAL_ 122 SRRLRCODPPOTk1DynPrpAuth 0 "Has Never Moved" 1 "Has Moved But Currently Stopped" 2 "Moving In Same Direction As Host" 3 "Moving In Opposite Direction As Host" 4 "Crossing Path" ;
VAL_ 122 SRRLRCODPPOTk2DynPrpAuth 0 "Has Never Moved" 1 "Has Moved But Currently Stopped" 2 "Moving In Same Direction As Host" 3 "Moving In Opposite Direction As Host" 4 "Crossing Path" ;
VAL_ 122 SRRLRCODPPOTk3DynPrpAuth 0 "Has Never Moved" 1 "Has Moved But Currently Stopped" 2 "Moving In Same Direction As Host" 3 "Moving In Opposite Direction As Host" 4 "Crossing Path" ;
VAL_ 122 SRRLRCODPPOTk4DynPrpAuth 0 "Has Never Moved" 1 "Has Moved But Currently Stopped" 2 "Moving In Same Direction As Host" 3 "Moving In Opposite Direction As Host" 4 "Crossing Path" ;
VAL_ 122 SRRLRCODPPOTk5DynPrpAuth 0 "Has Never Moved" 1 "Has Moved But Currently Stopped" 2 "Moving In Same Direction As Host" 3 "Moving In Opposite Direction As Host" 4 "Crossing Path" ;
VAL_ 122 SRRLRCODPREOTk1TypAuth 0 "Unknown" 1 "Barriers" 2 "Guard Rails" 3 "Bridge Abutments" 4 "Edge of Road" 5 "Open Area" ;
VAL_ 122 SRRLRCODPREOTk2TypAuth 0 "Unknown" 1 "Barriers" 2 "Guard Rails" 3 "Bridge Abutments" 4 "Edge of Road" 5 "Open Area" ;
VAL_ 122 SRRLRCODPREOTk3TypAuth 0 "Unknown" 1 "Barriers" 2 "Guard Rails" 3 "Bridge Abutments" 4 "Edge of Road" 5 "Open Area" ;
VAL_ 122 SRRLRCODPRdTypAuth 0 "Unknown" 1 "City" 2 "Secondary Road" 3 "Highway" 4 "Construction Zone Entry" 5 "Construction Zone Exit" ;
VAL_ 122 SRRLRCODPVOTk10DynPrpAuth 0 "Has Never Moved" 1 "Moving In Same Direction As Host" 2 "Moving In Opposite Direction As Host" 3 "Crossing From Left To Right" 4 "Crossing From Right To Left" ;
VAL_ 122 SRRLRCODPVOTk1DynPrpAuth 0 "Has Never Moved" 1 "Moving In Same Direction As Host" 2 "Moving In Opposite Direction As Host" 3 "Crossing From Left To Right" 4 "Crossing From Right To Left" ;
VAL_ 122 SRRLRCODPVOTk2DynPrpAuth 0 "Has Never Moved" 1 "Moving In Same Direction As Host" 2 "Moving In Opposite Direction As Host" 3 "Crossing From Left To Right" 4 "Crossing From Right To Left" ;
VAL_ 122 SRRLRCODPVOTk3DynPrpAuth 0 "Has Never Moved" 1 "Moving In Same Direction As Host" 2 "Moving In Opposite Direction As Host" 3 "Crossing From Left To Right" 4 "Crossing From Right To Left" ;
VAL_ 122 SRRLRCODPVOTk4DynPrpAuth 0 "Has Never Moved" 1 "Moving In Same Direction As Host" 2 "Moving In Opposite Direction As Host" 3 "Crossing From Left To Right" 4 "Crossing From Right To Left" ;
VAL_ 122 SRRLRCODPVOTk5DynPrpAuth 0 "Has Never Moved" 1 "Moving In Same Direction As Host" 2 "Moving In Opposite Direction As Host" 3 "Crossing From Left To Right" 4 "Crossing From Right To Left" ;
VAL_ 122 SRRLRCODPVOTk6DynPrpAuth 0 "Has Never Moved" 1 "Moving In Same Direction As Host" 2 "Moving In Opposite Direction As Host" 3 "Crossing From Left To Right" 4 "Crossing From Right To Left" ;
VAL_ 122 SRRLRCODPVOTk7DynPrpAuth 0 "Has Never Moved" 1 "Moving In Same Direction As Host" 2 "Moving In Opposite Direction As Host" 3 "Crossing From Left To Right" 4 "Crossing From Right To Left" ;
VAL_ 122 SRRLRCODPVOTk8DynPrpAuth 0 "Has Never Moved" 1 "Moving In Same Direction As Host" 2 "Moving In Opposite Direction As Host" 3 "Crossing From Left To Right" 4 "Crossing From Right To Left" ;
VAL_ 122 SRRLRCODPVOTk9DynPrpAuth 0 "Has Never Moved" 1 "Moving In Same Direction As Host" 2 "Moving In Opposite Direction As Host" 3 "Crossing From Left To Right" 4 "Crossing From Right To Left" ;
VAL_ 122 SRRLRCODPConstrArDtnCnfdAuth 0 "Highly Speculative" 1 "Speculative" 2 "Confident" 3 "Highly Confident" ;
VAL_ 122 SRRLRCODPConstrArDtnStsAuth 0 "Not Detected" 1 "Detected" 2 "Unknown" ;
VAL_ 122 SRRLRCODPIOTk10CnfdStsAuth 0 "Highly Speculative" 1 "Speculative" 2 "Confident" 3 "Highly Confident" ;
VAL_ 122 SRRLRCODPIOTk10ElvtnAuth 0 "Not Elevated" 1 "Elevation Speculative" 2 "Elevation Confident" 3 "Elevation Very Confident" ;
VAL_ 122 SRRLRCODPIOTk10MStsAuth 0 "No Object" 1 "New Object" 2 "Latent Track Not Detected this Cycle" 3 "Measured this Cycle" ;
VAL_ 122 SRRLRCODPIOTk10TypCnfdAuth 0 "Highly Speculative" 1 "Speculative" 2 "Confident" 3 "Highly Confident" ;
VAL_ 122 SRRLRCODPIOTk1CnfdStsAuth 0 "Highly Speculative" 1 "Speculative" 2 "Confident" 3 "Highly Confident" ;
VAL_ 122 SRRLRCODPIOTk1ElvtnAuth 0 "Not Elevated" 1 "Elevation Speculative" 2 "Elevation Confident" 3 "Elevation Very Confident" ;
VAL_ 122 SRRLRCODPIOTk1MStsAuth 0 "No Object" 1 "New Object" 2 "Latent Track Not Detected this Cycle" 3 "Measured this Cycle" ;
VAL_ 122 SRRLRCODPIOTk1TypCnfdAuth 0 "Highly Speculative" 1 "Speculative" 2 "Confident" 3 "Highly Confident" ;
VAL_ 122 SRRLRCODPIOTk2CnfdStsAuth 0 "Highly Speculative" 1 "Speculative" 2 "Confident" 3 "Highly Confident" ;
VAL_ 122 SRRLRCODPIOTk2ElvtnAuth 0 "Not Elevated" 1 "Elevation Speculative" 2 "Elevation Confident" 3 "Elevation Very Confident" ;
VAL_ 122 SRRLRCODPIOTk2MStsAuth 0 "No Object" 1 "New Object" 2 "Latent Track Not Detected this Cycle" 3 "Measured this Cycle" ;
VAL_ 122 SRRLRCODPIOTk2TypCnfdAuth 0 "Highly Speculative" 1 "Speculative" 2 "Confident" 3 "Highly Confident" ;
VAL_ 122 SRRLRCODPIOTk3CnfdStsAuth 0 "Highly Speculative" 1 "Speculative" 2 "Confident" 3 "Highly Confident" ;
VAL_ 122 SRRLRCODPIOTk3ElvtnAuth 0 "Not Elevated" 1 "Elevation Speculative" 2 "Elevation Confident" 3 "Elevation Very Confident" ;
VAL_ 122 SRRLRCODPIOTk3MStsAuth 0 "No Object" 1 "New Object" 2 "Latent Track Not Detected this Cycle" 3 "Measured this Cycle" ;
VAL_ 122 SRRLRCODPIOTk3TypCnfdAuth 0 "Highly Speculative" 1 "Speculative" 2 "Confident" 3 "Highly Confident" ;
VAL_ 122 SRRLRCODPIOTk4CnfdStsAuth 0 "Highly Speculative" 1 "Speculative" 2 "Confident" 3 "Highly Confident" ;
VAL_ 122 SRRLRCODPIOTk4ElvtnAuth 0 "Not Elevated" 1 "Elevation Speculative" 2 "Elevation Confident" 3 "Elevation Very Confident" ;
VAL_ 122 SRRLRCODPIOTk4MStsAuth 0 "No Object" 1 "New Object" 2 "Latent Track Not Detected this Cycle" 3 "Measured this Cycle" ;
VAL_ 122 SRRLRCODPIOTk4TypCnfdAuth 0 "Highly Speculative" 1 "Speculative" 2 "Confident" 3 "Highly Confident" ;
VAL_ 122 SRRLRCODPIOTk5CnfdStsAuth 0 "Highly Speculative" 1 "Speculative" 2 "Confident" 3 "Highly Confident" ;
VAL_ 122 SRRLRCODPIOTk5ElvtnAuth 0 "Not Elevated" 1 "Elevation Speculative" 2 "Elevation Confident" 3 "Elevation Very Confident" ;
VAL_ 122 SRRLRCODPIOTk5MStsAuth 0 "No Object" 1 "New Object" 2 "Latent Track Not Detected this Cycle" 3 "Measured this Cycle" ;
VAL_ 122 SRRLRCODPIOTk5TypCnfdAuth 0 "Highly Speculative" 1 "Speculative" 2 "Confident" 3 "Highly Confident" ;
VAL_ 122 SRRLRCODPIOTk6CnfdStsAuth 0 "Highly Speculative" 1 "Speculative" 2 "Confident" 3 "Highly Confident" ;
VAL_ 122 SRRLRCODPIOTk6ElvtnAuth 0 "Not Elevated" 1 "Elevation Speculative" 2 "Elevation Confident" 3 "Elevation Very Confident" ;
VAL_ 122 SRRLRCODPIOTk6MStsAuth 0 "No Object" 1 "New Object" 2 "Latent Track Not Detected this Cycle" 3 "Measured this Cycle" ;
VAL_ 122 SRRLRCODPIOTk6TypCnfdAuth 0 "Highly Speculative" 1 "Speculative" 2 "Confident" 3 "Highly Confident" ;
VAL_ 122 SRRLRCODPIOTk7CnfdStsAuth 0 "Highly Speculative" 1 "Speculative" 2 "Confident" 3 "Highly Confident" ;
VAL_ 122 SRRLRCODPIOTk7ElvtnAuth 0 "Not Elevated" 1 "Elevation Speculative" 2 "Elevation Confident" 3 "Elevation Very Confident" ;
VAL_ 122 SRRLRCODPIOTk7MStsAuth 0 "No Object" 1 "New Object" 2 "Latent Track Not Detected this Cycle" 3 "Measured this Cycle" ;
VAL_ 122 SRRLRCODPIOTk7TypCnfdAuth 0 "Highly Speculative" 1 "Speculative" 2 "Confident" 3 "Highly Confident" ;
VAL_ 122 SRRLRCODPIOTk8CnfdStsAuth 0 "Highly Speculative" 1 "Speculative" 2 "Confident" 3 "Highly Confident" ;
VAL_ 122 SRRLRCODPIOTk8ElvtnAuth 0 "Not Elevated" 1 "Elevation Speculative" 2 "Elevation Confident" 3 "Elevation Very Confident" ;
VAL_ 122 SRRLRCODPIOTk8MStsAuth 0 "No Object" 1 "New Object" 2 "Latent Track Not Detected this Cycle" 3 "Measured this Cycle" ;
VAL_ 122 SRRLRCODPIOTk8TypCnfdAuth 0 "Highly Speculative" 1 "Speculative" 2 "Confident" 3 "Highly Confident" ;
VAL_ 122 SRRLRCODPIOTk9CnfdStsAuth 0 "Highly Speculative" 1 "Speculative" 2 "Confident" 3 "Highly Confident" ;
VAL_ 122 SRRLRCODPIOTk9ElvtnAuth 0 "Not Elevated" 1 "Elevation Speculative" 2 "Elevation Confident" 3 "Elevation Very Confident" ;
VAL_ 122 SRRLRCODPIOTk9MStsAuth 0 "No Object" 1 "New Object" 2 "Latent Track Not Detected this Cycle" 3 "Measured this Cycle" ;
VAL_ 122 SRRLRCODPIOTk9TypCnfdAuth 0 "Highly Speculative" 1 "Speculative" 2 "Confident" 3 "Highly Confident" ;
VAL_ 122 SRRLRCODPMdCmdStsAuth 0 "Not Radiating" 1 "Reporting Object Data" 2 "Not Reporting Object Data" ;
VAL_ 122 SRRLRCODPPOTk1CnfdStsAuth 0 "Highly Speculative" 1 "Speculative" 2 "Confident" 3 "Highly Confident" ;
VAL_ 122 SRRLRCODPPOTk1MStsAuth 0 "No Object" 1 "New Object" 2 "Latent Track Not Detected this Cycle" 3 "Measured this Cycle" ;
VAL_ 122 SRRLRCODPPOTk1TypAuth 0 "Unknown" 1 "Pedestrian" 2 "Bicycle" ;
VAL_ 122 SRRLRCODPPOTk1TypCnfdAuth 0 "Highly Speculative" 1 "Speculative" 2 "Confident" 3 "Highly Confident" ;
VAL_ 122 SRRLRCODPPOTk2CnfdStsAuth 0 "Highly Speculative" 1 "Speculative" 2 "Confident" 3 "Highly Confident" ;
VAL_ 122 SRRLRCODPPOTk2MStsAuth 0 "No Object" 1 "New Object" 2 "Latent Track Not Detected this Cycle" 3 "Measured this Cycle" ;
VAL_ 122 SRRLRCODPPOTk2TypAuth 0 "Unknown" 1 "Pedestrian" 2 "Bicycle" ;
VAL_ 122 SRRLRCODPPOTk2TypCnfdAuth 0 "Highly Speculative" 1 "Speculative" 2 "Confident" 3 "Highly Confident" ;
VAL_ 122 SRRLRCODPPOTk3CnfdStsAuth 0 "Highly Speculative" 1 "Speculative" 2 "Confident" 3 "Highly Confident" ;
VAL_ 122 SRRLRCODPPOTk3MStsAuth 0 "No Object" 1 "New Object" 2 "Latent Track Not Detected this Cycle" 3 "Measured this Cycle" ;
VAL_ 122 SRRLRCODPPOTk3TypAuth 0 "Unknown" 1 "Pedestrian" 2 "Bicycle" ;
VAL_ 122 SRRLRCODPPOTk3TypCnfdAuth 0 "Highly Speculative" 1 "Speculative" 2 "Confident" 3 "Highly Confident" ;
VAL_ 122 SRRLRCODPPOTk4CnfdStsAuth 0 "Highly Speculative" 1 "Speculative" 2 "Confident" 3 "Highly Confident" ;
VAL_ 122 SRRLRCODPPOTk4MStsAuth 0 "No Object" 1 "New Object" 2 "Latent Track Not Detected this Cycle" 3 "Measured this Cycle" ;
VAL_ 122 SRRLRCODPPOTk4TypAuth 0 "Unknown" 1 "Pedestrian" 2 "Bicycle" ;
VAL_ 122 SRRLRCODPPOTk4TypCnfdAuth 0 "Highly Speculative" 1 "Speculative" 2 "Confident" 3 "Highly Confident" ;
VAL_ 122 SRRLRCODPPOTk5CnfdStsAuth 0 "Highly Speculative" 1 "Speculative" 2 "Confident" 3 "Highly Confident" ;
VAL_ 122 SRRLRCODPPOTk5MStsAuth 0 "No Object" 1 "New Object" 2 "Latent Track Not Detected this Cycle" 3 "Measured this Cycle" ;
VAL_ 122 SRRLRCODPPOTk5TypAuth 0 "Unknown" 1 "Pedestrian" 2 "Bicycle" ;
VAL_ 122 SRRLRCODPPOTk5TypCnfdAuth 0 "Highly Speculative" 1 "Speculative" 2 "Confident" 3 "Highly Confident" ;
VAL_ 122 SRRLRCODPREOTk1CnfdStsAuth 0 "Highly Speculative" 1 "Speculative" 2 "Confident" 3 "Highly Confident" ;
VAL_ 122 SRRLRCODPREOTk1TypCnfdAuth 0 "Highly Speculative" 1 "Speculative" 2 "Confident" 3 "Highly Confident" ;
VAL_ 122 SRRLRCODPREOTk2CnfdStsAuth 0 "Highly Speculative" 1 "Speculative" 2 "Confident" 3 "Highly Confident" ;
VAL_ 122 SRRLRCODPREOTk2TypCnfdAuth 0 "Highly Speculative" 1 "Speculative" 2 "Confident" 3 "Highly Confident" ;
VAL_ 122 SRRLRCODPREOTk3CnfdStsAuth 0 "Highly Speculative" 1 "Speculative" 2 "Confident" 3 "Highly Confident" ;
VAL_ 122 SRRLRCODPREOTk3TypCnfdAuth 0 "Highly Speculative" 1 "Speculative" 2 "Confident" 3 "Highly Confident" ;
VAL_ 122 SRRLRCODPRdTypCnfdAuth 0 "Highly Speculative" 1 "Speculative" 2 "Confident" 3 "Highly Confident" ;
VAL_ 122 SRRLRCODPSwpBndwdthStsAuth 0 "Mode A" 1 "Mode B" 2 "Mode C" 3 "Mode D" ;
VAL_ 122 SRRLRCODPVOTk10CnfdStsAuth 0 "Highly Speculative" 1 "Speculative" 2 "Confident" 3 "Highly Confident" ;
VAL_ 122 SRRLRCODPVOTk10MStsAuth 0 "No Object" 1 "New Object" 2 "Latent Track Not Detected this Cycle" 3 "Measured this Cycle" ;
VAL_ 122 SRRLRCODPVOTk10TypCnfdAuth 0 "Highly Speculative" 1 "Speculative" 2 "Confident" 3 "Highly Confident" ;
VAL_ 122 SRRLRCODPVOTk1CnfdStsAuth 0 "Highly Speculative" 1 "Speculative" 2 "Confident" 3 "Highly Confident" ;
VAL_ 122 SRRLRCODPVOTk1MStsAuth 0 "No Object" 1 "New Object" 2 "Latent Track Not Detected this Cycle" 3 "Measured this Cycle" ;
VAL_ 122 SRRLRCODPVOTk1TypCnfdAuth 0 "Highly Speculative" 1 "Speculative" 2 "Confident" 3 "Highly Confident" ;
VAL_ 122 SRRLRCODPVOTk2CnfdStsAuth 0 "Highly Speculative" 1 "Speculative" 2 "Confident" 3 "Highly Confident" ;
VAL_ 122 SRRLRCODPVOTk2MStsAuth 0 "No Object" 1 "New Object" 2 "Latent Track Not Detected this Cycle" 3 "Measured this Cycle" ;
VAL_ 122 SRRLRCODPVOTk2TypCnfdAuth 0 "Highly Speculative" 1 "Speculative" 2 "Confident" 3 "Highly Confident" ;
VAL_ 122 SRRLRCODPVOTk3CnfdStsAuth 0 "Highly Speculative" 1 "Speculative" 2 "Confident" 3 "Highly Confident" ;
VAL_ 122 SRRLRCODPVOTk3MStsAuth 0 "No Object" 1 "New Object" 2 "Latent Track Not Detected this Cycle" 3 "Measured this Cycle" ;
VAL_ 122 SRRLRCODPVOTk3TypCnfdAuth 0 "Highly Speculative" 1 "Speculative" 2 "Confident" 3 "Highly Confident" ;
VAL_ 122 SRRLRCODPVOTk4CnfdStsAuth 0 "Highly Speculative" 1 "Speculative" 2 "Confident" 3 "Highly Confident" ;
VAL_ 122 SRRLRCODPVOTk4MStsAuth 0 "No Object" 1 "New Object" 2 "Latent Track Not Detected this Cycle" 3 "Measured this Cycle" ;
VAL_ 122 SRRLRCODPVOTk4TypCnfdAuth 0 "Highly Speculative" 1 "Speculative" 2 "Confident" 3 "Highly Confident" ;
VAL_ 122 SRRLRCODPVOTk5CnfdStsAuth 0 "Highly Speculative" 1 "Speculative" 2 "Confident" 3 "Highly Confident" ;
VAL_ 122 SRRLRCODPVOTk5MStsAuth 0 "No Object" 1 "New Object" 2 "Latent Track Not Detected this Cycle" 3 "Measured this Cycle" ;
VAL_ 122 SRRLRCODPVOTk5TypCnfdAuth 0 "Highly Speculative" 1 "Speculative" 2 "Confident" 3 "Highly Confident" ;
VAL_ 122 SRRLRCODPVOTk6CnfdStsAuth 0 "Highly Speculative" 1 "Speculative" 2 "Confident" 3 "Highly Confident" ;
VAL_ 122 SRRLRCODPVOTk6MStsAuth 0 "No Object" 1 "New Object" 2 "Latent Track Not Detected this Cycle" 3 "Measured this Cycle" ;
VAL_ 122 SRRLRCODPVOTk6TypCnfdAuth 0 "Highly Speculative" 1 "Speculative" 2 "Confident" 3 "Highly Confident" ;
VAL_ 122 SRRLRCODPVOTk7CnfdStsAuth 0 "Highly Speculative" 1 "Speculative" 2 "Confident" 3 "Highly Confident" ;
VAL_ 122 SRRLRCODPVOTk7MStsAuth 0 "No Object" 1 "New Object" 2 "Latent Track Not Detected this Cycle" 3 "Measured this Cycle" ;
VAL_ 122 SRRLRCODPVOTk7TypCnfdAuth 0 "Highly Speculative" 1 "Speculative" 2 "Confident" 3 "Highly Confident" ;
VAL_ 122 SRRLRCODPVOTk8CnfdStsAuth 0 "Highly Speculative" 1 "Speculative" 2 "Confident" 3 "Highly Confident" ;
VAL_ 122 SRRLRCODPVOTk8MStsAuth 0 "No Object" 1 "New Object" 2 "Latent Track Not Detected this Cycle" 3 "Measured this Cycle" ;
VAL_ 122 SRRLRCODPVOTk8TypCnfdAuth 0 "Highly Speculative" 1 "Speculative" 2 "Confident" 3 "Highly Confident" ;
VAL_ 122 SRRLRCODPVOTk9CnfdStsAuth 0 "Highly Speculative" 1 "Speculative" 2 "Confident" 3 "Highly Confident" ;
VAL_ 122 SRRLRCODPVOTk9MStsAuth 0 "No Object" 1 "New Object" 2 "Latent Track Not Detected this Cycle" 3 "Measured this Cycle" ;
VAL_ 122 SRRLRCODPVOTk9TypCnfdAuth 0 "Highly Speculative" 1 "Speculative" 2 "Confident" 3 "Highly Confident" ;
VAL_ 122 SRRLRCODPAcqTmStmAuth_Inv 0 "FALSE" 1 "TRUE" ;
VAL_ 122 SRRLRCODPServRqrdAuth 0 "FALSE" 1 "TRUE" ;
VAL_ 122 SRRLRCODPSnsrBlckdAuth 0 "FALSE" 1 "TRUE" ;
VAL_ 122 SRRLRCODPSnsrUnvAuth 0 "FALSE" 1 "TRUE" ;
VAL_ 122 SRRLRCODPVOTk10DynPrpStsAuth 0 "Stopped" 1 "Not Stopped" ;
VAL_ 122 SRRLRCODPVOTk1DynPrpStsAuth 0 "Stopped" 1 "Not Stopped" ;
VAL_ 122 SRRLRCODPVOTk2DynPrpStsAuth 0 "Stopped" 1 "Not Stopped" ;
VAL_ 122 SRRLRCODPVOTk3DynPrpStsAuth 0 "Stopped" 1 "Not Stopped" ;
VAL_ 122 SRRLRCODPVOTk4DynPrpStsAuth 0 "Stopped" 1 "Not Stopped" ;
VAL_ 122 SRRLRCODPVOTk5DynPrpStsAuth 0 "Stopped" 1 "Not Stopped" ;
VAL_ 122 SRRLRCODPVOTk6DynPrpStsAuth 0 "Stopped" 1 "Not Stopped" ;
VAL_ 122 SRRLRCODPVOTk7DynPrpStsAuth 0 "Stopped" 1 "Not Stopped" ;
VAL_ 122 SRRLRCODPVOTk8DynPrpStsAuth 0 "Stopped" 1 "Not Stopped" ;
VAL_ 122 SRRLRCODPVOTk9DynPrpStsAuth 0 "Stopped" 1 "Not Stopped" ;
